VERSION ""

NS_ :

BS_:

BU_: VMCU TECU OBDScanT2 IC3 HPCU EMS ECUspare2 ECUspare1 DACU CIOM BBM

BO_ 1414 HMIIOM_BB2_19P_EMS: 21 IC3
 SG_ GPSData_Altitude_ISig_4_586 : 144|16@1+ (0.125,-2500) [-2500|5691.875] "m"  EMS
 SG_ GPSData_Longitude_ISig_4_586 : 0|32@1+ (1E-007,-210) [-210|219.4967295] "deg"  EMS
 SG_ GPSData_HDOP_ISig_4_586 : 112|16@1+ (0.01,0) [0|655.35] ""  EMS
 SG_ GPSData_sg_UB_ISig_4_586 : 163|1@1+ (1,0) [0|1] ""  EMS
 SG_ GPSData_Direction_ISig_4_586 : 96|16@1+ (0.0078125,0) [0|511.9921875] "deg"  EMS
 SG_ GPSData_Time_ISig_4_586 : 64|32@1+ (1,0) [0|4294967295] "s"  EMS
 SG_ GPSData_VehSpeed_ISig_4_586 : 128|16@1+ (0.00390625,0) [0|255.99609375] "Km_per_h"  EMS
 SG_ GPSData_AntennaStat_ISig_4_586 : 160|3@1+ (1,0) [0|0] ""  EMS
 SG_ GPSData_Latitude_ISig_4_586 : 32|32@1+ (1E-007,-210) [-210|219.4967295] "deg"  EMS

BO_ 1382 HMIIOM_BB2_19P_DACU_FCM: 8 DACU
 SG_ HMIIOM_BB2_19P_FCS_566 : 0|64@1+ (1,0) [0|0] ""  IC3

BO_ 1381 HMIIOM_BB2_19P_DACU: 21 IC3
 SG_ GPSData_HDOP_ISig_4_565 : 112|16@1+ (0.01,0) [0|655.35] ""  DACU
 SG_ GPSData_VehSpeed_ISig_4_565 : 128|16@1+ (0.00390625,0) [0|255.99609375] "Km_per_h"  DACU
 SG_ GPSData_sg_UB_ISig_4_565 : 163|1@1+ (1,0) [0|1] ""  DACU
 SG_ GPSData_AntennaStat_ISig_4_565 : 160|3@1+ (1,0) [0|0] ""  DACU
 SG_ GPSData_Latitude_ISig_4_565 : 32|32@1+ (1E-007,-210) [-210|219.4967295] "deg"  DACU
 SG_ GPSData_Time_ISig_4_565 : 64|32@1+ (1,0) [0|4294967295] "s"  DACU
 SG_ GPSData_Direction_ISig_4_565 : 96|16@1+ (0.0078125,0) [0|511.9921875] "deg"  DACU
 SG_ GPSData_Longitude_ISig_4_565 : 0|32@1+ (1E-007,-210) [-210|219.4967295] "deg"  DACU
 SG_ GPSData_Altitude_ISig_4_565 : 144|16@1+ (0.125,-2500) [-2500|5691.875] "m"  DACU

BO_ 1387 HMIIOM_BB2_19P_CIOM_FCM: 8 CIOM
 SG_ HMIIOM_BB2_19P_FCS_56b : 0|64@1+ (1,0) [0|0] ""  IC3

BO_ 1386 HMIIOM_BB2_19P_CIOM: 21 IC3
 SG_ GPSData_HDOP_ISig_4_56a : 112|16@1+ (0.01,0) [0|655.35] ""  CIOM
 SG_ GPSData_Latitude_ISig_4_56a : 32|32@1+ (1E-007,-210) [-210|219.4967295] "deg"  CIOM
 SG_ GPSData_Time_ISig_4_56a : 64|32@1+ (1,0) [0|4294967295] "s"  CIOM
 SG_ GPSData_Direction_ISig_4_56a : 96|16@1+ (0.0078125,0) [0|511.9921875] "deg"  CIOM
 SG_ GPSData_sg_UB_ISig_4_56a : 163|1@1+ (1,0) [0|1] ""  CIOM
 SG_ GPSData_AntennaStat_ISig_4_56a : 160|3@1+ (1,0) [0|0] ""  CIOM
 SG_ GPSData_Longitude_ISig_4_56a : 0|32@1+ (1E-007,-210) [-210|219.4967295] "deg"  CIOM
 SG_ GPSData_VehSpeed_ISig_4_56a : 128|16@1+ (0.00390625,0) [0|255.99609375] "Km_per_h"  CIOM
 SG_ GPSData_Altitude_ISig_4_56a : 144|16@1+ (0.125,-2500) [-2500|5691.875] "m"  CIOM

BO_ 1385 HMIIOM_BB2_19P_BBM_FCM: 8 BBM
 SG_ HMIIOM_BB2_19P_FCS_569 : 0|64@1+ (1,0) [0|0] ""  IC3

BO_ 1384 HMIIOM_BB2_19P_BBM: 21 IC3
 SG_ GPSData_Time_ISig_4_568 : 64|32@1+ (1,0) [0|4294967295] "s"  BBM
 SG_ GPSData_HDOP_ISig_4_568 : 112|16@1+ (0.01,0) [0|655.35] ""  BBM
 SG_ GPSData_Direction_ISig_4_568 : 96|16@1+ (0.0078125,0) [0|511.9921875] "deg"  BBM
 SG_ GPSData_Longitude_ISig_4_568 : 0|32@1+ (1E-007,-210) [-210|219.4967295] "deg"  BBM
 SG_ GPSData_sg_UB_ISig_4_568 : 163|1@1+ (1,0) [0|1] ""  BBM
 SG_ GPSData_VehSpeed_ISig_4_568 : 128|16@1+ (0.00390625,0) [0|255.99609375] "Km_per_h"  BBM
 SG_ GPSData_Altitude_ISig_4_568 : 144|16@1+ (0.125,-2500) [-2500|5691.875] "m"  BBM
 SG_ GPSData_Latitude_ISig_4_568 : 32|32@1+ (1E-007,-210) [-210|219.4967295] "deg"  BBM
 SG_ GPSData_AntennaStat_ISig_4_568 : 160|3@1+ (1,0) [0|0] ""  BBM

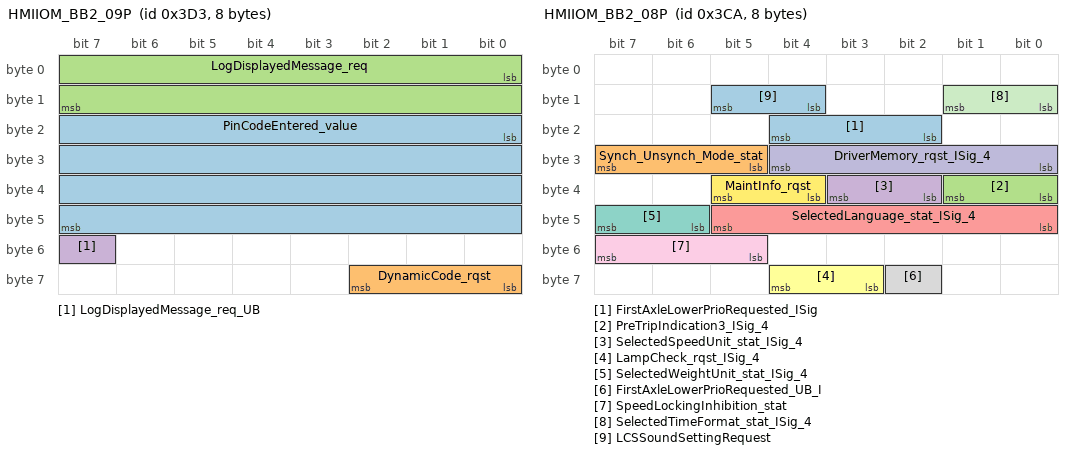
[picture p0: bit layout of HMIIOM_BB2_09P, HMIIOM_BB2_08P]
BO_ 979 HMIIOM_BB2_09P: 8 IC3
 SG_ PinCodeEntered_value : 16|32@1+ (1,0) [0|4294967295] "NotApplicable"  CIOM
 SG_ DynamicCode_rqst : 56|3@1+ (1,0) [0|0] ""  CIOM
 SG_ LogDisplayedMessage_req : 0|16@1+ (1,0) [0|65535] "NotApplicable"  VMCU
 SG_ LogDisplayedMessage_req_UB : 55|1@1+ (1,0) [0|0] ""  VMCU

BO_ 970 HMIIOM_BB2_08P: 8 IC3
 SG_ FirstAxleLowerPrioRequested_ISig : 18|3@1+ (1,0) [0|0] ""  VMCU
 SG_ Synch_Unsynch_Mode_stat : 29|3@1+ (1,0) [0|0] ""  CIOM
 SG_ PreTripIndication3_ISig_4 : 32|2@1+ (1,0) [0|0] ""  CIOM
 SG_ SelectedSpeedUnit_stat_ISig_4 : 34|2@1+ (1,0) [0|0] ""  VMCU
 SG_ SelectedLanguage_stat_ISig_4 : 40|6@1+ (1,0) [0|0] ""  BBM,CIOM
 SG_ LampCheck_rqst_ISig_4 : 59|2@1+ (1,0) [0|0] ""  VMCU
 SG_ SelectedWeightUnit_stat_ISig_4 : 46|2@1+ (1,0) [0|0] ""  CIOM
 SG_ FirstAxleLowerPrioRequested_UB_I : 58|1@1+ (1,0) [0|0] ""  VMCU
 SG_ SpeedLockingInhibition_stat : 53|3@1+ (1,0) [0|0] ""  CIOM
 SG_ DriverMemory_rqst_ISig_4 : 24|5@1+ (1,0) [0|0] ""  CIOM,VMCU
 SG_ SelectedTimeFormat_stat_ISig_4 : 8|2@1+ (1,0) [0|0] ""  CIOM
 SG_ MaintInfo_rqst : 36|2@1+ (1,0) [0|0] ""  VMCU
 SG_ LCSSoundSettingRequest : 12|2@1+ (1,0) [0|0] ""  DACU

BO_ 851 HMIIOM_BB2_07P: 8 IC3
 SG_ BunkBacklightCmd_ISig_4 : 16|5@1+ (1,0) [0|0] ""  CIOM

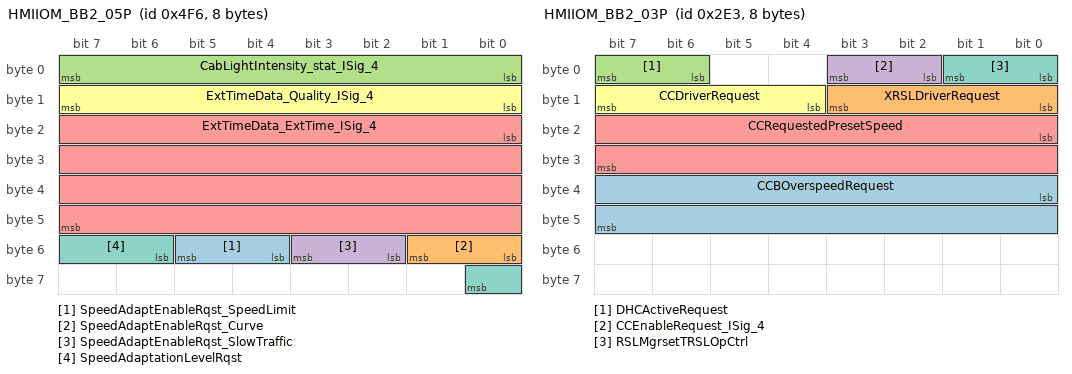
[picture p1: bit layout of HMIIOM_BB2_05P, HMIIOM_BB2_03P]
BO_ 1270 HMIIOM_BB2_05P: 8 IC3
 SG_ SpeedAdaptEnableRqst_SpeedLimit : 52|2@1+ (1,0) [0|0] ""  DACU,TECU
 SG_ SpeedAdaptEnableRqst_Curve : 48|2@1+ (1,0) [0|0] ""  TECU,DACU
 SG_ CabLightIntensity_stat_ISig_4 : 0|8@1+ (0.4,0) [0|102] "Percent"  BBM,DACU
 SG_ SpeedAdaptEnableRqst_SlowTraffic : 50|2@1+ (1,0) [0|0] ""  DACU,TECU
 SG_ ExtTimeData_ExtTime_ISig_4 : 16|32@1+ (1,0) [0|4294967295] "s"  VMCU
 SG_ ExtTimeData_Quality_ISig_4 : 8|8@1+ (1,0) [0|255] "h"  VMCU
 SG_ SpeedAdaptationLevelRqst : 54|3@1+ (1,0) [0|0] ""  DACU,TECU

BO_ 739 HMIIOM_BB2_03P: 8 IC3
 SG_ CCBOverspeedRequest : 32|16@1+ (0.00390625,0) [0|255.99609375] "Km_per_h"  VMCU
 SG_ XRSLDriverRequest : 8|4@1+ (1,0) [0|0] ""  VMCU
 SG_ DHCActiveRequest : 6|2@1+ (1,0) [0|0] ""  VMCU
 SG_ CCEnableRequest_ISig_4 : 2|2@1+ (1,0) [0|0] ""  CIOM,VMCU,BBM
 SG_ CCRequestedPresetSpeed : 16|16@1+ (0.00390625,0) [0|255.99609375] "Km_per_h"  VMCU
 SG_ CCDriverRequest : 12|4@1+ (1,0) [0|0] ""  VMCU,BBM
 SG_ RSLMgrsetTRSLOpCtrl : 0|2@1+ (1,0) [0|0] ""  VMCU

BO_ 390 HMIIOM_BB2_02P: 8 IC3
 SG_ EcoRollEnableRequest_ISig_4 : 6|2@1+ (1,0) [0|0] ""  TECU
 SG_ SelectedEcoCruiseLevel_ISig_4 : 40|3@1+ (1,0) [0|0] ""  EMS,DACU,TECU,VMCU

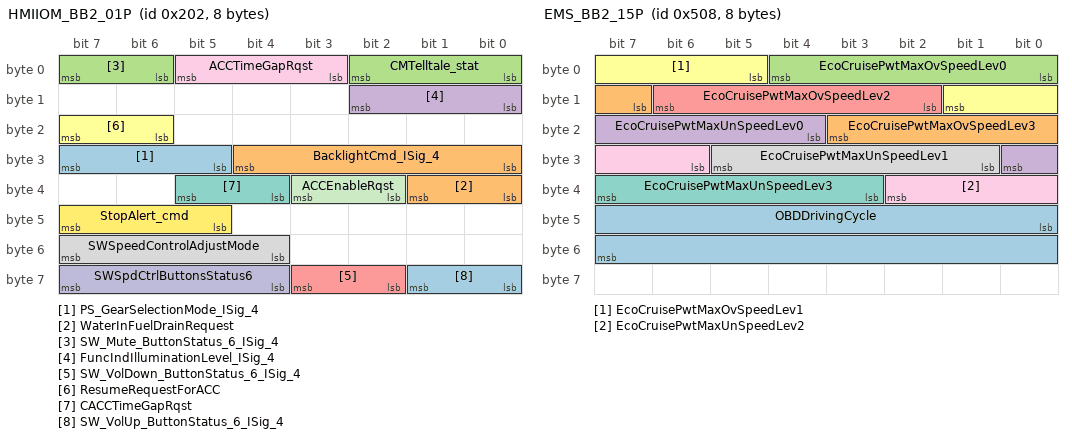
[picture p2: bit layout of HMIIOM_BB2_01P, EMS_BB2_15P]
BO_ 514 HMIIOM_BB2_01P: 8 IC3
 SG_ PS_GearSelectionMode_ISig_4 : 29|3@1+ (1,0) [0|0] ""  VMCU
 SG_ WaterInFuelDrainRequest : 32|2@1+ (1,0) [0|0] ""  EMS
 SG_ SW_Mute_ButtonStatus_6_ISig_4 : 6|2@1+ (1,0) [0|0] ""  BBM
 SG_ FuncIndIlluminationLevel_ISig_4 : 8|3@1+ (1,0) [0|0] ""  DACU,VMCU,CIOM
 SG_ SW_VolDown_ButtonStatus_6_ISig_4 : 58|2@1+ (1,0) [0|0] ""  BBM
 SG_ ResumeRequestForACC : 22|2@1+ (1,0) [0|0] ""  DACU
 SG_ CACCTimeGapRqst : 36|2@1+ (1,0) [0|0] ""  DACU
 SG_ SWSpeedControlAdjustMode : 52|4@1+ (1,0) [0|0] ""  VMCU,CIOM
 SG_ ACCTimeGapRqst : 3|3@1+ (1,0) [0|0] ""  DACU
 SG_ SWSpdCtrlButtonsStatus6 : 60|4@1+ (1,0) [0|0] ""  CIOM,BBM
 SG_ ACCEnableRqst : 34|2@1+ (1,0) [0|0] ""  VMCU,DACU,CIOM
 SG_ StopAlert_cmd : 45|3@1+ (1,0) [0|0] ""  VMCU
 SG_ SW_VolUp_ButtonStatus_6_ISig_4 : 56|2@1+ (1,0) [0|0] ""  BBM
 SG_ BacklightCmd_ISig_4 : 24|5@1+ (1,0) [0|0] ""  CIOM,DACU,VMCU
 SG_ CMTelltale_stat : 0|3@1+ (1,0) [0|0] ""  DACU

BO_ 1288 EMS_BB2_15P: 8 EMS
 SG_ OBDDrivingCycle : 40|16@1+ (1,0) [0|0] ""  VMCU
 SG_ EcoCruisePwtMaxOvSpeedLev3 : 15|5@1+ (1,0) [0|31] "Km_per_h"  VMCU
 SG_ EcoCruisePwtMaxOvSpeedLev0 : 0|5@1+ (1,0) [0|31] "Km_per_h"  VMCU
 SG_ EcoCruisePwtMaxUnSpeedLev0 : 20|5@1+ (1,0) [0|31] "Km_per_h"  VMCU
 SG_ EcoCruisePwtMaxOvSpeedLev2 : 10|5@1+ (1,0) [0|31] "Km_per_h"  VMCU
 SG_ EcoCruisePwtMaxOvSpeedLev1 : 5|5@1+ (1,0) [0|31] "Km_per_h"  VMCU
 SG_ EcoCruisePwtMaxUnSpeedLev3 : 35|5@1+ (1,0) [0|31] "Km_per_h"  VMCU
 SG_ EcoCruisePwtMaxUnSpeedLev1 : 25|5@1+ (1,0) [0|31] "Km_per_h"  VMCU
 SG_ EcoCruisePwtMaxUnSpeedLev2 : 30|5@1+ (1,0) [0|31] "Km_per_h"  VMCU

BO_ 1285 EMS_BB2_14P: 8 EMS
 SG_ TotPTOLNGHighAccuracy : 0|32@1+ (0.01,0) [0|42949672.95] "kg"  VMCU

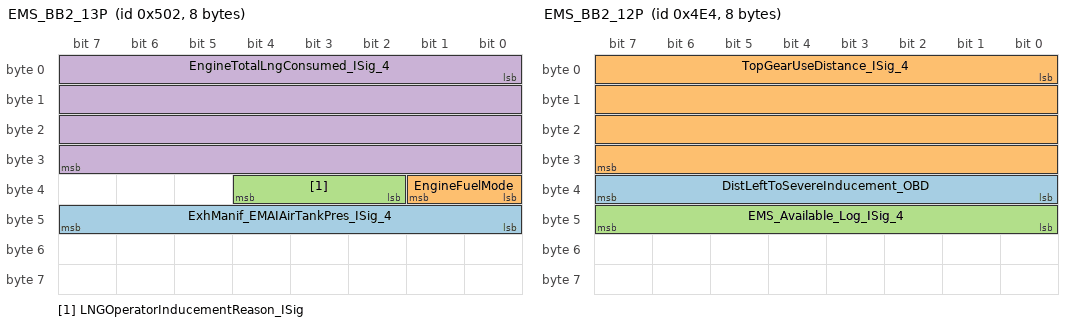
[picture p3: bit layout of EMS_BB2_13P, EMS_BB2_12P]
BO_ 1282 EMS_BB2_13P: 8 EMS
 SG_ ExhManif_EMAIAirTankPres_ISig_4 : 40|8@1+ (8,0) [0|2040] "kPa"  VMCU
 SG_ EngineFuelMode : 32|2@1+ (1,0) [0|0] ""  VMCU
 SG_ LNGOperatorInducementReason_ISig : 34|3@1+ (1,0) [0|0] ""  IC3
 SG_ EngineTotalLngConsumed_ISig_4 : 0|32@1+ (0.01,0) [0|42949672.95] "kg"  CIOM,IC3,VMCU

BO_ 1252 EMS_BB2_12P: 8 EMS
 SG_ DistLeftToSevereInducement_OBD : 32|8@1+ (5,0) [0|1275] "km"  IC3
 SG_ TopGearUseDistance_ISig_4 : 0|32@1+ (0.01,0) [0|42949672.95] "km"  IC3
 SG_ EMS_Available_Log_ISig_4 : 40|8@1+ (1,0) [0|0] ""  IC3

BO_ 961 EMS_BB2_11S_FCM: 8 CIOM
 SG_ EMS_BB2_11S_FCS : 0|64@1+ (1,0) [0|0] ""  EMS

BO_ 958 EMS_BB2_11S: 16 EMS
 SG_ KeyID_EngineStartAuth : 0|128@1+ (1,0) [0|0] ""  CIOM

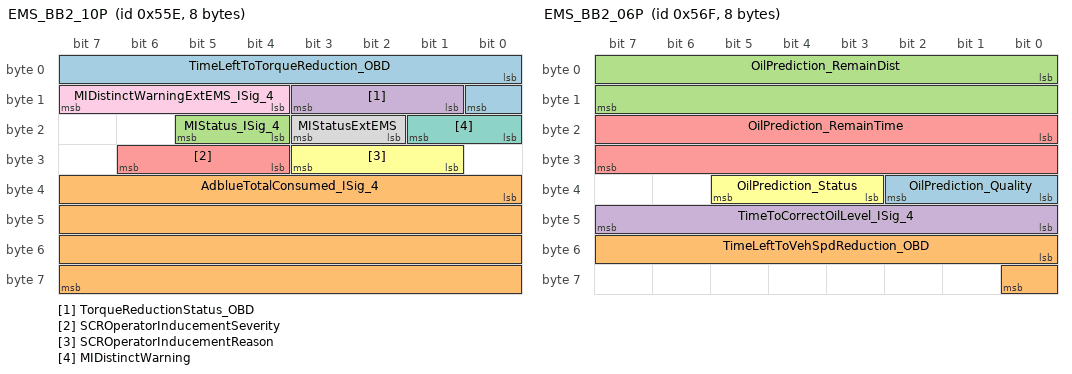
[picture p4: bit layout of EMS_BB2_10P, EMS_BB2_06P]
BO_ 1374 EMS_BB2_10P: 8 EMS
 SG_ TimeLeftToTorqueReduction_OBD : 0|9@1+ (12,0) [0|6132] "min"  IC3
 SG_ AdblueTotalConsumed_ISig_4 : 32|32@1+ (0.01,0) [0|42949672.95] "l"  VMCU,IC3
 SG_ MIStatus_ISig_4 : 20|2@1+ (1,0) [0|0] ""  VMCU,IC3
 SG_ TorqueReductionStatus_OBD : 9|3@1+ (1,0) [0|0] ""  IC3
 SG_ SCROperatorInducementSeverity : 28|3@1+ (1,0) [0|0] ""  IC3
 SG_ SCROperatorInducementReason : 25|3@1+ (1,0) [0|0] ""  IC3
 SG_ MIDistinctWarning : 16|2@1+ (1,0) [0|0] ""  VMCU,IC3
 SG_ MIStatusExtEMS : 18|2@1+ (1,0) [0|0] ""  IC3
 SG_ MIDistinctWarningExtEMS_ISig_4 : 12|4@1+ (1,0) [0|0] ""  VMCU,IC3

BO_ 1342 EMS_BB2_09S_FCM: 8 CIOM
 SG_ EMS_BB2_09S_FCS : 0|64@1+ (1,0) [0|0] ""  EMS

BO_ 1341 EMS_BB2_09S: 11 EMS
 SG_ ECU4VIN_stat : 0|88@1+ (1,0) [0|0] ""  CIOM

BO_ 1392 EMS_BB2_08P: 8 EMS
 SG_ EngineRunningTime_ISig_4 : 0|32@1+ (1,0) [0|4294967295] "s"  BBM,IC3,VMCU,CIOM
 SG_ TotPTOFuelHighAccuracy : 32|32@1+ (0.01,0) [0|42949672.95] "l"  VMCU

BO_ 1391 EMS_BB2_06P: 8 EMS
 SG_ OilPrediction_Quality : 32|3@1+ (1,0) [0|0] ""  CIOM,VMCU
 SG_ TimeLeftToVehSpdReduction_OBD : 48|9@1+ (15,0) [0|7665] "min"  IC3
 SG_ OilPrediction_RemainDist : 0|16@1+ (10,0) [0|655350] "km"  CIOM,VMCU
 SG_ TimeToCorrectOilLevel_ISig_4 : 40|8@1+ (1,0) [0|255] "min"  IC3
 SG_ OilPrediction_RemainTime : 16|16@1+ (1,0) [0|65535] "h"  VMCU,CIOM
 SG_ OilPrediction_Status : 35|3@1+ (1,0) [0|0] ""  CIOM,VMCU

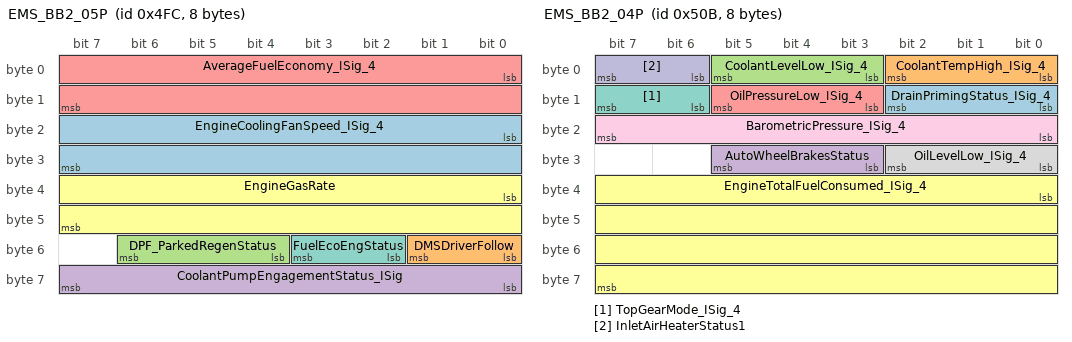
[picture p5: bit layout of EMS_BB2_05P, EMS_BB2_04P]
BO_ 1276 EMS_BB2_05P: 8 EMS
 SG_ EngineCoolingFanSpeed_ISig_4 : 16|16@1+ (1,0) [0|65535] "rpm"  CIOM
 SG_ DMSDriverFollow : 48|2@1+ (1,0) [0|0] ""  VMCU
 SG_ DPF_ParkedRegenStatus : 52|3@1+ (1,0) [0|0] ""  IC3
 SG_ CoolantPumpEngagementStatus_ISig : 56|8@1+ (0.4,0) [0|102] "Percent"  CIOM
 SG_ AverageFuelEconomy_ISig_4 : 0|16@1+ (0.00390625,0) [0|255.99609375] "miles_per_gallon"  IC3
 SG_ EngineGasRate : 32|16@1+ (0.05,0) [0|3276.75] "Kg_per_h"  VMCU,CIOM
 SG_ FuelEcoEngStatus : 50|2@1+ (1,0) [0|0] ""  VMCU

BO_ 1291 EMS_BB2_04P: 8 EMS
 SG_ DrainPrimingStatus_ISig_4 : 8|3@1+ (1,0) [0|0] ""  IC3
 SG_ CoolantTempHigh_ISig_4 : 0|3@1+ (1,0) [0|0] ""  IC3,VMCU,BBM
 SG_ CoolantLevelLow_ISig_4 : 3|3@1+ (1,0) [0|0] ""  VMCU,BBM,IC3
 SG_ AutoWheelBrakesStatus : 27|3@1+ (1,0) [0|0] ""  IC3,TECU
 SG_ OilPressureLow_ISig_4 : 11|3@1+ (1,0) [0|0] ""  VMCU,IC3,BBM
 SG_ EngineTotalFuelConsumed_ISig_4 : 32|32@1+ (0.01,0) [0|42949672.95] "l"  IC3,BBM,CIOM,VMCU,TECU
 SG_ TopGearMode_ISig_4 : 14|2@1+ (1,0) [0|0] ""  IC3
 SG_ OilLevelLow_ISig_4 : 24|3@1+ (1,0) [0|0] ""  IC3,BBM
 SG_ BarometricPressure_ISig_4 : 16|8@1+ (0.5,0) [0|127.5] "kPa"  TECU,BBM,VMCU,CIOM
 SG_ InletAirHeaterStatus1 : 6|2@1+ (1,0) [0|0] ""  IC3

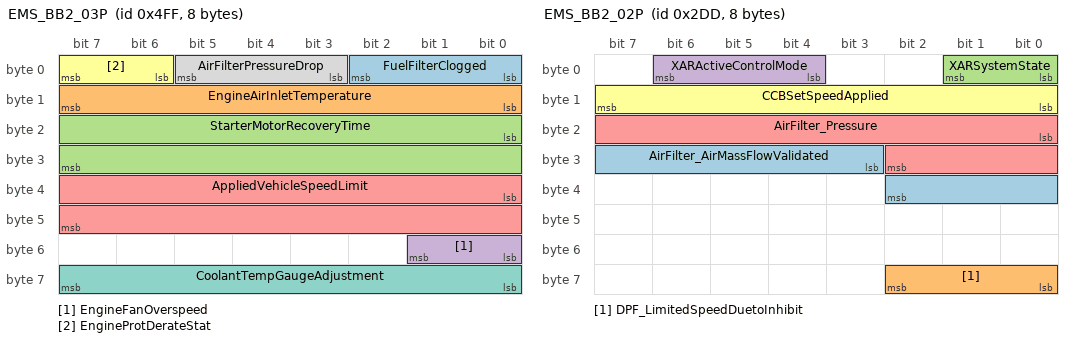
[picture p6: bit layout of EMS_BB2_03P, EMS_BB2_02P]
BO_ 1279 EMS_BB2_03P: 8 EMS
 SG_ FuelFilterClogged : 0|3@1+ (1,0) [0|0] ""  IC3
 SG_ EngineAirInletTemperature : 8|8@1+ (1,-40) [-40|215] "DegreeC"  VMCU
 SG_ StarterMotorRecoveryTime : 16|16@1+ (1,0) [0|65535] "s"  IC3
 SG_ EngineFanOverspeed : 48|2@1+ (1,0) [0|0] ""  IC3
 SG_ AppliedVehicleSpeedLimit : 32|16@1+ (0.00390625,0) [0|255.99609375] "Km_per_h"  VMCU,TECU
 SG_ EngineProtDerateStat : 6|2@1+ (1,0) [0|0] ""  VMCU
 SG_ CoolantTempGaugeAdjustment : 56|8@1+ (0.4,0) [0|102] "Percent"  IC3
 SG_ AirFilterPressureDrop : 3|3@1+ (1,0) [0|0] ""  VMCU

BO_ 733 EMS_BB2_02P: 8 EMS
 SG_ AirFilter_AirMassFlowValidated : 27|8@1+ (0.01,0) [0|2.55] "Kg_Per_s"  VMCU
 SG_ DPF_LimitedSpeedDuetoInhibit : 56|3@1+ (1,0) [0|0] ""  IC3
 SG_ XARSystemState : 0|2@1+ (1,0) [0|0] ""  DACU
 SG_ XARActiveControlMode : 4|3@1+ (1,0) [0|0] ""  DACU
 SG_ AirFilter_Pressure : 16|11@1+ (0.01,-10) [-10|10.47] "kPa"  VMCU
 SG_ CCBSetSpeedApplied : 8|8@1+ (1,0) [0|255] "Km_per_h"  VMCU,DACU

BO_ 719 EMS_BB2_01P: 8 EMS
 SG_ CCControllerMode_ISig_4 : 0|3@1+ (1,0) [0|0] ""  VMCU,IC3
 SG_ CrankcasePressureHigh_ISig_4 : 30|2@1+ (1,0) [0|0] ""  BBM
 SG_ EngineSystemPowerDownAck : 28|2@1+ (1,0) [0|0] ""  VMCU
 SG_ EngineActiveStatus_ISig_4 : 24|4@1+ (1,0) [0|0] ""  TECU,VMCU,DACU
 SG_ XRSLControllerMode : 19|2@1+ (1,0) [0|0] ""  VMCU,IC3
 SG_ RegenInhibDueHeight : 60|2@1+ (1,0) [0|0] ""  IC3
 SG_ ExhManif_AirInjActive_ISig_4 : 56|2@1+ (1,0) [0|0] ""  VMCU
 SG_ CCBControllerMode : 11|3@1+ (1,0) [0|0] ""  VMCU
 SG_ InhibitIdleShutdownStatus : 8|3@1+ (1,0) [0|0] ""  VMCU
 SG_ EngCompartmentStopSwitchStat : 6|2@1+ (1,0) [0|0] ""  VMCU
 SG_ EngineAirInletPressure : 32|8@1+ (2,0) [0|510] "kPa"  VMCU
 SG_ EngineStartAuth_rqst : 3|3@1+ (1,0) [0|0] ""  CIOM
 SG_ IntakeAirTemperatureAlert : 14|2@1+ (1,0) [0|0] ""  VMCU
 SG_ EngineOilTempHigh_ISig_4 : 16|3@1+ (1,0) [0|0] ""  BBM,IC3
 SG_ WarmUpCycle : 21|2@1+ (1,0) [0|0] ""  VMCU
 SG_ DeterminedGear : 48|8@1+ (1,-125) [-125|130] "GearValue"  VMCU
 SG_ CCSetSpeedApplied_ISig_4 : 40|8@1+ (1,0) [0|255] "Km_per_h"  IC3,DACU,VMCU

BO_ 2671964911 DiagUUDTRespMsg1_F2_EF_BB2: 8 HPCU
 SG_ DiagUUDTRespSig_F2_EF_ISig_4 : 0|64@1+ (1,0) [0|0] ""  VMCU

BO_ 2671964902 DiagUUDTRespMsg1_F2_E6_BB2: 8 BBM
 SG_ DiagUUDTRespSig_F2_E6_ISig_4 : 0|64@1+ (1,0) [0|0] ""  VMCU

BO_ 2671964901 DiagUUDTRespMsg1_F2_E5_BB2: 8 BBM
 SG_ DiagUUDTRespSig_F2_E5_ISig_4 : 0|64@1+ (1,0) [0|0] ""  VMCU

BO_ 2671964866 DiagUUDTRespMsg1_F2_C2_BB2: 8 HPCU
 SG_ DiagUUDTRespSig_F2_C2_ISig_4 : 0|64@1+ (1,0) [0|0] ""  VMCU

BO_ 2671964864 DiagUUDTRespMsg1_F2_C0_BB2: 8 CIOM
 SG_ DiagUUDTRespSig_F2_C0_ISig_4 : 0|64@1+ (1,0) [0|0] ""  VMCU

BO_ 2671964834 DiagUUDTRespMsg1_F2_A2_BB2: 8 CIOM
 SG_ DiagUUDTRespSig_F2_A2_ISig_4 : 0|64@1+ (1,0) [0|0] ""  VMCU

BO_ 2671964833 DiagUUDTRespMsg1_F2_A1_BB2: 8 CIOM
 SG_ DiagUUDTRespSig_F2_A1_ISig_4 : 0|64@1+ (1,0) [0|0] ""  VMCU

BO_ 2671964832 DiagUUDTRespMsg1_F2_A0_BB2: 8 CIOM
 SG_ DiagUUDTRespSig_F2_A0_ISig_4 : 0|64@1+ (1,0) [0|0] ""  VMCU

BO_ 2671964824 DiagUUDTRespMsg1_F2_98_BB2: 8 CIOM
 SG_ DiagUUDTRespSig_F2_98_ISig_4 : 0|64@1+ (1,0) [0|0] ""  VMCU

BO_ 2671964812 DiagUUDTRespMsg1_F2_8C_BB2: 8 DACU
 SG_ DiagUUDTRespSig_F2_8C_ISig_4 : 0|64@1+ (1,0) [0|0] ""  VMCU

BO_ 2671964803 DiagUUDTRespMsg1_F2_83_BB2: 8 IC3
 SG_ DiagUUDTRespSig_F2_83_ISig_4 : 0|64@1+ (1,0) [0|0] ""  VMCU

BO_ 2671964802 DiagUUDTRespMsg1_F2_82_BB2: 8 IC3
 SG_ DiagUUDTRespSig_F2_82_ISig_4 : 0|64@1+ (1,0) [0|0] ""  VMCU

BO_ 2671964772 DiagUUDTRespMsg1_F2_64_BB2: 8 IC3
 SG_ DiagUUDTRespSig_F2_64_ISig_4 : 0|64@1+ (1,0) [0|0] ""  VMCU

BO_ 2671964769 DiagUUDTRespMsg1_F2_61_BB2: 8 IC3
 SG_ DiagUUDTRespSig_F2_61_ISig_4 : 0|64@1+ (1,0) [0|0] ""  VMCU

BO_ 2671964768 DiagUUDTRespMsg1_F2_60_BB2: 8 IC3
 SG_ DiagUUDTRespSig_F2_60_ISig_4 : 0|64@1+ (1,0) [0|0] ""  VMCU

BO_ 2671964755 DiagUUDTRespMsg1_F2_53_BB2: 8 CIOM
 SG_ DiagUUDTRespSig_F2_53_ISig_4 : 0|64@1+ (1,0) [0|0] ""  VMCU

BO_ 2671964754 DiagUUDTRespMsg1_F2_52_BB2: 8 DACU
 SG_ DiagUUDTRespSig_F2_52_ISig_4 : 0|64@1+ (1,0) [0|0] ""  VMCU

BO_ 2671964753 DiagUUDTRespMsg1_F2_51_BB2: 8 DACU
 SG_ DiagUUDTRespSig_F2_51_ISig_4 : 0|64@1+ (1,0) [0|0] ""  VMCU

BO_ 2671964752 DiagUUDTRespMsg1_F2_50_BB2: 8 DACU
 SG_ DiagUUDTRespSig_F2_50_ISig_4 : 0|64@1+ (1,0) [0|0] ""  VMCU

BO_ 2671964737 DiagUUDTRespMsg1_F2_41_BB2: 8 IC3
 SG_ DiagUUDTRespSig_F2_41_ISig_4 : 0|64@1+ (1,0) [0|0] ""  VMCU

BO_ 2671964736 DiagUUDTRespMsg1_F2_40_BB2: 8 CIOM
 SG_ DiagUUDTRespSig_F2_40_ISig_4 : 0|64@1+ (1,0) [0|0] ""  VMCU

BO_ 2671964710 DiagUUDTRespMsg1_F2_26_BB2: 8 CIOM
 SG_ DiagUUDTRespSig_F2_26_ISig_4 : 0|64@1+ (1,0) [0|0] ""  VMCU

BO_ 2671964696 DiagUUDTRespMsg1_F2_18_BB2: 8 TECU
 SG_ DiagUUDTRespSig_F2_18_ISig_4 : 0|64@1+ (1,0) [0|0] ""  VMCU

BO_ 2671964688 DiagUUDTRespMsg1_F2_10_BB2: 8 EMS
 SG_ DiagUUDTRespSig_F2_10_ISig_4 : 0|64@1+ (1,0) [0|0] ""  VMCU

BO_ 2671834277 DiagRespMsgIntTGW_F4_A5_BB2: 8 VMCU
 SG_ InternalTesterDiagSig_F4_A5_ISig : 0|64@1+ (1,0) [0|0] ""  IC3

BO_ 2671834227 DiagRespMsgIntTGW_F4_73_BB2: 8 VMCU
 SG_ InternalTesterDiagSig_F4_73_ISig : 0|64@1+ (1,0) [0|0] ""  IC3

BO_ 2671834213 DiagRespMsgIntTGW_F4_65_BB2: 8 VMCU
 SG_ InternalTesterDiagSig_F4_65_ISig : 0|64@1+ (1,0) [0|0] ""  IC3

BO_ 2671834168 DiagRespMsgIntTGW_F4_38_BB2: 8 VMCU
 SG_ InternalTesterDiagSig_F4_38_ISig : 0|64@1+ (1,0) [0|0] ""  IC3

BO_ 2671834351 DiagRespMsgIntTGW2_F4_EF_BB2: 8 HPCU
 SG_ InternalTesterDiagSig_F4_EF_ISig : 0|64@1+ (1,0) [0|0] ""  IC3

BO_ 2671834342 DiagRespMsgIntTGW2_F4_E6_BB2: 8 BBM
 SG_ InternalTesterDiagSig_F4_E6_ISig : 0|64@1+ (1,0) [0|0] ""  IC3

BO_ 2671834341 DiagRespMsgIntTGW2_F4_E5_BB2: 8 BBM
 SG_ InternalTesterDiagSig_F4_E5_ISig : 0|64@1+ (1,0) [0|0] ""  IC3

BO_ 2671834306 DiagRespMsgIntTGW2_F4_C2_BB2: 8 HPCU
 SG_ InternalTesterDiagSig_F4_C2_ISig : 0|64@1+ (1,0) [0|0] ""  IC3

BO_ 2671834304 DiagRespMsgIntTGW2_F4_C0_BB2: 8 CIOM
 SG_ InternalTesterDiagSig_F4_C0_ISig : 0|64@1+ (1,0) [0|0] ""  IC3

BO_ 2671834274 DiagRespMsgIntTGW2_F4_A2_BB2: 8 CIOM
 SG_ InternalTesterDiagSig_F4_A2_ISig : 0|64@1+ (1,0) [0|0] ""  IC3

BO_ 2671834273 DiagRespMsgIntTGW2_F4_A1_BB2: 8 CIOM
 SG_ InternalTesterDiagSig_F4_A1_ISig : 0|64@1+ (1,0) [0|0] ""  IC3

BO_ 2671834272 DiagRespMsgIntTGW2_F4_A0_BB2: 8 CIOM
 SG_ InternalTesterDiagSig_F4_A0_ISig : 0|64@1+ (1,0) [0|0] ""  IC3

BO_ 2671834264 DiagRespMsgIntTGW2_F4_98_BB2: 8 CIOM
 SG_ InternalTesterDiagSig_F4_98_ISig : 0|64@1+ (1,0) [0|0] ""  IC3

BO_ 2671834252 DiagRespMsgIntTGW2_F4_8C_BB2: 8 DACU
 SG_ InternalTesterDiagSig_F4_8C_ISig : 0|64@1+ (1,0) [0|0] ""  IC3

BO_ 2671834226 DiagRespMsgIntTGW2_F4_72_BB2: 8 VMCU
 SG_ InternalTesterDiagSig_F4_72_ISig : 0|64@1+ (1,0) [0|0] ""  IC3

BO_ 2671834225 DiagRespMsgIntTGW2_F4_71_BB2: 8 VMCU
 SG_ InternalTesterDiagSig_F4_71_ISig : 0|64@1+ (1,0) [0|0] ""  IC3

BO_ 2671834195 DiagRespMsgIntTGW2_F4_53_BB2: 8 CIOM
 SG_ InternalTesterDiagSig_F4_53_ISig : 0|64@1+ (1,0) [0|0] ""  IC3

BO_ 2671834194 DiagRespMsgIntTGW2_F4_52_BB2: 8 DACU
 SG_ InternalTesterDiagSig_F4_52_ISig : 0|64@1+ (1,0) [0|0] ""  IC3

BO_ 2671834193 DiagRespMsgIntTGW2_F4_51_BB2: 8 DACU
 SG_ InternalTesterDiagSig_F4_51_ISig : 0|64@1+ (1,0) [0|0] ""  IC3

BO_ 2671834192 DiagRespMsgIntTGW2_F4_50_BB2: 8 DACU
 SG_ InternalTesterDiagSig_F4_50_ISig : 0|64@1+ (1,0) [0|0] ""  IC3

BO_ 2671834176 DiagRespMsgIntTGW2_F4_40_BB2: 8 CIOM
 SG_ InternalTesterDiagSig_F4_40_ISig : 0|64@1+ (1,0) [0|0] ""  IC3

BO_ 2671834161 DiagRespMsgIntTGW2_F4_31_BB2: 8 VMCU
 SG_ InternalTesterDiagSig_F4_31_ISig : 0|64@1+ (1,0) [0|0] ""  IC3

BO_ 2671834160 DiagRespMsgIntTGW2_F4_30_BB2: 8 VMCU
 SG_ InternalTesterDiagSig_F4_30_ISig : 0|64@1+ (1,0) [0|0] ""  IC3

BO_ 2671834150 DiagRespMsgIntTGW2_F4_26_BB2: 8 CIOM
 SG_ InternalTesterDiagSig_F4_26_ISig : 0|64@1+ (1,0) [0|0] ""  IC3

BO_ 2671834149 DiagRespMsgIntTGW2_F4_25_BB2: 8 VMCU
 SG_ InternalTesterDiagSig_F4_25_ISig : 0|64@1+ (1,0) [0|0] ""  IC3

BO_ 2671834148 DiagRespMsgIntTGW2_F4_24_BB2: 8 VMCU
 SG_ InternalTesterDiagSig_F4_24_ISig : 0|64@1+ (1,0) [0|0] ""  IC3

BO_ 2671834147 DiagRespMsgIntTGW2_F4_23_BB2: 8 VMCU
 SG_ InternalTesterDiagSig_F4_23_ISig : 0|64@1+ (1,0) [0|0] ""  IC3

BO_ 2671834146 DiagRespMsgIntTGW2_F4_22_BB2: 8 VMCU
 SG_ InternalTesterDiagSig_F4_22_ISig : 0|64@1+ (1,0) [0|0] ""  IC3

BO_ 2671834145 DiagRespMsgIntTGW2_F4_21_BB2: 8 VMCU
 SG_ InternalTesterDiagSig_F4_21_ISig : 0|64@1+ (1,0) [0|0] ""  IC3

BO_ 2671834144 DiagRespMsgIntTGW2_F4_20_BB2: 8 VMCU
 SG_ InternalTesterDiagSig_F4_20_ISig : 0|64@1+ (1,0) [0|0] ""  IC3

BO_ 2671834138 DiagRespMsgIntTGW2_F4_1A_BB2: 8 VMCU
 SG_ InternalTesterDiagSig_F4_1A_ISig : 0|64@1+ (1,0) [0|0] ""  IC3

BO_ 2671834136 DiagRespMsgIntTGW2_F4_18_BB2: 8 TECU
 SG_ InternalTesterDiagSig_F4_18_ISig : 0|64@1+ (1,0) [0|0] ""  IC3

BO_ 2671834128 DiagRespMsgIntTGW2_F4_10_BB2: 8 EMS
 SG_ InternalTesterDiagSig_F4_10_ISig : 0|64@1+ (1,0) [0|0] ""  IC3

BO_ 2671834095 DiagRespMsgIntIC_F3_EF_BB2: 8 HPCU
 SG_ InternalTesterDiagSig_F3_EF : 0|64@1+ (1,0) [0|0] ""  IC3

BO_ 2671834050 DiagRespMsgIntIC_F3_C2_BB2: 8 HPCU
 SG_ InternalTesterDiagSig_F3_C2 : 0|64@1+ (1,0) [0|0] ""  IC3

BO_ 2671834021 DiagRespMsgIntIC_F3_A5_BB2: 8 VMCU
 SG_ InternalTesterDiagSig_F3_A5_ISig : 0|64@1+ (1,0) [0|0] ""  IC3

BO_ 2671833971 DiagRespMsgIntIC_F3_73_BB2: 8 VMCU
 SG_ InternalTesterDiagSig_F3_73_ISig : 0|64@1+ (1,0) [0|0] ""  IC3

BO_ 2671833957 DiagRespMsgIntIC_F3_65_BB2: 8 VMCU
 SG_ InternalTesterDiagSig_F3_65_ISig : 0|64@1+ (1,0) [0|0] ""  IC3

BO_ 2671833912 DiagRespMsgIntIC_F3_38_BB2: 8 VMCU
 SG_ InternalTesterDiagSig_F3_38_ISig : 0|64@1+ (1,0) [0|0] ""  IC3

BO_ 2671834086 DiagRespMsgIntHMIIOM_F3_E6_BB2: 8 BBM
 SG_ InternalTesterDiagSig_F3_E6 : 0|64@1+ (1,0) [0|0] ""  IC3

BO_ 2671834085 DiagRespMsgIntHMIIOM_F3_E5_BB2: 8 BBM
 SG_ InternalTesterDiagSig_F3_E5_ISig : 0|64@1+ (1,0) [0|0] ""  IC3

BO_ 2671834048 DiagRespMsgIntHMIIOM_F3_C0_BB2: 8 CIOM
 SG_ InternalTesterDiagSig_F3_C0_ISig : 0|64@1+ (1,0) [0|0] ""  IC3

BO_ 2671834018 DiagRespMsgIntHMIIOM_F3_A2_BB2: 8 CIOM
 SG_ InternalTesterDiagSig_F3_A2_ISig : 0|64@1+ (1,0) [0|0] ""  IC3

BO_ 2671834017 DiagRespMsgIntHMIIOM_F3_A1_BB2: 8 CIOM
 SG_ InternalTesterDiagSig_F3_A1_ISig : 0|64@1+ (1,0) [0|0] ""  IC3

BO_ 2671834016 DiagRespMsgIntHMIIOM_F3_A0_BB2: 8 CIOM
 SG_ InternalTesterDiagSig_F3_A0_ISig : 0|64@1+ (1,0) [0|0] ""  IC3

BO_ 2671834008 DiagRespMsgIntHMIIOM_F3_98_BB2: 8 CIOM
 SG_ InternalTesterDiagSig_F3_98_ISig : 0|64@1+ (1,0) [0|0] ""  IC3

BO_ 2671833996 DiagRespMsgIntHMIIOM_F3_8C_BB2: 8 DACU
 SG_ InternalTesterDiagSig_F3_8C_ISig : 0|64@1+ (1,0) [0|0] ""  IC3

BO_ 2671833970 DiagRespMsgIntHMIIOM_F3_72_BB2: 8 VMCU
 SG_ InternalTesterDiagSig_F3_72_ISig : 0|64@1+ (1,0) [0|0] ""  IC3

BO_ 2671833969 DiagRespMsgIntHMIIOM_F3_71_BB2: 8 VMCU
 SG_ InternalTesterDiagSig_F3_71_ISig : 0|64@1+ (1,0) [0|0] ""  IC3

BO_ 2671833939 DiagRespMsgIntHMIIOM_F3_53_BB2: 8 CIOM
 SG_ InternalTesterDiagSig_F3_53_ISig : 0|64@1+ (1,0) [0|0] ""  IC3

BO_ 2671833938 DiagRespMsgIntHMIIOM_F3_52_BB2: 8 DACU
 SG_ InternalTesterDiagSig_F3_52_ISig : 0|64@1+ (1,0) [0|0] ""  IC3

BO_ 2671833937 DiagRespMsgIntHMIIOM_F3_51_BB2: 8 DACU
 SG_ InternalTesterDiagSig_F3_51_ISig : 0|64@1+ (1,0) [0|0] ""  IC3

BO_ 2671833936 DiagRespMsgIntHMIIOM_F3_50_BB2: 8 DACU
 SG_ InternalTesterDiagSig_F3_50 : 0|64@1+ (1,0) [0|0] ""  IC3

BO_ 2671833920 DiagRespMsgIntHMIIOM_F3_40_BB2: 8 CIOM
 SG_ InternalTesterDiagSig_F3_40 : 0|64@1+ (1,0) [0|0] ""  IC3

BO_ 2671833905 DiagRespMsgIntHMIIOM_F3_31_BB2: 8 VMCU
 SG_ InternalTesterDiagSig_F3_31_ISig : 0|64@1+ (1,0) [0|0] ""  IC3

BO_ 2671833904 DiagRespMsgIntHMIIOM_F3_30_BB2: 8 VMCU
 SG_ InternalTesterDiagSig_F3_30_ISig : 0|64@1+ (1,0) [0|0] ""  IC3

BO_ 2671833894 DiagRespMsgIntHMIIOM_F3_26_BB2: 8 CIOM
 SG_ InternalTesterDiagSig_F3_26_ISig : 0|64@1+ (1,0) [0|0] ""  IC3

BO_ 2671833893 DiagRespMsgIntHMIIOM_F3_25_BB2: 8 VMCU
 SG_ InternalTesterDiagSig_F3_25_ISig : 0|64@1+ (1,0) [0|0] ""  IC3

BO_ 2671833892 DiagRespMsgIntHMIIOM_F3_24_BB2: 8 VMCU
 SG_ InternalTesterDiagSig_F3_24 : 0|64@1+ (1,0) [0|0] ""  IC3

BO_ 2671833891 DiagRespMsgIntHMIIOM_F3_23_BB2: 8 VMCU
 SG_ InternalTesterDiagSig_F3_23_ISig : 0|64@1+ (1,0) [0|0] ""  IC3

BO_ 2671833890 DiagRespMsgIntHMIIOM_F3_22_BB2: 8 VMCU
 SG_ InternalTesterDiagSig_F3_22_ISig : 0|64@1+ (1,0) [0|0] ""  IC3

BO_ 2671833889 DiagRespMsgIntHMIIOM_F3_21_BB2: 8 VMCU
 SG_ InternalTesterDiagSig_F3_21_ISig : 0|64@1+ (1,0) [0|0] ""  IC3

BO_ 2671833888 DiagRespMsgIntHMIIOM_F3_20_BB2: 8 VMCU
 SG_ InternalTesterDiagSig_F3_20_ISig : 0|64@1+ (1,0) [0|0] ""  IC3

BO_ 2671833882 DiagRespMsgIntHMIIOM_F3_1A_BB2: 8 VMCU
 SG_ InternalTesterDiagSig_F3_1A_ISig : 0|64@1+ (1,0) [0|0] ""  IC3

BO_ 2671833880 DiagRespMsgIntHMIIOM_F3_18_BB2: 8 TECU
 SG_ InternalTesterDiagSig_F3_18 : 0|64@1+ (1,0) [0|0] ""  IC3

BO_ 2671833872 DiagRespMsgIntHMIIOM_F3_10_BB2: 8 EMS
 SG_ InternalTesterDiagSig_F3_10 : 0|64@1+ (1,0) [0|0] ""  IC3

BO_ 2671833076 DiagReqMsgIntTGW_EF_F4_BB2: 8 IC3
 SG_ InternalTesterDiagSig_EF_F4_ISig : 0|64@1+ (1,0) [0|0] ""  HPCU

BO_ 2671821556 DiagReqMsgIntTGW_C2_F4_BB2: 8 IC3
 SG_ InternalTesterDiagSig_C2_F4_ISig : 0|64@1+ (1,0) [0|0] ""  HPCU

BO_ 2671814132 DiagReqMsgIntTGW_A5_F4_BB2: 8 IC3
 SG_ InternalTesterDiagSig_A5_F4_ISig : 0|64@1+ (1,0) [0|0] ""  VMCU

BO_ 2671801332 DiagReqMsgIntTGW_73_F4_BB2: 8 IC3
 SG_ InternalTesterDiagSig_73_F4_ISig : 0|64@1+ (1,0) [0|0] ""  VMCU

BO_ 2671797748 DiagReqMsgIntTGW_65_F4_BB2: 8 IC3
 SG_ InternalTesterDiagSig_65_F4_ISig : 0|64@1+ (1,0) [0|0] ""  VMCU

BO_ 2671786228 DiagReqMsgIntTGW_38_F4_BB2: 8 IC3
 SG_ InternalTesterDiagSig_38_F4_ISig : 0|64@1+ (1,0) [0|0] ""  VMCU

BO_ 2671830772 DiagReqMsgIntTGW2_E6_F4_BB2: 8 IC3
 SG_ InternalTesterDiagSig_E6_F4_ISig : 0|64@1+ (1,0) [0|0] ""  BBM

BO_ 2671830516 DiagReqMsgIntTGW2_E5_F4_BB2: 8 IC3
 SG_ InternalTesterDiagSig_E5_F4_ISig : 0|64@1+ (1,0) [0|0] ""  BBM

BO_ 2671821044 DiagReqMsgIntTGW2_C0_F4_BB2: 8 IC3
 SG_ InternalTesterDiagSig_C0_F4_ISig : 0|64@1+ (1,0) [0|0] ""  CIOM

CM_ SG_ 1414 GPSData_Longitude_ISig_4_586 "4261412864-4278190079 Error ; 4278190080-4294967295 Not available";
CM_ SG_ 1414 GPSData_Time_ISig_4_586 "4261412864 - 4278190079 Error ; 4278190080 - 4294967295 Not available";
CM_ SG_ 1414 GPSData_VehSpeed_ISig_4_586 "65024 - 65279 Error ; 65280 - 65535 Not available";
CM_ SG_ 1414 GPSData_Latitude_ISig_4_586 "4261412864-4278190079 Error ; 4278190080-4294967295 Not available";
CM_ SG_ 1381 GPSData_VehSpeed_ISig_4_565 "65024 - 65279 Error ; 65280 - 65535 Not available";
CM_ SG_ 1381 GPSData_Latitude_ISig_4_565 "4261412864-4278190079 Error ; 4278190080-4294967295 Not available";
CM_ SG_ 1381 GPSData_Time_ISig_4_565 "4261412864 - 4278190079 Error ; 4278190080 - 4294967295 Not available";
CM_ SG_ 1381 GPSData_Longitude_ISig_4_565 "4261412864-4278190079 Error ; 4278190080-4294967295 Not available";
CM_ SG_ 1386 GPSData_Latitude_ISig_4_56a "4261412864-4278190079 Error ; 4278190080-4294967295 Not available";
CM_ SG_ 1386 GPSData_Time_ISig_4_56a "4261412864 - 4278190079 Error ; 4278190080 - 4294967295 Not available";
CM_ SG_ 1386 GPSData_Longitude_ISig_4_56a "4261412864-4278190079 Error ; 4278190080-4294967295 Not available";
CM_ SG_ 1386 GPSData_VehSpeed_ISig_4_56a "65024 - 65279 Error ; 65280 - 65535 Not available";
CM_ SG_ 1384 GPSData_Time_ISig_4_568 "4261412864 - 4278190079 Error ; 4278190080 - 4294967295 Not available";
CM_ SG_ 1384 GPSData_Longitude_ISig_4_568 "4261412864-4278190079 Error ; 4278190080-4294967295 Not available";
CM_ SG_ 1384 GPSData_VehSpeed_ISig_4_568 "65024 - 65279 Error ; 65280 - 65535 Not available";
CM_ SG_ 1384 GPSData_Latitude_ISig_4_568 "4261412864-4278190079 Error ; 4278190080-4294967295 Not available";
CM_ SG_ 1270 CabLightIntensity_stat_ISig_4 "254 Error ; 255 Not available";
CM_ SG_ 739 CCBOverspeedRequest "65024 - 65279 Error ; 65280 - 65535 Not available";
CM_ SG_ 739 CCRequestedPresetSpeed "65024 - 65279 Error ; 65280 - 65535 Not available";
CM_ SG_ 1282 EngineTotalLngConsumed_ISig_4 "4211081216 - 4261412863 Spare; 4261412864 - 4278190079 Error; 4278190080 - 4294967295 NotAvailable";
CM_ SG_ 1252 TopGearUseDistance_ISig_4 "4261412864 - 4278190079 Error ; 4278190080 - 4294967295 Not available";
CM_ SG_ 1374 TimeLeftToTorqueReduction_OBD "510 Error ; 511 Not available";
CM_ SG_ 1374 AdblueTotalConsumed_ISig_4 "4261412864 - 4278190079 Error ; 4278190080 - 4294967295 Not available";
CM_ SG_ 1392 EngineRunningTime_ISig_4 "4261412864 - 4278190079 Error ; 4278190080 - 4294967295 Not available";
CM_ SG_ 1392 TotPTOFuelHighAccuracy "4261412864 - 4278190079 Error ; 4278190080 - 4294967295 Not available";
CM_ SG_ 1391 OilPrediction_RemainDist "65024 - 65279 Error ; 65280 - 65535 Not available";
CM_ SG_ 1391 TimeToCorrectOilLevel_ISig_4 "254 Error ; 255 Not available";
CM_ SG_ 1391 OilPrediction_RemainTime "65024 - 65279 Error ; 65280 - 65535 Not available";
CM_ SG_ 1291 EngineTotalFuelConsumed_ISig_4 "4261412864 - 4278190079 Error ; 4278190080 - 4294967295 Not available";
CM_ SG_ 1291 BarometricPressure_ISig_4 "254 Error ; 255 Not available";
CM_ SG_ 1279 EngineAirInletTemperature "254 Error ; 255 Not available";
CM_ SG_ 1279 StarterMotorRecoveryTime "65024 - 65279 Error ; 65280 - 65535 Not available";
CM_ SG_ 1279 AppliedVehicleSpeedLimit "65024 - 65279 Error ; 65280 - 65535 Not available";
CM_ BO_ 733 "COM_MATRIX_1.7.0 Removed signals: XARActivePriority bit 2-3, XARAbilityMinAcceleration bit16-31, XARAbilityMaxAcceleration bit 32-47";
CM_ SG_ 719 EngineAirInletPressure "254 Error ; 255 Not available";
CM_ SG_ 719 DeterminedGear "254 Error ; 255 Not available";
CM_ SG_ 719 CCSetSpeedApplied_ISig_4 "254 Error ; 255 Not available";
CM_ BO_ 2671964768 "Note: old interface for HMIIOM, can be deleted when IC3 is configured with address 0x61.";
BA_DEF_ BO_  "GenMsgStartDelayTime" INT 0 0;
BA_DEF_ BO_  "GenMsgDelayTime" INT 0 0;
BA_DEF_ BO_  "GenMsgCycleTime" INT 0 0;
BA_DEF_ BO_  "GenMsgSendType" ENUM  "Cyclic","NotUsed","NotUsed","NotUsed","NotUsed","NotUsed","NotUsed","IfActive","NoMsgSendType","NotUsed";
BA_DEF_ SG_  "GenSigStartValue" INT 0 0;
BA_DEF_ SG_  "GenSigCycleTimeActive" INT 0 0;
BA_DEF_ SG_  "GenSigCycleTime" INT 0 0;
BA_DEF_ SG_  "GenSigSendType" ENUM  "Cyclic","OnWrite","OnWriteWithRepetition","OnChange","OnChangeWithRepetition","IfActive","IfActiveWithRepetition","NoSigSendType","NotUsed","NotUsed","NotUsed","NotUsed","NotUsed";
BA_DEF_ BO_  "VFrameFormat" ENUM  "StandardCAN","ExtendedCAN","reserved","J1939PG","reserved","reserved","reserved","reserved","reserved","reserved","reserved","reserved","reserved","reserved","StandardCAN_FD","ExtendedCAN_FD";
BA_DEF_ SG_  "SigType" ENUM  "Default","Range","RangeSigned","ASCII","Discrete","Control","ReferencePGN","DTC","StringDelimiter","StringLength","StringLengthControl";
BA_DEF_ SG_  "SeToolVersion_SIGNAL" STRING ;
BA_DEF_ SG_  "SeToolUniqueID_SIGNAL" STRING ;
BA_DEF_ SG_  "SeToolOwnerSigGroup_SIGNAL" STRING ;
BA_DEF_ SG_  "SeToolOwnerSigGroupID_SIGNAL" STRING ;
BA_DEF_ SG_  "SeToolName_SIGNAL" STRING ;
BA_DEF_ SG_  "SeToolItemID_SIGNAL" STRING ;
BA_DEF_ SG_  "SeToolAncestorID_SIGNAL" STRING ;
BA_DEF_ SG_  "Platform_VMCU1_Sig" ENUM  "No","Yes";
BA_DEF_ SG_  "Platform_FactoryIf_Sig" ENUM  "No","Yes";
BA_DEF_ BO_  "NmAsrMessage" ENUM  "No","Yes";
BA_DEF_ SG_  "NeedsUpdateBit" ENUM  "No","Yes";
BA_DEF_ SG_  "MmAnSignal" ENUM  "No","Yes";
BA_DEF_ SG_  "GenSigMaxLatency" INT 0 65535;
BA_DEF_ SG_  "GenSigILSupport" ENUM  "Yes","No";
BA_DEF_ BO_  "GenMsgILSupport" ENUM  "No","Yes";
BA_DEF_ BO_  "DiagUUDTResponse" ENUM  "No","Yes";
BA_DEF_ BO_  "DiagState" ENUM  "No","Yes";
BA_DEF_ BO_  "DiagResponse" ENUM  "No","Yes";
BA_DEF_ BO_  "DiagRequest" ENUM  "No","Yes";
BA_DEF_ BO_  "DiagConnection" HEX 0 65535;
BA_DEF_ BO_  "CanTpSTmin" INT 0 255;
BA_DEF_ BO_  "CanTpFcFrameId" HEX 0 2147483647;
BA_DEF_ BO_  "CanTpBs" INT 0 255;
BA_DEF_ SG_  "SystemSignalLongSymbol" STRING ;
BA_DEF_REL_ BU_SG_REL_  "GenSigTimeoutTime" INT 0 65535;
BA_DEF_REL_ BU_SG_REL_  "GenSigFirstTimeoutTime" INT 0 65535;
BA_DEF_DEF_  "GenMsgStartDelayTime" 0;
BA_DEF_DEF_  "GenMsgDelayTime" 0;
BA_DEF_DEF_  "GenMsgCycleTime" 0;
BA_DEF_DEF_  "GenMsgSendType" "Cyclic";
BA_DEF_DEF_  "GenSigStartValue" 0;
BA_DEF_DEF_  "GenSigCycleTimeActive" 0;
BA_DEF_DEF_  "GenSigCycleTime" 0;
BA_DEF_DEF_  "GenSigSendType" "Cyclic";
BA_DEF_DEF_  "VFrameFormat" "ExtendedCAN";
BA_DEF_DEF_  "SigType" "Default";
BA_DEF_DEF_  "SeToolVersion_SIGNAL" "";
BA_DEF_DEF_  "SeToolUniqueID_SIGNAL" "";
BA_DEF_DEF_  "SeToolOwnerSigGroup_SIGNAL" "";
BA_DEF_DEF_  "SeToolOwnerSigGroupID_SIGNAL" "";
BA_DEF_DEF_  "SeToolName_SIGNAL" "";
BA_DEF_DEF_  "SeToolItemID_SIGNAL" "";
BA_DEF_DEF_  "SeToolAncestorID_SIGNAL" "";
BA_DEF_DEF_  "Platform_VMCU1_Sig" "No";
BA_DEF_DEF_  "Platform_FactoryIf_Sig" "No";
BA_DEF_DEF_  "NmAsrMessage" "No";
BA_DEF_DEF_  "NeedsUpdateBit" "No";
BA_DEF_DEF_  "MmAnSignal" "No";
BA_DEF_DEF_  "GenSigMaxLatency" 0;
BA_DEF_DEF_  "GenSigILSupport" "Yes";
BA_DEF_DEF_  "GenMsgILSupport" "Yes";
BA_DEF_DEF_  "DiagUUDTResponse" "No";
BA_DEF_DEF_  "DiagState" "No";
BA_DEF_DEF_  "DiagResponse" "No";
BA_DEF_DEF_  "DiagRequest" "No";
BA_DEF_DEF_  "DiagConnection" 0;
BA_DEF_DEF_  "CanTpSTmin" 0;
BA_DEF_DEF_  "CanTpFcFrameId" 2147483647;
BA_DEF_DEF_  "CanTpBs" 255;
BA_DEF_DEF_REL_ "GenSigTimeoutTime" 0;
BA_DEF_DEF_REL_ "GenSigFirstTimeoutTime" 0;
BA_DEF_DEF_  "SystemSignalLongSymbol" "";
BA_ "CanTpFcFrameId" BO_ 1414 1415;
BA_ "VFrameFormat" BO_ 1414 0;
BA_ "GenMsgSendType" BO_ 1414 8;
BA_ "GenMsgDelayTime" BO_ 1414 50;
BA_ "GenMsgStartDelayTime" BO_ 1414 5;
BA_ "GenMsgILSupport" BO_ 1382 0;
BA_ "VFrameFormat" BO_ 1382 0;
BA_ "GenMsgSendType" BO_ 1382 8;
BA_ "CanTpFcFrameId" BO_ 1381 1382;
BA_ "VFrameFormat" BO_ 1381 0;
BA_ "GenMsgSendType" BO_ 1381 8;
BA_ "GenMsgDelayTime" BO_ 1381 50;
BA_ "GenMsgStartDelayTime" BO_ 1381 5;
BA_ "GenMsgILSupport" BO_ 1387 0;
BA_ "VFrameFormat" BO_ 1387 0;
BA_ "GenMsgSendType" BO_ 1387 8;
BA_ "CanTpFcFrameId" BO_ 1386 1387;
BA_ "VFrameFormat" BO_ 1386 0;
BA_ "GenMsgSendType" BO_ 1386 8;
BA_ "GenMsgDelayTime" BO_ 1386 50;
BA_ "GenMsgStartDelayTime" BO_ 1386 5;
BA_ "GenMsgILSupport" BO_ 1385 0;
BA_ "VFrameFormat" BO_ 1385 0;
BA_ "GenMsgSendType" BO_ 1385 8;
BA_ "CanTpFcFrameId" BO_ 1384 1385;
BA_ "VFrameFormat" BO_ 1384 0;
BA_ "GenMsgSendType" BO_ 1384 8;
BA_ "GenMsgDelayTime" BO_ 1384 50;
BA_ "GenMsgStartDelayTime" BO_ 1384 5;
BA_ "VFrameFormat" BO_ 979 0;
BA_ "GenMsgCycleTime" BO_ 979 75;
BA_ "GenMsgStartDelayTime" BO_ 979 5;
BA_ "VFrameFormat" BO_ 970 0;
BA_ "GenMsgCycleTime" BO_ 970 75;
BA_ "GenMsgStartDelayTime" BO_ 970 30;
BA_ "VFrameFormat" BO_ 851 0;
BA_ "GenMsgCycleTime" BO_ 851 60;
BA_ "GenMsgStartDelayTime" BO_ 851 10;
BA_ "VFrameFormat" BO_ 1270 0;
BA_ "GenMsgCycleTime" BO_ 1270 200;
BA_ "GenMsgStartDelayTime" BO_ 1270 45;
BA_ "VFrameFormat" BO_ 739 0;
BA_ "GenMsgCycleTime" BO_ 739 35;
BA_ "GenMsgStartDelayTime" BO_ 739 20;
BA_ "VFrameFormat" BO_ 390 0;
BA_ "GenMsgCycleTime" BO_ 390 15;
BA_ "VFrameFormat" BO_ 514 0;
BA_ "GenMsgCycleTime" BO_ 514 25;
BA_ "GenMsgStartDelayTime" BO_ 514 5;
BA_ "VFrameFormat" BO_ 1288 0;
BA_ "GenMsgCycleTime" BO_ 1288 1000;
BA_ "GenMsgStartDelayTime" BO_ 1288 150;
BA_ "VFrameFormat" BO_ 1285 0;
BA_ "GenMsgCycleTime" BO_ 1285 1000;
BA_ "VFrameFormat" BO_ 1282 0;
BA_ "GenMsgCycleTime" BO_ 1282 500;
BA_ "GenMsgStartDelayTime" BO_ 1282 100;
BA_ "VFrameFormat" BO_ 1252 0;
BA_ "GenMsgCycleTime" BO_ 1252 1000;
BA_ "GenMsgStartDelayTime" BO_ 1252 75;
BA_ "GenMsgILSupport" BO_ 961 0;
BA_ "VFrameFormat" BO_ 961 0;
BA_ "GenMsgSendType" BO_ 961 8;
BA_ "CanTpFcFrameId" BO_ 958 961;
BA_ "VFrameFormat" BO_ 958 0;
BA_ "GenMsgSendType" BO_ 958 8;
BA_ "GenMsgDelayTime" BO_ 958 85;
BA_ "VFrameFormat" BO_ 1374 0;
BA_ "GenMsgCycleTime" BO_ 1374 1000;
BA_ "GenMsgStartDelayTime" BO_ 1374 40;
BA_ "GenMsgILSupport" BO_ 1342 0;
BA_ "VFrameFormat" BO_ 1342 0;
BA_ "GenMsgSendType" BO_ 1342 8;
BA_ "CanTpFcFrameId" BO_ 1341 1342;
BA_ "VFrameFormat" BO_ 1341 0;
BA_ "GenMsgSendType" BO_ 1341 8;
BA_ "GenMsgDelayTime" BO_ 1341 110;
BA_ "VFrameFormat" BO_ 1392 0;
BA_ "GenMsgCycleTime" BO_ 1392 1200;
BA_ "GenMsgStartDelayTime" BO_ 1392 60;
BA_ "VFrameFormat" BO_ 1391 0;
BA_ "GenMsgCycleTime" BO_ 1391 1500;
BA_ "GenMsgStartDelayTime" BO_ 1391 250;
BA_ "VFrameFormat" BO_ 1276 0;
BA_ "GenMsgCycleTime" BO_ 1276 250;
BA_ "GenMsgStartDelayTime" BO_ 1276 120;
BA_ "VFrameFormat" BO_ 1291 0;
BA_ "GenMsgCycleTime" BO_ 1291 250;
BA_ "GenMsgStartDelayTime" BO_ 1291 15;
BA_ "VFrameFormat" BO_ 1279 0;
BA_ "GenMsgCycleTime" BO_ 1279 250;
BA_ "GenMsgStartDelayTime" BO_ 1279 5;
BA_ "VFrameFormat" BO_ 733 0;
BA_ "GenMsgCycleTime" BO_ 733 45;
BA_ "VFrameFormat" BO_ 719 0;
BA_ "GenMsgCycleTime" BO_ 719 45;
BA_ "GenMsgStartDelayTime" BO_ 719 20;
BA_ "DiagConnection" BO_ 2671964911 62191;
BA_ "DiagUUDTResponse" BO_ 2671964911 1;
BA_ "GenMsgILSupport" BO_ 2671964911 0;
BA_ "GenMsgSendType" BO_ 2671964911 8;
BA_ "DiagConnection" BO_ 2671964902 62182;
BA_ "DiagUUDTResponse" BO_ 2671964902 1;
BA_ "GenMsgILSupport" BO_ 2671964902 0;
BA_ "GenMsgSendType" BO_ 2671964902 8;
BA_ "DiagConnection" BO_ 2671964901 62181;
BA_ "DiagUUDTResponse" BO_ 2671964901 1;
BA_ "GenMsgILSupport" BO_ 2671964901 0;
BA_ "GenMsgSendType" BO_ 2671964901 8;
BA_ "DiagConnection" BO_ 2671964866 62146;
BA_ "DiagUUDTResponse" BO_ 2671964866 1;
BA_ "GenMsgILSupport" BO_ 2671964866 0;
BA_ "GenMsgSendType" BO_ 2671964866 8;
BA_ "DiagConnection" BO_ 2671964864 62144;
BA_ "DiagUUDTResponse" BO_ 2671964864 1;
BA_ "GenMsgILSupport" BO_ 2671964864 0;
BA_ "GenMsgSendType" BO_ 2671964864 8;
BA_ "DiagConnection" BO_ 2671964834 62114;
BA_ "DiagUUDTResponse" BO_ 2671964834 1;
BA_ "GenMsgILSupport" BO_ 2671964834 0;
BA_ "GenMsgSendType" BO_ 2671964834 8;
BA_ "DiagConnection" BO_ 2671964833 62113;
BA_ "DiagUUDTResponse" BO_ 2671964833 1;
BA_ "GenMsgILSupport" BO_ 2671964833 0;
BA_ "GenMsgSendType" BO_ 2671964833 8;
BA_ "DiagConnection" BO_ 2671964832 62112;
BA_ "DiagUUDTResponse" BO_ 2671964832 1;
BA_ "GenMsgILSupport" BO_ 2671964832 0;
BA_ "GenMsgSendType" BO_ 2671964832 8;
BA_ "DiagConnection" BO_ 2671964824 62104;
BA_ "DiagUUDTResponse" BO_ 2671964824 1;
BA_ "GenMsgILSupport" BO_ 2671964824 0;
BA_ "GenMsgSendType" BO_ 2671964824 8;
BA_ "DiagConnection" BO_ 2671964812 62092;
BA_ "DiagUUDTResponse" BO_ 2671964812 1;
BA_ "GenMsgILSupport" BO_ 2671964812 0;
BA_ "GenMsgSendType" BO_ 2671964812 8;
BA_ "DiagConnection" BO_ 2671964803 62083;
BA_ "DiagUUDTResponse" BO_ 2671964803 1;
BA_ "GenMsgILSupport" BO_ 2671964803 0;
BA_ "GenMsgSendType" BO_ 2671964803 8;
BA_ "DiagConnection" BO_ 2671964802 62082;
BA_ "DiagUUDTResponse" BO_ 2671964802 1;
BA_ "GenMsgILSupport" BO_ 2671964802 0;
BA_ "GenMsgSendType" BO_ 2671964802 8;
BA_ "DiagConnection" BO_ 2671964772 62052;
BA_ "DiagUUDTResponse" BO_ 2671964772 1;
BA_ "GenMsgILSupport" BO_ 2671964772 0;
BA_ "GenMsgSendType" BO_ 2671964772 8;
BA_ "DiagConnection" BO_ 2671964769 62049;
BA_ "DiagUUDTResponse" BO_ 2671964769 1;
BA_ "GenMsgILSupport" BO_ 2671964769 0;
BA_ "GenMsgSendType" BO_ 2671964769 8;
BA_ "DiagConnection" BO_ 2671964768 62048;
BA_ "DiagUUDTResponse" BO_ 2671964768 1;
BA_ "GenMsgILSupport" BO_ 2671964768 0;
BA_ "GenMsgSendType" BO_ 2671964768 8;
BA_ "DiagConnection" BO_ 2671964755 62035;
BA_ "DiagUUDTResponse" BO_ 2671964755 1;
BA_ "GenMsgILSupport" BO_ 2671964755 0;
BA_ "GenMsgSendType" BO_ 2671964755 8;
BA_ "DiagConnection" BO_ 2671964754 62034;
BA_ "DiagUUDTResponse" BO_ 2671964754 1;
BA_ "GenMsgILSupport" BO_ 2671964754 0;
BA_ "GenMsgSendType" BO_ 2671964754 8;
BA_ "DiagConnection" BO_ 2671964753 62033;
BA_ "DiagUUDTResponse" BO_ 2671964753 1;
BA_ "GenMsgILSupport" BO_ 2671964753 0;
BA_ "GenMsgSendType" BO_ 2671964753 8;
BA_ "DiagConnection" BO_ 2671964752 62032;
BA_ "DiagUUDTResponse" BO_ 2671964752 1;
BA_ "GenMsgILSupport" BO_ 2671964752 0;
BA_ "GenMsgSendType" BO_ 2671964752 8;
BA_ "DiagConnection" BO_ 2671964737 62017;
BA_ "DiagUUDTResponse" BO_ 2671964737 1;
BA_ "GenMsgILSupport" BO_ 2671964737 0;
BA_ "GenMsgSendType" BO_ 2671964737 8;
BA_ "DiagConnection" BO_ 2671964736 62016;
BA_ "DiagUUDTResponse" BO_ 2671964736 1;
BA_ "GenMsgILSupport" BO_ 2671964736 0;
BA_ "GenMsgSendType" BO_ 2671964736 8;
BA_ "DiagConnection" BO_ 2671964710 61990;
BA_ "DiagUUDTResponse" BO_ 2671964710 1;
BA_ "GenMsgILSupport" BO_ 2671964710 0;
BA_ "GenMsgSendType" BO_ 2671964710 8;
BA_ "DiagConnection" BO_ 2671964696 61976;
BA_ "DiagUUDTResponse" BO_ 2671964696 1;
BA_ "GenMsgILSupport" BO_ 2671964696 0;
BA_ "GenMsgSendType" BO_ 2671964696 8;
BA_ "DiagConnection" BO_ 2671964688 61968;
BA_ "DiagUUDTResponse" BO_ 2671964688 1;
BA_ "GenMsgILSupport" BO_ 2671964688 0;
BA_ "GenMsgSendType" BO_ 2671964688 8;
BA_ "DiagConnection" BO_ 2671834277 62629;
BA_ "DiagResponse" BO_ 2671834277 1;
BA_ "GenMsgILSupport" BO_ 2671834277 0;
BA_ "GenMsgSendType" BO_ 2671834277 8;
BA_ "DiagConnection" BO_ 2671834227 62579;
BA_ "DiagResponse" BO_ 2671834227 1;
BA_ "GenMsgILSupport" BO_ 2671834227 0;
BA_ "GenMsgSendType" BO_ 2671834227 8;
BA_ "DiagConnection" BO_ 2671834213 62565;
BA_ "DiagResponse" BO_ 2671834213 1;
BA_ "GenMsgILSupport" BO_ 2671834213 0;
BA_ "GenMsgSendType" BO_ 2671834213 8;
BA_ "DiagConnection" BO_ 2671834168 62520;
BA_ "DiagResponse" BO_ 2671834168 1;
BA_ "GenMsgILSupport" BO_ 2671834168 0;
BA_ "GenMsgSendType" BO_ 2671834168 8;
BA_ "DiagConnection" BO_ 2671834351 62703;
BA_ "DiagResponse" BO_ 2671834351 1;
BA_ "GenMsgILSupport" BO_ 2671834351 0;
BA_ "GenMsgSendType" BO_ 2671834351 8;
BA_ "DiagConnection" BO_ 2671834342 62694;
BA_ "DiagResponse" BO_ 2671834342 1;
BA_ "GenMsgILSupport" BO_ 2671834342 0;
BA_ "GenMsgSendType" BO_ 2671834342 8;
BA_ "DiagConnection" BO_ 2671834341 62693;
BA_ "DiagResponse" BO_ 2671834341 1;
BA_ "GenMsgILSupport" BO_ 2671834341 0;
BA_ "GenMsgSendType" BO_ 2671834341 8;
BA_ "DiagConnection" BO_ 2671834306 62658;
BA_ "DiagResponse" BO_ 2671834306 1;
BA_ "GenMsgILSupport" BO_ 2671834306 0;
BA_ "GenMsgSendType" BO_ 2671834306 8;
BA_ "DiagConnection" BO_ 2671834304 62656;
BA_ "DiagResponse" BO_ 2671834304 1;
BA_ "GenMsgILSupport" BO_ 2671834304 0;
BA_ "GenMsgSendType" BO_ 2671834304 8;
BA_ "DiagConnection" BO_ 2671834274 62626;
BA_ "DiagResponse" BO_ 2671834274 1;
BA_ "GenMsgILSupport" BO_ 2671834274 0;
BA_ "GenMsgSendType" BO_ 2671834274 8;
BA_ "DiagConnection" BO_ 2671834273 62625;
BA_ "DiagResponse" BO_ 2671834273 1;
BA_ "GenMsgILSupport" BO_ 2671834273 0;
BA_ "GenMsgSendType" BO_ 2671834273 8;
BA_ "DiagConnection" BO_ 2671834272 62624;
BA_ "DiagResponse" BO_ 2671834272 1;
BA_ "GenMsgILSupport" BO_ 2671834272 0;
BA_ "GenMsgSendType" BO_ 2671834272 8;
BA_ "DiagConnection" BO_ 2671834264 62616;
BA_ "DiagResponse" BO_ 2671834264 1;
BA_ "GenMsgILSupport" BO_ 2671834264 0;
BA_ "GenMsgSendType" BO_ 2671834264 8;
BA_ "DiagConnection" BO_ 2671834252 62604;
BA_ "DiagResponse" BO_ 2671834252 1;
BA_ "GenMsgILSupport" BO_ 2671834252 0;
BA_ "GenMsgSendType" BO_ 2671834252 8;
BA_ "DiagConnection" BO_ 2671834226 62578;
BA_ "DiagResponse" BO_ 2671834226 1;
BA_ "GenMsgILSupport" BO_ 2671834226 0;
BA_ "GenMsgSendType" BO_ 2671834226 8;
BA_ "DiagConnection" BO_ 2671834225 62577;
BA_ "DiagResponse" BO_ 2671834225 1;
BA_ "GenMsgILSupport" BO_ 2671834225 0;
BA_ "GenMsgSendType" BO_ 2671834225 8;
BA_ "DiagConnection" BO_ 2671834195 62547;
BA_ "DiagResponse" BO_ 2671834195 1;
BA_ "GenMsgILSupport" BO_ 2671834195 0;
BA_ "GenMsgSendType" BO_ 2671834195 8;
BA_ "DiagConnection" BO_ 2671834194 62546;
BA_ "DiagResponse" BO_ 2671834194 1;
BA_ "GenMsgILSupport" BO_ 2671834194 0;
BA_ "GenMsgSendType" BO_ 2671834194 8;
BA_ "DiagConnection" BO_ 2671834193 62545;
BA_ "DiagResponse" BO_ 2671834193 1;
BA_ "GenMsgILSupport" BO_ 2671834193 0;
BA_ "GenMsgSendType" BO_ 2671834193 8;
BA_ "DiagConnection" BO_ 2671834192 62544;
BA_ "DiagResponse" BO_ 2671834192 1;
BA_ "GenMsgILSupport" BO_ 2671834192 0;
BA_ "GenMsgSendType" BO_ 2671834192 8;
BA_ "DiagConnection" BO_ 2671834176 62528;
BA_ "DiagResponse" BO_ 2671834176 1;
BA_ "GenMsgILSupport" BO_ 2671834176 0;
BA_ "GenMsgSendType" BO_ 2671834176 8;
BA_ "DiagConnection" BO_ 2671834161 62513;
BA_ "DiagResponse" BO_ 2671834161 1;
BA_ "GenMsgILSupport" BO_ 2671834161 0;
BA_ "GenMsgSendType" BO_ 2671834161 8;
BA_ "DiagConnection" BO_ 2671834160 62512;
BA_ "DiagResponse" BO_ 2671834160 1;
BA_ "GenMsgILSupport" BO_ 2671834160 0;
BA_ "GenMsgSendType" BO_ 2671834160 8;
BA_ "DiagConnection" BO_ 2671834150 62502;
BA_ "DiagResponse" BO_ 2671834150 1;
BA_ "GenMsgILSupport" BO_ 2671834150 0;
BA_ "GenMsgSendType" BO_ 2671834150 8;
BA_ "DiagConnection" BO_ 2671834149 62501;
BA_ "DiagResponse" BO_ 2671834149 1;
BA_ "GenMsgILSupport" BO_ 2671834149 0;
BA_ "GenMsgSendType" BO_ 2671834149 8;
BA_ "DiagConnection" BO_ 2671834148 62500;
BA_ "DiagResponse" BO_ 2671834148 1;
BA_ "GenMsgILSupport" BO_ 2671834148 0;
BA_ "GenMsgSendType" BO_ 2671834148 8;
BA_ "DiagConnection" BO_ 2671834147 62499;
BA_ "DiagResponse" BO_ 2671834147 1;
BA_ "GenMsgILSupport" BO_ 2671834147 0;
BA_ "GenMsgSendType" BO_ 2671834147 8;
BA_ "DiagConnection" BO_ 2671834146 62498;
BA_ "DiagResponse" BO_ 2671834146 1;
BA_ "GenMsgILSupport" BO_ 2671834146 0;
BA_ "GenMsgSendType" BO_ 2671834146 8;
BA_ "DiagConnection" BO_ 2671834145 62497;
BA_ "DiagResponse" BO_ 2671834145 1;
BA_ "GenMsgILSupport" BO_ 2671834145 0;
BA_ "GenMsgSendType" BO_ 2671834145 8;
BA_ "DiagConnection" BO_ 2671834144 62496;
BA_ "DiagResponse" BO_ 2671834144 1;
BA_ "GenMsgILSupport" BO_ 2671834144 0;
BA_ "GenMsgSendType" BO_ 2671834144 8;
BA_ "DiagConnection" BO_ 2671834138 62490;
BA_ "DiagResponse" BO_ 2671834138 1;
BA_ "GenMsgILSupport" BO_ 2671834138 0;
BA_ "GenMsgSendType" BO_ 2671834138 8;
BA_ "DiagConnection" BO_ 2671834136 62488;
BA_ "DiagResponse" BO_ 2671834136 1;
BA_ "GenMsgILSupport" BO_ 2671834136 0;
BA_ "GenMsgSendType" BO_ 2671834136 8;
BA_ "DiagConnection" BO_ 2671834128 62480;
BA_ "DiagResponse" BO_ 2671834128 1;
BA_ "GenMsgILSupport" BO_ 2671834128 0;
BA_ "GenMsgSendType" BO_ 2671834128 8;
BA_ "DiagConnection" BO_ 2671834095 62447;
BA_ "DiagResponse" BO_ 2671834095 1;
BA_ "GenMsgILSupport" BO_ 2671834095 0;
BA_ "GenMsgSendType" BO_ 2671834095 8;
BA_ "DiagConnection" BO_ 2671834050 62402;
BA_ "DiagResponse" BO_ 2671834050 1;
BA_ "GenMsgILSupport" BO_ 2671834050 0;
BA_ "GenMsgSendType" BO_ 2671834050 8;
BA_ "DiagConnection" BO_ 2671834021 62373;
BA_ "DiagResponse" BO_ 2671834021 1;
BA_ "GenMsgILSupport" BO_ 2671834021 0;
BA_ "GenMsgSendType" BO_ 2671834021 8;
BA_ "DiagConnection" BO_ 2671833971 62323;
BA_ "DiagResponse" BO_ 2671833971 1;
BA_ "GenMsgILSupport" BO_ 2671833971 0;
BA_ "GenMsgSendType" BO_ 2671833971 8;
BA_ "DiagConnection" BO_ 2671833957 62309;
BA_ "DiagResponse" BO_ 2671833957 1;
BA_ "GenMsgILSupport" BO_ 2671833957 0;
BA_ "GenMsgSendType" BO_ 2671833957 8;
BA_ "DiagConnection" BO_ 2671833912 62264;
BA_ "DiagResponse" BO_ 2671833912 1;
BA_ "GenMsgILSupport" BO_ 2671833912 0;
BA_ "GenMsgSendType" BO_ 2671833912 8;
BA_ "DiagConnection" BO_ 2671834086 62438;
BA_ "DiagResponse" BO_ 2671834086 1;
BA_ "GenMsgILSupport" BO_ 2671834086 0;
BA_ "GenMsgSendType" BO_ 2671834086 8;
BA_ "DiagConnection" BO_ 2671834085 62437;
BA_ "DiagResponse" BO_ 2671834085 1;
BA_ "GenMsgILSupport" BO_ 2671834085 0;
BA_ "GenMsgSendType" BO_ 2671834085 8;
BA_ "DiagConnection" BO_ 2671834048 62400;
BA_ "DiagResponse" BO_ 2671834048 1;
BA_ "GenMsgILSupport" BO_ 2671834048 0;
BA_ "GenMsgSendType" BO_ 2671834048 8;
BA_ "DiagConnection" BO_ 2671834018 62370;
BA_ "DiagResponse" BO_ 2671834018 1;
BA_ "GenMsgILSupport" BO_ 2671834018 0;
BA_ "GenMsgSendType" BO_ 2671834018 8;
BA_ "DiagConnection" BO_ 2671834017 62369;
BA_ "DiagResponse" BO_ 2671834017 1;
BA_ "GenMsgILSupport" BO_ 2671834017 0;
BA_ "GenMsgSendType" BO_ 2671834017 8;
BA_ "DiagConnection" BO_ 2671834016 62368;
BA_ "DiagResponse" BO_ 2671834016 1;
BA_ "GenMsgILSupport" BO_ 2671834016 0;
BA_ "GenMsgSendType" BO_ 2671834016 8;
BA_ "DiagConnection" BO_ 2671834008 62360;
BA_ "DiagResponse" BO_ 2671834008 1;
BA_ "GenMsgILSupport" BO_ 2671834008 0;
BA_ "GenMsgSendType" BO_ 2671834008 8;
BA_ "DiagConnection" BO_ 2671833996 62348;
BA_ "DiagResponse" BO_ 2671833996 1;
BA_ "GenMsgILSupport" BO_ 2671833996 0;
BA_ "GenMsgSendType" BO_ 2671833996 8;
BA_ "DiagConnection" BO_ 2671833970 62322;
BA_ "DiagResponse" BO_ 2671833970 1;
BA_ "GenMsgILSupport" BO_ 2671833970 0;
BA_ "GenMsgSendType" BO_ 2671833970 8;
BA_ "DiagConnection" BO_ 2671833969 62321;
BA_ "DiagResponse" BO_ 2671833969 1;
BA_ "GenMsgILSupport" BO_ 2671833969 0;
BA_ "GenMsgSendType" BO_ 2671833969 8;
BA_ "DiagConnection" BO_ 2671833939 62291;
BA_ "DiagResponse" BO_ 2671833939 1;
BA_ "GenMsgILSupport" BO_ 2671833939 0;
BA_ "GenMsgSendType" BO_ 2671833939 8;
BA_ "DiagConnection" BO_ 2671833938 62290;
BA_ "DiagResponse" BO_ 2671833938 1;
BA_ "GenMsgILSupport" BO_ 2671833938 0;
BA_ "GenMsgSendType" BO_ 2671833938 8;
BA_ "DiagConnection" BO_ 2671833937 62289;
BA_ "DiagResponse" BO_ 2671833937 1;
BA_ "GenMsgILSupport" BO_ 2671833937 0;
BA_ "GenMsgSendType" BO_ 2671833937 8;
BA_ "DiagConnection" BO_ 2671833936 62288;
BA_ "DiagResponse" BO_ 2671833936 1;
BA_ "GenMsgILSupport" BO_ 2671833936 0;
BA_ "GenMsgSendType" BO_ 2671833936 8;
BA_ "DiagConnection" BO_ 2671833920 62272;
BA_ "DiagResponse" BO_ 2671833920 1;
BA_ "GenMsgILSupport" BO_ 2671833920 0;
BA_ "GenMsgSendType" BO_ 2671833920 8;
BA_ "DiagConnection" BO_ 2671833905 62257;
BA_ "DiagResponse" BO_ 2671833905 1;
BA_ "GenMsgILSupport" BO_ 2671833905 0;
BA_ "GenMsgSendType" BO_ 2671833905 8;
BA_ "DiagConnection" BO_ 2671833904 62256;
BA_ "DiagResponse" BO_ 2671833904 1;
BA_ "GenMsgILSupport" BO_ 2671833904 0;
BA_ "GenMsgSendType" BO_ 2671833904 8;
BA_ "DiagConnection" BO_ 2671833894 62246;
BA_ "DiagResponse" BO_ 2671833894 1;
BA_ "GenMsgILSupport" BO_ 2671833894 0;
BA_ "GenMsgSendType" BO_ 2671833894 8;
BA_ "DiagConnection" BO_ 2671833893 62245;
BA_ "DiagResponse" BO_ 2671833893 1;
BA_ "GenMsgILSupport" BO_ 2671833893 0;
BA_ "GenMsgSendType" BO_ 2671833893 8;
BA_ "DiagConnection" BO_ 2671833892 62244;
BA_ "DiagResponse" BO_ 2671833892 1;
BA_ "GenMsgILSupport" BO_ 2671833892 0;
BA_ "GenMsgSendType" BO_ 2671833892 8;
BA_ "DiagConnection" BO_ 2671833891 62243;
BA_ "DiagResponse" BO_ 2671833891 1;
BA_ "GenMsgILSupport" BO_ 2671833891 0;
BA_ "GenMsgSendType" BO_ 2671833891 8;
BA_ "DiagConnection" BO_ 2671833890 62242;
BA_ "DiagResponse" BO_ 2671833890 1;
BA_ "GenMsgILSupport" BO_ 2671833890 0;
BA_ "GenMsgSendType" BO_ 2671833890 8;
BA_ "DiagConnection" BO_ 2671833889 62241;
BA_ "DiagResponse" BO_ 2671833889 1;
BA_ "GenMsgILSupport" BO_ 2671833889 0;
BA_ "GenMsgSendType" BO_ 2671833889 8;
BA_ "DiagConnection" BO_ 2671833888 62240;
BA_ "DiagResponse" BO_ 2671833888 1;
BA_ "GenMsgILSupport" BO_ 2671833888 0;
BA_ "GenMsgSendType" BO_ 2671833888 8;
BA_ "DiagConnection" BO_ 2671833882 62234;
BA_ "DiagResponse" BO_ 2671833882 1;
BA_ "GenMsgILSupport" BO_ 2671833882 0;
BA_ "GenMsgSendType" BO_ 2671833882 8;
BA_ "DiagConnection" BO_ 2671833880 62232;
BA_ "DiagResponse" BO_ 2671833880 1;
BA_ "GenMsgILSupport" BO_ 2671833880 0;
BA_ "GenMsgSendType" BO_ 2671833880 8;
BA_ "DiagConnection" BO_ 2671833872 62224;
BA_ "DiagResponse" BO_ 2671833872 1;
BA_ "GenMsgILSupport" BO_ 2671833872 0;
BA_ "GenMsgSendType" BO_ 2671833872 8;
BA_ "DiagConnection" BO_ 2671833076 62703;
BA_ "DiagRequest" BO_ 2671833076 1;
BA_ "GenMsgILSupport" BO_ 2671833076 0;
BA_ "GenMsgSendType" BO_ 2671833076 8;
BA_ "DiagConnection" BO_ 2671821556 62658;
BA_ "DiagRequest" BO_ 2671821556 1;
BA_ "GenMsgILSupport" BO_ 2671821556 0;
BA_ "GenMsgSendType" BO_ 2671821556 8;
BA_ "DiagConnection" BO_ 2671814132 62629;
BA_ "DiagRequest" BO_ 2671814132 1;
BA_ "GenMsgILSupport" BO_ 2671814132 0;
BA_ "GenMsgSendType" BO_ 2671814132 8;
BA_ "DiagConnection" BO_ 2671801332 62579;
BA_ "DiagRequest" BO_ 2671801332 1;
BA_ "GenMsgILSupport" BO_ 2671801332 0;
BA_ "GenMsgSendType" BO_ 2671801332 8;
BA_ "DiagConnection" BO_ 2671797748 62565;
BA_ "DiagRequest" BO_ 2671797748 1;
BA_ "GenMsgILSupport" BO_ 2671797748 0;
BA_ "GenMsgSendType" BO_ 2671797748 8;
BA_ "DiagConnection" BO_ 2671786228 62520;
BA_ "DiagRequest" BO_ 2671786228 1;
BA_ "GenMsgILSupport" BO_ 2671786228 0;
BA_ "GenMsgSendType" BO_ 2671786228 8;
BA_ "DiagConnection" BO_ 2671830772 62694;
BA_ "DiagRequest" BO_ 2671830772 1;
BA_ "GenMsgILSupport" BO_ 2671830772 0;
BA_ "GenMsgSendType" BO_ 2671830772 8;
BA_ "DiagConnection" BO_ 2671830516 62693;
BA_ "DiagRequest" BO_ 2671830516 1;
BA_ "GenMsgILSupport" BO_ 2671830516 0;
BA_ "GenMsgSendType" BO_ 2671830516 8;
BA_ "DiagConnection" BO_ 2671821044 62656;
BA_ "DiagRequest" BO_ 2671821044 1;
BA_ "GenMsgILSupport" BO_ 2671821044 0;
BA_ "GenMsgSendType" BO_ 2671821044 8;
BA_ "GenSigSendType" SG_ 1414 GPSData_Altitude_ISig_4_586 1;
BA_ "GenSigStartValue" SG_ 1414 GPSData_Altitude_ISig_4_586 65535;
BA_ "GenSigMaxLatency" SG_ 1414 GPSData_Altitude_ISig_4_586 523;
BA_ "NeedsUpdateBit" SG_ 1414 GPSData_Altitude_ISig_4_586 1;
BA_ "Platform_VMCU1_Sig" SG_ 1414 GPSData_Altitude_ISig_4_586 1;
BA_ "GenSigSendType" SG_ 1414 GPSData_Longitude_ISig_4_586 1;
BA_ "GenSigStartValue" SG_ 1414 GPSData_Longitude_ISig_4_586 4294967295;
BA_ "GenSigMaxLatency" SG_ 1414 GPSData_Longitude_ISig_4_586 523;
BA_ "NeedsUpdateBit" SG_ 1414 GPSData_Longitude_ISig_4_586 1;
BA_ "Platform_VMCU1_Sig" SG_ 1414 GPSData_Longitude_ISig_4_586 1;
BA_ "GenSigSendType" SG_ 1414 GPSData_HDOP_ISig_4_586 1;
BA_ "GenSigMaxLatency" SG_ 1414 GPSData_HDOP_ISig_4_586 523;
BA_ "NeedsUpdateBit" SG_ 1414 GPSData_HDOP_ISig_4_586 1;
BA_ "Platform_VMCU1_Sig" SG_ 1414 GPSData_HDOP_ISig_4_586 1;
BA_ "GenSigSendType" SG_ 1414 GPSData_sg_UB_ISig_4_586 7;
BA_ "Platform_VMCU1_Sig" SG_ 1414 GPSData_sg_UB_ISig_4_586 1;
BA_ "GenSigSendType" SG_ 1414 GPSData_Direction_ISig_4_586 1;
BA_ "GenSigMaxLatency" SG_ 1414 GPSData_Direction_ISig_4_586 523;
BA_ "NeedsUpdateBit" SG_ 1414 GPSData_Direction_ISig_4_586 1;
BA_ "Platform_VMCU1_Sig" SG_ 1414 GPSData_Direction_ISig_4_586 1;
BA_ "GenSigSendType" SG_ 1414 GPSData_Time_ISig_4_586 1;
BA_ "GenSigStartValue" SG_ 1414 GPSData_Time_ISig_4_586 4294967295;
BA_ "GenSigMaxLatency" SG_ 1414 GPSData_Time_ISig_4_586 523;
BA_ "NeedsUpdateBit" SG_ 1414 GPSData_Time_ISig_4_586 1;
BA_ "Platform_VMCU1_Sig" SG_ 1414 GPSData_Time_ISig_4_586 1;
BA_ "GenSigSendType" SG_ 1414 GPSData_VehSpeed_ISig_4_586 1;
BA_ "GenSigStartValue" SG_ 1414 GPSData_VehSpeed_ISig_4_586 65535;
BA_ "GenSigMaxLatency" SG_ 1414 GPSData_VehSpeed_ISig_4_586 523;
BA_ "NeedsUpdateBit" SG_ 1414 GPSData_VehSpeed_ISig_4_586 1;
BA_ "Platform_VMCU1_Sig" SG_ 1414 GPSData_VehSpeed_ISig_4_586 1;
BA_ "GenSigSendType" SG_ 1414 GPSData_AntennaStat_ISig_4_586 1;
BA_ "GenSigStartValue" SG_ 1414 GPSData_AntennaStat_ISig_4_586 7;
BA_ "GenSigMaxLatency" SG_ 1414 GPSData_AntennaStat_ISig_4_586 523;
BA_ "NeedsUpdateBit" SG_ 1414 GPSData_AntennaStat_ISig_4_586 1;
BA_ "Platform_VMCU1_Sig" SG_ 1414 GPSData_AntennaStat_ISig_4_586 1;
BA_ "GenSigSendType" SG_ 1414 GPSData_Latitude_ISig_4_586 1;
BA_ "GenSigStartValue" SG_ 1414 GPSData_Latitude_ISig_4_586 4294967295;
BA_ "GenSigMaxLatency" SG_ 1414 GPSData_Latitude_ISig_4_586 523;
BA_ "NeedsUpdateBit" SG_ 1414 GPSData_Latitude_ISig_4_586 1;
BA_ "Platform_VMCU1_Sig" SG_ 1414 GPSData_Latitude_ISig_4_586 1;
BA_ "GenSigSendType" SG_ 1382 HMIIOM_BB2_19P_FCS_566 7;
BA_ "Platform_VMCU1_Sig" SG_ 1382 HMIIOM_BB2_19P_FCS_566 1;
BA_ "GenSigSendType" SG_ 1381 GPSData_HDOP_ISig_4_565 1;
BA_ "GenSigMaxLatency" SG_ 1381 GPSData_HDOP_ISig_4_565 523;
BA_ "NeedsUpdateBit" SG_ 1381 GPSData_HDOP_ISig_4_565 1;
BA_ "Platform_VMCU1_Sig" SG_ 1381 GPSData_HDOP_ISig_4_565 1;
BA_ "GenSigSendType" SG_ 1381 GPSData_VehSpeed_ISig_4_565 1;
BA_ "GenSigStartValue" SG_ 1381 GPSData_VehSpeed_ISig_4_565 65535;
BA_ "GenSigMaxLatency" SG_ 1381 GPSData_VehSpeed_ISig_4_565 523;
BA_ "NeedsUpdateBit" SG_ 1381 GPSData_VehSpeed_ISig_4_565 1;
BA_ "Platform_VMCU1_Sig" SG_ 1381 GPSData_VehSpeed_ISig_4_565 1;
BA_ "GenSigSendType" SG_ 1381 GPSData_sg_UB_ISig_4_565 7;
BA_ "Platform_VMCU1_Sig" SG_ 1381 GPSData_sg_UB_ISig_4_565 1;
BA_ "GenSigSendType" SG_ 1381 GPSData_AntennaStat_ISig_4_565 1;
BA_ "GenSigStartValue" SG_ 1381 GPSData_AntennaStat_ISig_4_565 7;
BA_ "GenSigMaxLatency" SG_ 1381 GPSData_AntennaStat_ISig_4_565 523;
BA_ "NeedsUpdateBit" SG_ 1381 GPSData_AntennaStat_ISig_4_565 1;
BA_ "Platform_VMCU1_Sig" SG_ 1381 GPSData_AntennaStat_ISig_4_565 1;
BA_ "GenSigSendType" SG_ 1381 GPSData_Latitude_ISig_4_565 1;
BA_ "GenSigStartValue" SG_ 1381 GPSData_Latitude_ISig_4_565 4294967295;
BA_ "GenSigMaxLatency" SG_ 1381 GPSData_Latitude_ISig_4_565 523;
BA_ "NeedsUpdateBit" SG_ 1381 GPSData_Latitude_ISig_4_565 1;
BA_ "Platform_VMCU1_Sig" SG_ 1381 GPSData_Latitude_ISig_4_565 1;
BA_ "GenSigSendType" SG_ 1381 GPSData_Time_ISig_4_565 1;
BA_ "GenSigStartValue" SG_ 1381 GPSData_Time_ISig_4_565 4294967295;
BA_ "GenSigMaxLatency" SG_ 1381 GPSData_Time_ISig_4_565 523;
BA_ "NeedsUpdateBit" SG_ 1381 GPSData_Time_ISig_4_565 1;
BA_ "Platform_VMCU1_Sig" SG_ 1381 GPSData_Time_ISig_4_565 1;
BA_ "GenSigSendType" SG_ 1381 GPSData_Direction_ISig_4_565 1;
BA_ "GenSigMaxLatency" SG_ 1381 GPSData_Direction_ISig_4_565 523;
BA_ "NeedsUpdateBit" SG_ 1381 GPSData_Direction_ISig_4_565 1;
BA_ "Platform_VMCU1_Sig" SG_ 1381 GPSData_Direction_ISig_4_565 1;
BA_ "GenSigSendType" SG_ 1381 GPSData_Longitude_ISig_4_565 1;
BA_ "GenSigStartValue" SG_ 1381 GPSData_Longitude_ISig_4_565 4294967295;
BA_ "GenSigMaxLatency" SG_ 1381 GPSData_Longitude_ISig_4_565 523;
BA_ "NeedsUpdateBit" SG_ 1381 GPSData_Longitude_ISig_4_565 1;
BA_ "Platform_VMCU1_Sig" SG_ 1381 GPSData_Longitude_ISig_4_565 1;
BA_ "GenSigSendType" SG_ 1381 GPSData_Altitude_ISig_4_565 1;
BA_ "GenSigStartValue" SG_ 1381 GPSData_Altitude_ISig_4_565 65535;
BA_ "GenSigMaxLatency" SG_ 1381 GPSData_Altitude_ISig_4_565 523;
BA_ "NeedsUpdateBit" SG_ 1381 GPSData_Altitude_ISig_4_565 1;
BA_ "Platform_VMCU1_Sig" SG_ 1381 GPSData_Altitude_ISig_4_565 1;
BA_ "GenSigSendType" SG_ 1387 HMIIOM_BB2_19P_FCS_56b 7;
BA_ "Platform_VMCU1_Sig" SG_ 1387 HMIIOM_BB2_19P_FCS_56b 1;
BA_ "GenSigSendType" SG_ 1386 GPSData_HDOP_ISig_4_56a 1;
BA_ "GenSigMaxLatency" SG_ 1386 GPSData_HDOP_ISig_4_56a 523;
BA_ "NeedsUpdateBit" SG_ 1386 GPSData_HDOP_ISig_4_56a 1;
BA_ "Platform_VMCU1_Sig" SG_ 1386 GPSData_HDOP_ISig_4_56a 1;
BA_ "GenSigSendType" SG_ 1386 GPSData_Latitude_ISig_4_56a 1;
BA_ "GenSigStartValue" SG_ 1386 GPSData_Latitude_ISig_4_56a 4294967295;
BA_ "GenSigMaxLatency" SG_ 1386 GPSData_Latitude_ISig_4_56a 523;
BA_ "NeedsUpdateBit" SG_ 1386 GPSData_Latitude_ISig_4_56a 1;
BA_ "Platform_VMCU1_Sig" SG_ 1386 GPSData_Latitude_ISig_4_56a 1;
BA_ "GenSigSendType" SG_ 1386 GPSData_Time_ISig_4_56a 1;
BA_ "GenSigStartValue" SG_ 1386 GPSData_Time_ISig_4_56a 4294967295;
BA_ "GenSigMaxLatency" SG_ 1386 GPSData_Time_ISig_4_56a 523;
BA_ "NeedsUpdateBit" SG_ 1386 GPSData_Time_ISig_4_56a 1;
BA_ "Platform_VMCU1_Sig" SG_ 1386 GPSData_Time_ISig_4_56a 1;
BA_ "GenSigSendType" SG_ 1386 GPSData_Direction_ISig_4_56a 1;
BA_ "GenSigMaxLatency" SG_ 1386 GPSData_Direction_ISig_4_56a 523;
BA_ "NeedsUpdateBit" SG_ 1386 GPSData_Direction_ISig_4_56a 1;
BA_ "Platform_VMCU1_Sig" SG_ 1386 GPSData_Direction_ISig_4_56a 1;
BA_ "GenSigSendType" SG_ 1386 GPSData_sg_UB_ISig_4_56a 7;
BA_ "Platform_VMCU1_Sig" SG_ 1386 GPSData_sg_UB_ISig_4_56a 1;
BA_ "GenSigSendType" SG_ 1386 GPSData_AntennaStat_ISig_4_56a 1;
BA_ "GenSigStartValue" SG_ 1386 GPSData_AntennaStat_ISig_4_56a 7;
BA_ "GenSigMaxLatency" SG_ 1386 GPSData_AntennaStat_ISig_4_56a 523;
BA_ "NeedsUpdateBit" SG_ 1386 GPSData_AntennaStat_ISig_4_56a 1;
BA_ "Platform_VMCU1_Sig" SG_ 1386 GPSData_AntennaStat_ISig_4_56a 1;
BA_ "GenSigSendType" SG_ 1386 GPSData_Longitude_ISig_4_56a 1;
BA_ "GenSigStartValue" SG_ 1386 GPSData_Longitude_ISig_4_56a 4294967295;
BA_ "GenSigMaxLatency" SG_ 1386 GPSData_Longitude_ISig_4_56a 523;
BA_ "NeedsUpdateBit" SG_ 1386 GPSData_Longitude_ISig_4_56a 1;
BA_ "Platform_VMCU1_Sig" SG_ 1386 GPSData_Longitude_ISig_4_56a 1;
BA_ "GenSigSendType" SG_ 1386 GPSData_VehSpeed_ISig_4_56a 1;
BA_ "GenSigStartValue" SG_ 1386 GPSData_VehSpeed_ISig_4_56a 65535;
BA_ "GenSigMaxLatency" SG_ 1386 GPSData_VehSpeed_ISig_4_56a 523;
BA_ "NeedsUpdateBit" SG_ 1386 GPSData_VehSpeed_ISig_4_56a 1;
BA_ "Platform_VMCU1_Sig" SG_ 1386 GPSData_VehSpeed_ISig_4_56a 1;
BA_ "GenSigSendType" SG_ 1386 GPSData_Altitude_ISig_4_56a 1;
BA_ "GenSigStartValue" SG_ 1386 GPSData_Altitude_ISig_4_56a 65535;
BA_ "GenSigMaxLatency" SG_ 1386 GPSData_Altitude_ISig_4_56a 523;
BA_ "NeedsUpdateBit" SG_ 1386 GPSData_Altitude_ISig_4_56a 1;
BA_ "Platform_VMCU1_Sig" SG_ 1386 GPSData_Altitude_ISig_4_56a 1;
BA_ "GenSigSendType" SG_ 1385 HMIIOM_BB2_19P_FCS_569 7;
BA_ "Platform_VMCU1_Sig" SG_ 1385 HMIIOM_BB2_19P_FCS_569 1;
BA_ "GenSigSendType" SG_ 1384 GPSData_Time_ISig_4_568 1;
BA_ "GenSigStartValue" SG_ 1384 GPSData_Time_ISig_4_568 4294967295;
BA_ "GenSigMaxLatency" SG_ 1384 GPSData_Time_ISig_4_568 523;
BA_ "NeedsUpdateBit" SG_ 1384 GPSData_Time_ISig_4_568 1;
BA_ "Platform_VMCU1_Sig" SG_ 1384 GPSData_Time_ISig_4_568 1;
BA_ "GenSigSendType" SG_ 1384 GPSData_HDOP_ISig_4_568 1;
BA_ "GenSigMaxLatency" SG_ 1384 GPSData_HDOP_ISig_4_568 523;
BA_ "NeedsUpdateBit" SG_ 1384 GPSData_HDOP_ISig_4_568 1;
BA_ "Platform_VMCU1_Sig" SG_ 1384 GPSData_HDOP_ISig_4_568 1;
BA_ "GenSigSendType" SG_ 1384 GPSData_Direction_ISig_4_568 1;
BA_ "GenSigMaxLatency" SG_ 1384 GPSData_Direction_ISig_4_568 523;
BA_ "NeedsUpdateBit" SG_ 1384 GPSData_Direction_ISig_4_568 1;
BA_ "Platform_VMCU1_Sig" SG_ 1384 GPSData_Direction_ISig_4_568 1;
BA_ "GenSigSendType" SG_ 1384 GPSData_Longitude_ISig_4_568 1;
BA_ "GenSigStartValue" SG_ 1384 GPSData_Longitude_ISig_4_568 4294967295;
BA_ "GenSigMaxLatency" SG_ 1384 GPSData_Longitude_ISig_4_568 523;
BA_ "NeedsUpdateBit" SG_ 1384 GPSData_Longitude_ISig_4_568 1;
BA_ "Platform_VMCU1_Sig" SG_ 1384 GPSData_Longitude_ISig_4_568 1;
BA_ "GenSigSendType" SG_ 1384 GPSData_sg_UB_ISig_4_568 7;
BA_ "Platform_VMCU1_Sig" SG_ 1384 GPSData_sg_UB_ISig_4_568 1;
BA_ "GenSigSendType" SG_ 1384 GPSData_VehSpeed_ISig_4_568 1;
BA_ "GenSigStartValue" SG_ 1384 GPSData_VehSpeed_ISig_4_568 65535;
BA_ "GenSigMaxLatency" SG_ 1384 GPSData_VehSpeed_ISig_4_568 523;
BA_ "NeedsUpdateBit" SG_ 1384 GPSData_VehSpeed_ISig_4_568 1;
BA_ "Platform_VMCU1_Sig" SG_ 1384 GPSData_VehSpeed_ISig_4_568 1;
BA_ "GenSigSendType" SG_ 1384 GPSData_Altitude_ISig_4_568 1;
BA_ "GenSigStartValue" SG_ 1384 GPSData_Altitude_ISig_4_568 65535;
BA_ "GenSigMaxLatency" SG_ 1384 GPSData_Altitude_ISig_4_568 523;
BA_ "NeedsUpdateBit" SG_ 1384 GPSData_Altitude_ISig_4_568 1;
BA_ "Platform_VMCU1_Sig" SG_ 1384 GPSData_Altitude_ISig_4_568 1;
BA_ "GenSigSendType" SG_ 1384 GPSData_Latitude_ISig_4_568 1;
BA_ "GenSigStartValue" SG_ 1384 GPSData_Latitude_ISig_4_568 4294967295;
BA_ "GenSigMaxLatency" SG_ 1384 GPSData_Latitude_ISig_4_568 523;
BA_ "NeedsUpdateBit" SG_ 1384 GPSData_Latitude_ISig_4_568 1;
BA_ "Platform_VMCU1_Sig" SG_ 1384 GPSData_Latitude_ISig_4_568 1;
BA_ "GenSigSendType" SG_ 1384 GPSData_AntennaStat_ISig_4_568 1;
BA_ "GenSigStartValue" SG_ 1384 GPSData_AntennaStat_ISig_4_568 7;
BA_ "GenSigMaxLatency" SG_ 1384 GPSData_AntennaStat_ISig_4_568 523;
BA_ "NeedsUpdateBit" SG_ 1384 GPSData_AntennaStat_ISig_4_568 1;
BA_ "Platform_VMCU1_Sig" SG_ 1384 GPSData_AntennaStat_ISig_4_568 1;
BA_ "GenSigCycleTime" SG_ 979 PinCodeEntered_value 100;
BA_ "GenSigCycleTimeActive" SG_ 979 PinCodeEntered_value 100;
BA_ "GenSigMaxLatency" SG_ 979 PinCodeEntered_value 89;
BA_ "Platform_VMCU1_Sig" SG_ 979 PinCodeEntered_value 1;
BA_ "GenSigCycleTime" SG_ 979 DynamicCode_rqst 100;
BA_ "GenSigCycleTimeActive" SG_ 979 DynamicCode_rqst 100;
BA_ "GenSigStartValue" SG_ 979 DynamicCode_rqst 7;
BA_ "GenSigMaxLatency" SG_ 979 DynamicCode_rqst 26;
BA_ "Platform_VMCU1_Sig" SG_ 979 DynamicCode_rqst 1;
BA_ "GenSigCycleTime" SG_ 979 LogDisplayedMessage_req 100;
BA_ "GenSigCycleTimeActive" SG_ 979 LogDisplayedMessage_req 100;
BA_ "GenSigMaxLatency" SG_ 979 LogDisplayedMessage_req 89;
BA_ "NeedsUpdateBit" SG_ 979 LogDisplayedMessage_req 1;
BA_ "Platform_VMCU1_Sig" SG_ 979 LogDisplayedMessage_req 1;
BA_ "GenSigSendType" SG_ 979 LogDisplayedMessage_req_UB 7;
BA_ "Platform_VMCU1_Sig" SG_ 979 LogDisplayedMessage_req_UB 1;
BA_ "GenSigCycleTime" SG_ 970 FirstAxleLowerPrioRequested_ISig 100;
BA_ "GenSigCycleTimeActive" SG_ 970 FirstAxleLowerPrioRequested_ISig 100;
BA_ "GenSigStartValue" SG_ 970 FirstAxleLowerPrioRequested_ISig 7;
BA_ "NeedsUpdateBit" SG_ 970 FirstAxleLowerPrioRequested_ISig 1;
BA_ "SystemSignalLongSymbol" SG_ 970 FirstAxleLowerPrioRequested_ISig "FirstAxleLowerPrioRequested_ISig_4";
BA_ "GenSigCycleTime" SG_ 970 Synch_Unsynch_Mode_stat 100;
BA_ "GenSigCycleTimeActive" SG_ 970 Synch_Unsynch_Mode_stat 100;
BA_ "GenSigStartValue" SG_ 970 Synch_Unsynch_Mode_stat 7;
BA_ "GenSigMaxLatency" SG_ 970 Synch_Unsynch_Mode_stat 89;
BA_ "Platform_VMCU1_Sig" SG_ 970 Synch_Unsynch_Mode_stat 1;
BA_ "GenSigCycleTime" SG_ 970 PreTripIndication3_ISig_4 100;
BA_ "GenSigCycleTimeActive" SG_ 970 PreTripIndication3_ISig_4 100;
BA_ "GenSigCycleTime" SG_ 970 SelectedSpeedUnit_stat_ISig_4 100;
BA_ "GenSigCycleTimeActive" SG_ 970 SelectedSpeedUnit_stat_ISig_4 100;
BA_ "GenSigStartValue" SG_ 970 SelectedSpeedUnit_stat_ISig_4 3;
BA_ "GenSigMaxLatency" SG_ 970 SelectedSpeedUnit_stat_ISig_4 89;
BA_ "Platform_VMCU1_Sig" SG_ 970 SelectedSpeedUnit_stat_ISig_4 1;
BA_ "GenSigCycleTime" SG_ 970 SelectedLanguage_stat_ISig_4 100;
BA_ "GenSigCycleTimeActive" SG_ 970 SelectedLanguage_stat_ISig_4 100;
BA_ "GenSigStartValue" SG_ 970 SelectedLanguage_stat_ISig_4 63;
BA_ "GenSigMaxLatency" SG_ 970 SelectedLanguage_stat_ISig_4 89;
BA_ "Platform_VMCU1_Sig" SG_ 970 SelectedLanguage_stat_ISig_4 1;
BA_ "GenSigCycleTime" SG_ 970 LampCheck_rqst_ISig_4 100;
BA_ "GenSigCycleTimeActive" SG_ 970 LampCheck_rqst_ISig_4 100;
BA_ "GenSigStartValue" SG_ 970 LampCheck_rqst_ISig_4 3;
BA_ "Platform_VMCU1_Sig" SG_ 970 LampCheck_rqst_ISig_4 1;
BA_ "GenSigCycleTime" SG_ 970 SelectedWeightUnit_stat_ISig_4 100;
BA_ "GenSigCycleTimeActive" SG_ 970 SelectedWeightUnit_stat_ISig_4 100;
BA_ "GenSigStartValue" SG_ 970 SelectedWeightUnit_stat_ISig_4 3;
BA_ "Platform_VMCU1_Sig" SG_ 970 SelectedWeightUnit_stat_ISig_4 1;
BA_ "GenSigSendType" SG_ 970 FirstAxleLowerPrioRequested_UB_I 7;
BA_ "SystemSignalLongSymbol" SG_ 970 FirstAxleLowerPrioRequested_UB_I "FirstAxleLowerPrioRequested_UB_ISig_4";
BA_ "GenSigCycleTime" SG_ 970 SpeedLockingInhibition_stat 100;
BA_ "GenSigCycleTimeActive" SG_ 970 SpeedLockingInhibition_stat 100;
BA_ "GenSigStartValue" SG_ 970 SpeedLockingInhibition_stat 7;
BA_ "GenSigMaxLatency" SG_ 970 SpeedLockingInhibition_stat 89;
BA_ "Platform_VMCU1_Sig" SG_ 970 SpeedLockingInhibition_stat 1;
BA_ "GenSigCycleTime" SG_ 970 DriverMemory_rqst_ISig_4 100;
BA_ "GenSigCycleTimeActive" SG_ 970 DriverMemory_rqst_ISig_4 100;
BA_ "GenSigStartValue" SG_ 970 DriverMemory_rqst_ISig_4 31;
BA_ "Platform_VMCU1_Sig" SG_ 970 DriverMemory_rqst_ISig_4 1;
BA_ "GenSigCycleTime" SG_ 970 SelectedTimeFormat_stat_ISig_4 100;
BA_ "GenSigCycleTimeActive" SG_ 970 SelectedTimeFormat_stat_ISig_4 100;
BA_ "GenSigStartValue" SG_ 970 SelectedTimeFormat_stat_ISig_4 3;
BA_ "Platform_VMCU1_Sig" SG_ 970 SelectedTimeFormat_stat_ISig_4 1;
BA_ "GenSigCycleTime" SG_ 970 MaintInfo_rqst 100;
BA_ "GenSigCycleTimeActive" SG_ 970 MaintInfo_rqst 100;
BA_ "GenSigStartValue" SG_ 970 MaintInfo_rqst 3;
BA_ "GenSigCycleTime" SG_ 970 LCSSoundSettingRequest 100;
BA_ "GenSigCycleTimeActive" SG_ 970 LCSSoundSettingRequest 100;
BA_ "GenSigStartValue" SG_ 970 LCSSoundSettingRequest 3;
BA_ "Platform_VMCU1_Sig" SG_ 970 LCSSoundSettingRequest 1;
BA_ "GenSigCycleTime" SG_ 851 BunkBacklightCmd_ISig_4 100;
BA_ "GenSigCycleTimeActive" SG_ 851 BunkBacklightCmd_ISig_4 100;
BA_ "GenSigMaxLatency" SG_ 851 BunkBacklightCmd_ISig_4 71;
BA_ "Platform_VMCU1_Sig" SG_ 851 BunkBacklightCmd_ISig_4 1;
BA_ "GenSigCycleTime" SG_ 1270 SpeedAdaptEnableRqst_SpeedLimit 100;
BA_ "GenSigCycleTimeActive" SG_ 1270 SpeedAdaptEnableRqst_SpeedLimit 100;
BA_ "GenSigStartValue" SG_ 1270 SpeedAdaptEnableRqst_SpeedLimit 3;
BA_ "GenSigCycleTime" SG_ 1270 SpeedAdaptEnableRqst_Curve 100;
BA_ "GenSigCycleTimeActive" SG_ 1270 SpeedAdaptEnableRqst_Curve 100;
BA_ "GenSigStartValue" SG_ 1270 SpeedAdaptEnableRqst_Curve 3;
BA_ "GenSigCycleTime" SG_ 1270 CabLightIntensity_stat_ISig_4 100;
BA_ "GenSigCycleTimeActive" SG_ 1270 CabLightIntensity_stat_ISig_4 100;
BA_ "GenSigStartValue" SG_ 1270 CabLightIntensity_stat_ISig_4 255;
BA_ "GenSigMaxLatency" SG_ 1270 CabLightIntensity_stat_ISig_4 56;
BA_ "Platform_VMCU1_Sig" SG_ 1270 CabLightIntensity_stat_ISig_4 1;
BA_ "SeToolAncestorID_SIGNAL" SG_ 1270 CabLightIntensity_stat_ISig_4 "x0000001D041AFE81";
BA_ "SeToolItemID_SIGNAL" SG_ 1270 CabLightIntensity_stat_ISig_4 "x0000001D0433F018";
BA_ "SeToolName_SIGNAL" SG_ 1270 CabLightIntensity_stat_ISig_4 "LightSensor_Data";
BA_ "SeToolVersion_SIGNAL" SG_ 1270 CabLightIntensity_stat_ISig_4 "2";
BA_ "GenSigCycleTime" SG_ 1270 SpeedAdaptEnableRqst_SlowTraffic 100;
BA_ "GenSigCycleTimeActive" SG_ 1270 SpeedAdaptEnableRqst_SlowTraffic 100;
BA_ "GenSigStartValue" SG_ 1270 SpeedAdaptEnableRqst_SlowTraffic 3;
BA_ "GenSigCycleTime" SG_ 1270 ExtTimeData_ExtTime_ISig_4 100;
BA_ "GenSigCycleTimeActive" SG_ 1270 ExtTimeData_ExtTime_ISig_4 100;
BA_ "GenSigStartValue" SG_ 1270 ExtTimeData_ExtTime_ISig_4 4294967295;
BA_ "GenSigCycleTime" SG_ 1270 ExtTimeData_Quality_ISig_4 100;
BA_ "GenSigCycleTimeActive" SG_ 1270 ExtTimeData_Quality_ISig_4 100;
BA_ "GenSigStartValue" SG_ 1270 ExtTimeData_Quality_ISig_4 255;
BA_ "GenSigCycleTime" SG_ 1270 SpeedAdaptationLevelRqst 100;
BA_ "GenSigCycleTimeActive" SG_ 1270 SpeedAdaptationLevelRqst 100;
BA_ "GenSigStartValue" SG_ 1270 SpeedAdaptationLevelRqst 7;
BA_ "GenSigCycleTime" SG_ 739 CCBOverspeedRequest 100;
BA_ "GenSigCycleTimeActive" SG_ 739 CCBOverspeedRequest 100;
BA_ "GenSigStartValue" SG_ 739 CCBOverspeedRequest 65535;
BA_ "GenSigMaxLatency" SG_ 739 CCBOverspeedRequest 41;
BA_ "Platform_VMCU1_Sig" SG_ 739 CCBOverspeedRequest 1;
BA_ "GenSigCycleTime" SG_ 739 XRSLDriverRequest 100;
BA_ "GenSigCycleTimeActive" SG_ 739 XRSLDriverRequest 100;
BA_ "GenSigStartValue" SG_ 739 XRSLDriverRequest 15;
BA_ "GenSigMaxLatency" SG_ 739 XRSLDriverRequest 41;
BA_ "Platform_VMCU1_Sig" SG_ 739 XRSLDriverRequest 1;
BA_ "GenSigCycleTime" SG_ 739 DHCActiveRequest 100;
BA_ "GenSigCycleTimeActive" SG_ 739 DHCActiveRequest 100;
BA_ "GenSigStartValue" SG_ 739 DHCActiveRequest 3;
BA_ "GenSigCycleTime" SG_ 739 CCEnableRequest_ISig_4 100;
BA_ "GenSigCycleTimeActive" SG_ 739 CCEnableRequest_ISig_4 100;
BA_ "GenSigStartValue" SG_ 739 CCEnableRequest_ISig_4 3;
BA_ "GenSigMaxLatency" SG_ 739 CCEnableRequest_ISig_4 41;
BA_ "Platform_VMCU1_Sig" SG_ 739 CCEnableRequest_ISig_4 1;
BA_ "GenSigCycleTime" SG_ 739 CCRequestedPresetSpeed 100;
BA_ "GenSigCycleTimeActive" SG_ 739 CCRequestedPresetSpeed 100;
BA_ "GenSigStartValue" SG_ 739 CCRequestedPresetSpeed 65535;
BA_ "GenSigMaxLatency" SG_ 739 CCRequestedPresetSpeed 41;
BA_ "Platform_VMCU1_Sig" SG_ 739 CCRequestedPresetSpeed 1;
BA_ "GenSigCycleTime" SG_ 739 CCDriverRequest 100;
BA_ "GenSigCycleTimeActive" SG_ 739 CCDriverRequest 100;
BA_ "GenSigStartValue" SG_ 739 CCDriverRequest 15;
BA_ "GenSigMaxLatency" SG_ 739 CCDriverRequest 41;
BA_ "Platform_VMCU1_Sig" SG_ 739 CCDriverRequest 1;
BA_ "GenSigCycleTime" SG_ 739 RSLMgrsetTRSLOpCtrl 100;
BA_ "GenSigCycleTimeActive" SG_ 739 RSLMgrsetTRSLOpCtrl 100;
BA_ "GenSigStartValue" SG_ 739 RSLMgrsetTRSLOpCtrl 3;
BA_ "GenSigCycleTime" SG_ 390 EcoRollEnableRequest_ISig_4 100;
BA_ "GenSigCycleTimeActive" SG_ 390 EcoRollEnableRequest_ISig_4 100;
BA_ "GenSigStartValue" SG_ 390 EcoRollEnableRequest_ISig_4 3;
BA_ "Platform_VMCU1_Sig" SG_ 390 EcoRollEnableRequest_ISig_4 1;
BA_ "GenSigCycleTime" SG_ 390 SelectedEcoCruiseLevel_ISig_4 100;
BA_ "GenSigCycleTimeActive" SG_ 390 SelectedEcoCruiseLevel_ISig_4 100;
BA_ "GenSigStartValue" SG_ 390 SelectedEcoCruiseLevel_ISig_4 7;
BA_ "Platform_VMCU1_Sig" SG_ 390 SelectedEcoCruiseLevel_ISig_4 1;
BA_ "GenSigCycleTime" SG_ 514 PS_GearSelectionMode_ISig_4 100;
BA_ "GenSigCycleTimeActive" SG_ 514 PS_GearSelectionMode_ISig_4 100;
BA_ "GenSigStartValue" SG_ 514 PS_GearSelectionMode_ISig_4 7;
BA_ "GenSigCycleTime" SG_ 514 WaterInFuelDrainRequest 100;
BA_ "GenSigCycleTimeActive" SG_ 514 WaterInFuelDrainRequest 100;
BA_ "GenSigMaxLatency" SG_ 514 WaterInFuelDrainRequest 26;
BA_ "Platform_VMCU1_Sig" SG_ 514 WaterInFuelDrainRequest 1;
BA_ "SeToolAncestorID_SIGNAL" SG_ 514 WaterInFuelDrainRequest "x0000001D041410E9";
BA_ "SeToolItemID_SIGNAL" SG_ 514 WaterInFuelDrainRequest "x0000001D041410E9";
BA_ "SeToolName_SIGNAL" SG_ 514 WaterInFuelDrainRequest "WaterInFuelDrainRequest";
BA_ "SeToolVersion_SIGNAL" SG_ 514 WaterInFuelDrainRequest "1";
BA_ "GenSigCycleTime" SG_ 514 SW_Mute_ButtonStatus_6_ISig_4 100;
BA_ "GenSigCycleTimeActive" SG_ 514 SW_Mute_ButtonStatus_6_ISig_4 100;
BA_ "GenSigStartValue" SG_ 514 SW_Mute_ButtonStatus_6_ISig_4 3;
BA_ "GenSigCycleTime" SG_ 514 FuncIndIlluminationLevel_ISig_4 100;
BA_ "GenSigCycleTimeActive" SG_ 514 FuncIndIlluminationLevel_ISig_4 100;
BA_ "GenSigStartValue" SG_ 514 FuncIndIlluminationLevel_ISig_4 1;
BA_ "GenSigMaxLatency" SG_ 514 FuncIndIlluminationLevel_ISig_4 26;
BA_ "Platform_VMCU1_Sig" SG_ 514 FuncIndIlluminationLevel_ISig_4 1;
BA_ "SeToolAncestorID_SIGNAL" SG_ 514 FuncIndIlluminationLevel_ISig_4 "x0000001D043A8396";
BA_ "SeToolItemID_SIGNAL" SG_ 514 FuncIndIlluminationLevel_ISig_4 "x0000001D043A8396";
BA_ "SeToolName_SIGNAL" SG_ 514 FuncIndIlluminationLevel_ISig_4 "FuncIndIlluminationLevel";
BA_ "SeToolVersion_SIGNAL" SG_ 514 FuncIndIlluminationLevel_ISig_4 "1";
BA_ "GenSigCycleTime" SG_ 514 SW_VolDown_ButtonStatus_6_ISig_4 100;
BA_ "GenSigCycleTimeActive" SG_ 514 SW_VolDown_ButtonStatus_6_ISig_4 100;
BA_ "GenSigStartValue" SG_ 514 SW_VolDown_ButtonStatus_6_ISig_4 3;
BA_ "GenSigCycleTime" SG_ 514 ResumeRequestForACC 100;
BA_ "GenSigCycleTimeActive" SG_ 514 ResumeRequestForACC 100;
BA_ "GenSigStartValue" SG_ 514 ResumeRequestForACC 3;
BA_ "GenSigCycleTime" SG_ 514 CACCTimeGapRqst 100;
BA_ "GenSigCycleTimeActive" SG_ 514 CACCTimeGapRqst 100;
BA_ "GenSigStartValue" SG_ 514 CACCTimeGapRqst 3;
BA_ "GenSigCycleTime" SG_ 514 SWSpeedControlAdjustMode 100;
BA_ "GenSigCycleTimeActive" SG_ 514 SWSpeedControlAdjustMode 100;
BA_ "GenSigStartValue" SG_ 514 SWSpeedControlAdjustMode 15;
BA_ "GenSigMaxLatency" SG_ 514 SWSpeedControlAdjustMode 89;
BA_ "Platform_VMCU1_Sig" SG_ 514 SWSpeedControlAdjustMode 1;
BA_ "GenSigCycleTime" SG_ 514 ACCTimeGapRqst 100;
BA_ "GenSigCycleTimeActive" SG_ 514 ACCTimeGapRqst 100;
BA_ "GenSigStartValue" SG_ 514 ACCTimeGapRqst 7;
BA_ "GenSigMaxLatency" SG_ 514 ACCTimeGapRqst 26;
BA_ "Platform_VMCU1_Sig" SG_ 514 ACCTimeGapRqst 1;
BA_ "SeToolAncestorID_SIGNAL" SG_ 514 ACCTimeGapRqst "x0000001D04146F87";
BA_ "SeToolItemID_SIGNAL" SG_ 514 ACCTimeGapRqst "x0000001D0420F337";
BA_ "SeToolName_SIGNAL" SG_ 514 ACCTimeGapRqst "ACCTimeGapRqst";
BA_ "SeToolVersion_SIGNAL" SG_ 514 ACCTimeGapRqst "2";
BA_ "GenSigCycleTime" SG_ 514 SWSpdCtrlButtonsStatus6 100;
BA_ "GenSigCycleTimeActive" SG_ 514 SWSpdCtrlButtonsStatus6 100;
BA_ "GenSigStartValue" SG_ 514 SWSpdCtrlButtonsStatus6 15;
BA_ "GenSigCycleTime" SG_ 514 ACCEnableRqst 100;
BA_ "GenSigCycleTimeActive" SG_ 514 ACCEnableRqst 100;
BA_ "GenSigStartValue" SG_ 514 ACCEnableRqst 3;
BA_ "GenSigMaxLatency" SG_ 514 ACCEnableRqst 26;
BA_ "Platform_VMCU1_Sig" SG_ 514 ACCEnableRqst 1;
BA_ "SeToolAncestorID_SIGNAL" SG_ 514 ACCEnableRqst "x0000001D0414B8A6";
BA_ "SeToolItemID_SIGNAL" SG_ 514 ACCEnableRqst "x0000001D0414B8A6";
BA_ "SeToolName_SIGNAL" SG_ 514 ACCEnableRqst "ACCEnableRqst";
BA_ "SeToolVersion_SIGNAL" SG_ 514 ACCEnableRqst "1";
BA_ "GenSigCycleTime" SG_ 514 StopAlert_cmd 100;
BA_ "GenSigCycleTimeActive" SG_ 514 StopAlert_cmd 100;
BA_ "GenSigStartValue" SG_ 514 StopAlert_cmd 7;
BA_ "Platform_VMCU1_Sig" SG_ 514 StopAlert_cmd 1;
BA_ "SeToolAncestorID_SIGNAL" SG_ 514 StopAlert_cmd "x0000001D04182F7F";
BA_ "SeToolItemID_SIGNAL" SG_ 514 StopAlert_cmd "x0000001D04295469";
BA_ "SeToolName_SIGNAL" SG_ 514 StopAlert_cmd "StopAlert_cmd";
BA_ "SeToolVersion_SIGNAL" SG_ 514 StopAlert_cmd "4";
BA_ "GenSigCycleTime" SG_ 514 SW_VolUp_ButtonStatus_6_ISig_4 100;
BA_ "GenSigCycleTimeActive" SG_ 514 SW_VolUp_ButtonStatus_6_ISig_4 100;
BA_ "GenSigStartValue" SG_ 514 SW_VolUp_ButtonStatus_6_ISig_4 3;
BA_ "GenSigCycleTime" SG_ 514 BacklightCmd_ISig_4 100;
BA_ "GenSigCycleTimeActive" SG_ 514 BacklightCmd_ISig_4 100;
BA_ "GenSigMaxLatency" SG_ 514 BacklightCmd_ISig_4 26;
BA_ "Platform_VMCU1_Sig" SG_ 514 BacklightCmd_ISig_4 1;
BA_ "SeToolAncestorID_SIGNAL" SG_ 514 BacklightCmd_ISig_4 "x0000001D0439DDD1";
BA_ "SeToolItemID_SIGNAL" SG_ 514 BacklightCmd_ISig_4 "x0000001D043A84D3";
BA_ "SeToolName_SIGNAL" SG_ 514 BacklightCmd_ISig_4 "BacklightCmd";
BA_ "SeToolVersion_SIGNAL" SG_ 514 BacklightCmd_ISig_4 "2";
BA_ "GenSigCycleTime" SG_ 514 CMTelltale_stat 100;
BA_ "GenSigCycleTimeActive" SG_ 514 CMTelltale_stat 100;
BA_ "GenSigStartValue" SG_ 514 CMTelltale_stat 7;
BA_ "Platform_VMCU1_Sig" SG_ 514 CMTelltale_stat 1;
BA_ "GenSigCycleTime" SG_ 1288 OBDDrivingCycle 100;
BA_ "GenSigCycleTimeActive" SG_ 1288 OBDDrivingCycle 100;
BA_ "GenSigStartValue" SG_ 1288 OBDDrivingCycle 65535;
BA_ "GenSigCycleTime" SG_ 1288 EcoCruisePwtMaxOvSpeedLev3 100;
BA_ "GenSigCycleTimeActive" SG_ 1288 EcoCruisePwtMaxOvSpeedLev3 100;
BA_ "GenSigStartValue" SG_ 1288 EcoCruisePwtMaxOvSpeedLev3 31;
BA_ "Platform_VMCU1_Sig" SG_ 1288 EcoCruisePwtMaxOvSpeedLev3 1;
BA_ "GenSigCycleTime" SG_ 1288 EcoCruisePwtMaxOvSpeedLev0 100;
BA_ "GenSigCycleTimeActive" SG_ 1288 EcoCruisePwtMaxOvSpeedLev0 100;
BA_ "GenSigStartValue" SG_ 1288 EcoCruisePwtMaxOvSpeedLev0 31;
BA_ "Platform_VMCU1_Sig" SG_ 1288 EcoCruisePwtMaxOvSpeedLev0 1;
BA_ "GenSigCycleTime" SG_ 1288 EcoCruisePwtMaxUnSpeedLev0 100;
BA_ "GenSigCycleTimeActive" SG_ 1288 EcoCruisePwtMaxUnSpeedLev0 100;
BA_ "GenSigStartValue" SG_ 1288 EcoCruisePwtMaxUnSpeedLev0 31;
BA_ "Platform_VMCU1_Sig" SG_ 1288 EcoCruisePwtMaxUnSpeedLev0 1;
BA_ "GenSigCycleTime" SG_ 1288 EcoCruisePwtMaxOvSpeedLev2 100;
BA_ "GenSigCycleTimeActive" SG_ 1288 EcoCruisePwtMaxOvSpeedLev2 100;
BA_ "GenSigStartValue" SG_ 1288 EcoCruisePwtMaxOvSpeedLev2 31;
BA_ "Platform_VMCU1_Sig" SG_ 1288 EcoCruisePwtMaxOvSpeedLev2 1;
BA_ "GenSigCycleTime" SG_ 1288 EcoCruisePwtMaxOvSpeedLev1 100;
BA_ "GenSigCycleTimeActive" SG_ 1288 EcoCruisePwtMaxOvSpeedLev1 100;
BA_ "GenSigStartValue" SG_ 1288 EcoCruisePwtMaxOvSpeedLev1 31;
BA_ "Platform_VMCU1_Sig" SG_ 1288 EcoCruisePwtMaxOvSpeedLev1 1;
BA_ "GenSigCycleTime" SG_ 1288 EcoCruisePwtMaxUnSpeedLev3 100;
BA_ "GenSigCycleTimeActive" SG_ 1288 EcoCruisePwtMaxUnSpeedLev3 100;
BA_ "GenSigStartValue" SG_ 1288 EcoCruisePwtMaxUnSpeedLev3 31;
BA_ "Platform_VMCU1_Sig" SG_ 1288 EcoCruisePwtMaxUnSpeedLev3 1;
BA_ "GenSigCycleTime" SG_ 1288 EcoCruisePwtMaxUnSpeedLev1 100;
BA_ "GenSigCycleTimeActive" SG_ 1288 EcoCruisePwtMaxUnSpeedLev1 100;
BA_ "GenSigStartValue" SG_ 1288 EcoCruisePwtMaxUnSpeedLev1 31;
BA_ "Platform_VMCU1_Sig" SG_ 1288 EcoCruisePwtMaxUnSpeedLev1 1;
BA_ "GenSigCycleTime" SG_ 1288 EcoCruisePwtMaxUnSpeedLev2 100;
BA_ "GenSigCycleTimeActive" SG_ 1288 EcoCruisePwtMaxUnSpeedLev2 100;
BA_ "GenSigStartValue" SG_ 1288 EcoCruisePwtMaxUnSpeedLev2 31;
BA_ "Platform_VMCU1_Sig" SG_ 1288 EcoCruisePwtMaxUnSpeedLev2 1;
BA_ "GenSigCycleTime" SG_ 1285 TotPTOLNGHighAccuracy 100;
BA_ "GenSigCycleTimeActive" SG_ 1285 TotPTOLNGHighAccuracy 100;
BA_ "GenSigStartValue" SG_ 1285 TotPTOLNGHighAccuracy 4294967295;
BA_ "Platform_VMCU1_Sig" SG_ 1285 TotPTOLNGHighAccuracy 1;
BA_ "GenSigCycleTime" SG_ 1282 ExhManif_EMAIAirTankPres_ISig_4 100;
BA_ "GenSigCycleTimeActive" SG_ 1282 ExhManif_EMAIAirTankPres_ISig_4 100;
BA_ "GenSigStartValue" SG_ 1282 ExhManif_EMAIAirTankPres_ISig_4 255;
BA_ "GenSigCycleTime" SG_ 1282 EngineFuelMode 100;
BA_ "GenSigCycleTimeActive" SG_ 1282 EngineFuelMode 100;
BA_ "GenSigStartValue" SG_ 1282 EngineFuelMode 3;
BA_ "Platform_VMCU1_Sig" SG_ 1282 EngineFuelMode 1;
BA_ "GenSigCycleTime" SG_ 1282 LNGOperatorInducementReason_ISig 100;
BA_ "GenSigCycleTimeActive" SG_ 1282 LNGOperatorInducementReason_ISig 100;
BA_ "GenSigStartValue" SG_ 1282 LNGOperatorInducementReason_ISig 7;
BA_ "Platform_VMCU1_Sig" SG_ 1282 LNGOperatorInducementReason_ISig 1;
BA_ "SystemSignalLongSymbol" SG_ 1282 LNGOperatorInducementReason_ISig "LNGOperatorInducementReason_ISig_4";
BA_ "GenSigCycleTime" SG_ 1282 EngineTotalLngConsumed_ISig_4 100;
BA_ "GenSigCycleTimeActive" SG_ 1282 EngineTotalLngConsumed_ISig_4 100;
BA_ "GenSigStartValue" SG_ 1282 EngineTotalLngConsumed_ISig_4 4294967295;
BA_ "Platform_VMCU1_Sig" SG_ 1282 EngineTotalLngConsumed_ISig_4 1;
BA_ "GenSigCycleTime" SG_ 1252 DistLeftToSevereInducement_OBD 100;
BA_ "GenSigCycleTimeActive" SG_ 1252 DistLeftToSevereInducement_OBD 100;
BA_ "GenSigStartValue" SG_ 1252 DistLeftToSevereInducement_OBD 255;
BA_ "Platform_VMCU1_Sig" SG_ 1252 DistLeftToSevereInducement_OBD 1;
BA_ "GenSigCycleTime" SG_ 1252 TopGearUseDistance_ISig_4 100;
BA_ "GenSigCycleTimeActive" SG_ 1252 TopGearUseDistance_ISig_4 100;
BA_ "GenSigStartValue" SG_ 1252 TopGearUseDistance_ISig_4 4294967295;
BA_ "Platform_VMCU1_Sig" SG_ 1252 TopGearUseDistance_ISig_4 1;
BA_ "GenSigCycleTime" SG_ 1252 EMS_Available_Log_ISig_4 100;
BA_ "GenSigCycleTimeActive" SG_ 1252 EMS_Available_Log_ISig_4 100;
BA_ "GenSigStartValue" SG_ 1252 EMS_Available_Log_ISig_4 255;
BA_ "GenSigSendType" SG_ 961 EMS_BB2_11S_FCS 7;
BA_ "Platform_VMCU1_Sig" SG_ 961 EMS_BB2_11S_FCS 1;
BA_ "GenSigSendType" SG_ 958 KeyID_EngineStartAuth 1;
BA_ "GenSigMaxLatency" SG_ 958 KeyID_EngineStartAuth 100;
BA_ "Platform_VMCU1_Sig" SG_ 958 KeyID_EngineStartAuth 1;
BA_ "GenSigCycleTime" SG_ 1374 TimeLeftToTorqueReduction_OBD 100;
BA_ "GenSigCycleTimeActive" SG_ 1374 TimeLeftToTorqueReduction_OBD 100;
BA_ "GenSigStartValue" SG_ 1374 TimeLeftToTorqueReduction_OBD 511;
BA_ "GenSigMaxLatency" SG_ 1374 TimeLeftToTorqueReduction_OBD 257;
BA_ "Platform_VMCU1_Sig" SG_ 1374 TimeLeftToTorqueReduction_OBD 1;
BA_ "SeToolAncestorID_SIGNAL" SG_ 1374 TimeLeftToTorqueReduction_OBD "x0000001D043B9BEC";
BA_ "SeToolItemID_SIGNAL" SG_ 1374 TimeLeftToTorqueReduction_OBD "x0000001D043B9BEC";
BA_ "SeToolName_SIGNAL" SG_ 1374 TimeLeftToTorqueReduction_OBD "TimeLeftToTorqueReduction_OBD";
BA_ "SeToolVersion_SIGNAL" SG_ 1374 TimeLeftToTorqueReduction_OBD "1";
BA_ "GenSigCycleTime" SG_ 1374 AdblueTotalConsumed_ISig_4 100;
BA_ "GenSigCycleTimeActive" SG_ 1374 AdblueTotalConsumed_ISig_4 100;
BA_ "GenSigStartValue" SG_ 1374 AdblueTotalConsumed_ISig_4 4294967295;
BA_ "Platform_VMCU1_Sig" SG_ 1374 AdblueTotalConsumed_ISig_4 1;
BA_ "GenSigCycleTime" SG_ 1374 MIStatus_ISig_4 100;
BA_ "GenSigCycleTimeActive" SG_ 1374 MIStatus_ISig_4 100;
BA_ "GenSigStartValue" SG_ 1374 MIStatus_ISig_4 3;
BA_ "GenSigMaxLatency" SG_ 1374 MIStatus_ISig_4 257;
BA_ "Platform_VMCU1_Sig" SG_ 1374 MIStatus_ISig_4 1;
BA_ "SeToolAncestorID_SIGNAL" SG_ 1374 MIStatus_ISig_4 "x0000001D04147511";
BA_ "SeToolItemID_SIGNAL" SG_ 1374 MIStatus_ISig_4 "x0000001D0423C9EA";
BA_ "SeToolName_SIGNAL" SG_ 1374 MIStatus_ISig_4 "MIStatus";
BA_ "SeToolVersion_SIGNAL" SG_ 1374 MIStatus_ISig_4 "2";
BA_ "GenSigCycleTime" SG_ 1374 TorqueReductionStatus_OBD 100;
BA_ "GenSigCycleTimeActive" SG_ 1374 TorqueReductionStatus_OBD 100;
BA_ "GenSigStartValue" SG_ 1374 TorqueReductionStatus_OBD 7;
BA_ "GenSigMaxLatency" SG_ 1374 TorqueReductionStatus_OBD 257;
BA_ "Platform_VMCU1_Sig" SG_ 1374 TorqueReductionStatus_OBD 1;
BA_ "SeToolAncestorID_SIGNAL" SG_ 1374 TorqueReductionStatus_OBD "x0000001D043B9BA6";
BA_ "SeToolItemID_SIGNAL" SG_ 1374 TorqueReductionStatus_OBD "x0000001D043B9BA6";
BA_ "SeToolName_SIGNAL" SG_ 1374 TorqueReductionStatus_OBD "TorqueReductionStatus_OBD";
BA_ "SeToolVersion_SIGNAL" SG_ 1374 TorqueReductionStatus_OBD "1";
BA_ "GenSigCycleTime" SG_ 1374 SCROperatorInducementSeverity 100;
BA_ "GenSigCycleTimeActive" SG_ 1374 SCROperatorInducementSeverity 100;
BA_ "GenSigStartValue" SG_ 1374 SCROperatorInducementSeverity 7;
BA_ "Platform_VMCU1_Sig" SG_ 1374 SCROperatorInducementSeverity 1;
BA_ "GenSigCycleTime" SG_ 1374 SCROperatorInducementReason 100;
BA_ "GenSigCycleTimeActive" SG_ 1374 SCROperatorInducementReason 100;
BA_ "GenSigStartValue" SG_ 1374 SCROperatorInducementReason 7;
BA_ "Platform_VMCU1_Sig" SG_ 1374 SCROperatorInducementReason 1;
BA_ "GenSigCycleTime" SG_ 1374 MIDistinctWarning 100;
BA_ "GenSigCycleTimeActive" SG_ 1374 MIDistinctWarning 100;
BA_ "GenSigStartValue" SG_ 1374 MIDistinctWarning 3;
BA_ "GenSigMaxLatency" SG_ 1374 MIDistinctWarning 257;
BA_ "Platform_VMCU1_Sig" SG_ 1374 MIDistinctWarning 1;
BA_ "SeToolAncestorID_SIGNAL" SG_ 1374 MIDistinctWarning "x0000001D04147513";
BA_ "SeToolItemID_SIGNAL" SG_ 1374 MIDistinctWarning "x0000001D0423C9E0";
BA_ "SeToolName_SIGNAL" SG_ 1374 MIDistinctWarning "MIDistinctWarning";
BA_ "SeToolVersion_SIGNAL" SG_ 1374 MIDistinctWarning "2";
BA_ "GenSigCycleTime" SG_ 1374 MIStatusExtEMS 100;
BA_ "GenSigCycleTimeActive" SG_ 1374 MIStatusExtEMS 100;
BA_ "GenSigStartValue" SG_ 1374 MIStatusExtEMS 3;
BA_ "Platform_VMCU1_Sig" SG_ 1374 MIStatusExtEMS 1;
BA_ "GenSigCycleTime" SG_ 1374 MIDistinctWarningExtEMS_ISig_4 100;
BA_ "GenSigCycleTimeActive" SG_ 1374 MIDistinctWarningExtEMS_ISig_4 100;
BA_ "GenSigStartValue" SG_ 1374 MIDistinctWarningExtEMS_ISig_4 15;
BA_ "Platform_VMCU1_Sig" SG_ 1374 MIDistinctWarningExtEMS_ISig_4 1;
BA_ "GenSigSendType" SG_ 1342 EMS_BB2_09S_FCS 7;
BA_ "Platform_VMCU1_Sig" SG_ 1342 EMS_BB2_09S_FCS 1;
BA_ "GenSigSendType" SG_ 1341 ECU4VIN_stat 1;
BA_ "GenSigMaxLatency" SG_ 1341 ECU4VIN_stat 137;
BA_ "Platform_VMCU1_Sig" SG_ 1341 ECU4VIN_stat 1;
BA_ "GenSigCycleTime" SG_ 1392 EngineRunningTime_ISig_4 100;
BA_ "GenSigCycleTimeActive" SG_ 1392 EngineRunningTime_ISig_4 100;
BA_ "GenSigStartValue" SG_ 1392 EngineRunningTime_ISig_4 4294967295;
BA_ "Platform_VMCU1_Sig" SG_ 1392 EngineRunningTime_ISig_4 1;
BA_ "GenSigCycleTime" SG_ 1392 TotPTOFuelHighAccuracy 100;
BA_ "GenSigCycleTimeActive" SG_ 1392 TotPTOFuelHighAccuracy 100;
BA_ "GenSigStartValue" SG_ 1392 TotPTOFuelHighAccuracy 4294967295;
BA_ "Platform_VMCU1_Sig" SG_ 1392 TotPTOFuelHighAccuracy 1;
BA_ "GenSigCycleTime" SG_ 1391 OilPrediction_Quality 100;
BA_ "GenSigCycleTimeActive" SG_ 1391 OilPrediction_Quality 100;
BA_ "GenSigStartValue" SG_ 1391 OilPrediction_Quality 7;
BA_ "Platform_VMCU1_Sig" SG_ 1391 OilPrediction_Quality 1;
BA_ "GenSigCycleTime" SG_ 1391 TimeLeftToVehSpdReduction_OBD 100;
BA_ "GenSigCycleTimeActive" SG_ 1391 TimeLeftToVehSpdReduction_OBD 100;
BA_ "GenSigStartValue" SG_ 1391 TimeLeftToVehSpdReduction_OBD 511;
BA_ "Platform_VMCU1_Sig" SG_ 1391 TimeLeftToVehSpdReduction_OBD 1;
BA_ "GenSigCycleTime" SG_ 1391 OilPrediction_RemainDist 100;
BA_ "GenSigCycleTimeActive" SG_ 1391 OilPrediction_RemainDist 100;
BA_ "GenSigStartValue" SG_ 1391 OilPrediction_RemainDist 65535;
BA_ "Platform_VMCU1_Sig" SG_ 1391 OilPrediction_RemainDist 1;
BA_ "GenSigCycleTime" SG_ 1391 TimeToCorrectOilLevel_ISig_4 100;
BA_ "GenSigCycleTimeActive" SG_ 1391 TimeToCorrectOilLevel_ISig_4 100;
BA_ "GenSigStartValue" SG_ 1391 TimeToCorrectOilLevel_ISig_4 255;
BA_ "Platform_VMCU1_Sig" SG_ 1391 TimeToCorrectOilLevel_ISig_4 1;
BA_ "GenSigCycleTime" SG_ 1391 OilPrediction_RemainTime 100;
BA_ "GenSigCycleTimeActive" SG_ 1391 OilPrediction_RemainTime 100;
BA_ "GenSigStartValue" SG_ 1391 OilPrediction_RemainTime 65535;
BA_ "Platform_VMCU1_Sig" SG_ 1391 OilPrediction_RemainTime 1;
BA_ "GenSigCycleTime" SG_ 1391 OilPrediction_Status 100;
BA_ "GenSigCycleTimeActive" SG_ 1391 OilPrediction_Status 100;
BA_ "GenSigStartValue" SG_ 1391 OilPrediction_Status 7;
BA_ "Platform_VMCU1_Sig" SG_ 1391 OilPrediction_Status 1;
BA_ "GenSigCycleTime" SG_ 1276 EngineCoolingFanSpeed_ISig_4 100;
BA_ "GenSigCycleTimeActive" SG_ 1276 EngineCoolingFanSpeed_ISig_4 100;
BA_ "GenSigStartValue" SG_ 1276 EngineCoolingFanSpeed_ISig_4 65535;
BA_ "Platform_VMCU1_Sig" SG_ 1276 EngineCoolingFanSpeed_ISig_4 1;
BA_ "GenSigCycleTime" SG_ 1276 DMSDriverFollow 100;
BA_ "GenSigCycleTimeActive" SG_ 1276 DMSDriverFollow 100;
BA_ "GenSigStartValue" SG_ 1276 DMSDriverFollow 3;
BA_ "GenSigMaxLatency" SG_ 1276 DMSDriverFollow 270;
BA_ "Platform_VMCU1_Sig" SG_ 1276 DMSDriverFollow 1;
BA_ "GenSigCycleTime" SG_ 1276 DPF_ParkedRegenStatus 100;
BA_ "GenSigCycleTimeActive" SG_ 1276 DPF_ParkedRegenStatus 100;
BA_ "GenSigStartValue" SG_ 1276 DPF_ParkedRegenStatus 7;
BA_ "GenSigCycleTime" SG_ 1276 CoolantPumpEngagementStatus_ISig 100;
BA_ "GenSigCycleTimeActive" SG_ 1276 CoolantPumpEngagementStatus_ISig 100;
BA_ "GenSigStartValue" SG_ 1276 CoolantPumpEngagementStatus_ISig 255;
BA_ "Platform_VMCU1_Sig" SG_ 1276 CoolantPumpEngagementStatus_ISig 1;
BA_ "SystemSignalLongSymbol" SG_ 1276 CoolantPumpEngagementStatus_ISig "CoolantPumpEngagementStatus_ISig_4";
BA_ "GenSigCycleTime" SG_ 1276 AverageFuelEconomy_ISig_4 100;
BA_ "GenSigCycleTimeActive" SG_ 1276 AverageFuelEconomy_ISig_4 100;
BA_ "GenSigMaxLatency" SG_ 1276 AverageFuelEconomy_ISig_4 270;
BA_ "Platform_VMCU1_Sig" SG_ 1276 AverageFuelEconomy_ISig_4 1;
BA_ "GenSigCycleTime" SG_ 1276 EngineGasRate 100;
BA_ "GenSigCycleTimeActive" SG_ 1276 EngineGasRate 100;
BA_ "GenSigStartValue" SG_ 1276 EngineGasRate 65535;
BA_ "Platform_VMCU1_Sig" SG_ 1276 EngineGasRate 1;
BA_ "GenSigCycleTime" SG_ 1276 FuelEcoEngStatus 100;
BA_ "GenSigCycleTimeActive" SG_ 1276 FuelEcoEngStatus 100;
BA_ "GenSigStartValue" SG_ 1276 FuelEcoEngStatus 3;
BA_ "Platform_VMCU1_Sig" SG_ 1276 FuelEcoEngStatus 1;
BA_ "GenSigCycleTime" SG_ 1291 DrainPrimingStatus_ISig_4 100;
BA_ "GenSigCycleTimeActive" SG_ 1291 DrainPrimingStatus_ISig_4 100;
BA_ "GenSigStartValue" SG_ 1291 DrainPrimingStatus_ISig_4 7;
BA_ "GenSigMaxLatency" SG_ 1291 DrainPrimingStatus_ISig_4 258;
BA_ "Platform_VMCU1_Sig" SG_ 1291 DrainPrimingStatus_ISig_4 1;
BA_ "SeToolAncestorID_SIGNAL" SG_ 1291 DrainPrimingStatus_ISig_4 "x0000001D041410EE";
BA_ "SeToolItemID_SIGNAL" SG_ 1291 DrainPrimingStatus_ISig_4 "x0000001D042EB380";
BA_ "SeToolName_SIGNAL" SG_ 1291 DrainPrimingStatus_ISig_4 "DrainPrimingStatus";
BA_ "SeToolVersion_SIGNAL" SG_ 1291 DrainPrimingStatus_ISig_4 "2";
BA_ "GenSigCycleTime" SG_ 1291 CoolantTempHigh_ISig_4 100;
BA_ "GenSigCycleTimeActive" SG_ 1291 CoolantTempHigh_ISig_4 100;
BA_ "GenSigStartValue" SG_ 1291 CoolantTempHigh_ISig_4 7;
BA_ "GenSigMaxLatency" SG_ 1291 CoolantTempHigh_ISig_4 258;
BA_ "Platform_VMCU1_Sig" SG_ 1291 CoolantTempHigh_ISig_4 1;
BA_ "SeToolAncestorID_SIGNAL" SG_ 1291 CoolantTempHigh_ISig_4 "x0000001D0412B8A6";
BA_ "SeToolItemID_SIGNAL" SG_ 1291 CoolantTempHigh_ISig_4 "x0000001D0412B8A6";
BA_ "SeToolName_SIGNAL" SG_ 1291 CoolantTempHigh_ISig_4 "CoolantTempHigh";
BA_ "SeToolVersion_SIGNAL" SG_ 1291 CoolantTempHigh_ISig_4 "1";
BA_ "GenSigCycleTime" SG_ 1291 CoolantLevelLow_ISig_4 100;
BA_ "GenSigCycleTimeActive" SG_ 1291 CoolantLevelLow_ISig_4 100;
BA_ "GenSigStartValue" SG_ 1291 CoolantLevelLow_ISig_4 7;
BA_ "GenSigMaxLatency" SG_ 1291 CoolantLevelLow_ISig_4 258;
BA_ "Platform_VMCU1_Sig" SG_ 1291 CoolantLevelLow_ISig_4 1;
BA_ "SeToolAncestorID_SIGNAL" SG_ 1291 CoolantLevelLow_ISig_4 "x0000001D0412B8A4";
BA_ "SeToolItemID_SIGNAL" SG_ 1291 CoolantLevelLow_ISig_4 "x0000001D0412B8A4";
BA_ "SeToolName_SIGNAL" SG_ 1291 CoolantLevelLow_ISig_4 "CoolantLevelLow";
BA_ "SeToolVersion_SIGNAL" SG_ 1291 CoolantLevelLow_ISig_4 "1";
BA_ "GenSigCycleTime" SG_ 1291 AutoWheelBrakesStatus 100;
BA_ "GenSigCycleTimeActive" SG_ 1291 AutoWheelBrakesStatus 100;
BA_ "GenSigStartValue" SG_ 1291 AutoWheelBrakesStatus 7;
BA_ "GenSigCycleTime" SG_ 1291 OilPressureLow_ISig_4 100;
BA_ "GenSigCycleTimeActive" SG_ 1291 OilPressureLow_ISig_4 100;
BA_ "GenSigStartValue" SG_ 1291 OilPressureLow_ISig_4 7;
BA_ "GenSigMaxLatency" SG_ 1291 OilPressureLow_ISig_4 513;
BA_ "Platform_VMCU1_Sig" SG_ 1291 OilPressureLow_ISig_4 1;
BA_ "SeToolAncestorID_SIGNAL" SG_ 1291 OilPressureLow_ISig_4 "x0000001D0412B8B1";
BA_ "SeToolItemID_SIGNAL" SG_ 1291 OilPressureLow_ISig_4 "x0000001D0412B8B1";
BA_ "SeToolName_SIGNAL" SG_ 1291 OilPressureLow_ISig_4 "OilPressureLow";
BA_ "SeToolVersion_SIGNAL" SG_ 1291 OilPressureLow_ISig_4 "1";
BA_ "GenSigCycleTime" SG_ 1291 EngineTotalFuelConsumed_ISig_4 100;
BA_ "GenSigCycleTimeActive" SG_ 1291 EngineTotalFuelConsumed_ISig_4 100;
BA_ "GenSigStartValue" SG_ 1291 EngineTotalFuelConsumed_ISig_4 4294967295;
BA_ "GenSigMaxLatency" SG_ 1291 EngineTotalFuelConsumed_ISig_4 258;
BA_ "Platform_VMCU1_Sig" SG_ 1291 EngineTotalFuelConsumed_ISig_4 1;
BA_ "SeToolAncestorID_SIGNAL" SG_ 1291 EngineTotalFuelConsumed_ISig_4 "x0000001D04172521";
BA_ "SeToolItemID_SIGNAL" SG_ 1291 EngineTotalFuelConsumed_ISig_4 "x0000001D04172521";
BA_ "SeToolName_SIGNAL" SG_ 1291 EngineTotalFuelConsumed_ISig_4 "EngineTotalFuelConsumed";
BA_ "SeToolVersion_SIGNAL" SG_ 1291 EngineTotalFuelConsumed_ISig_4 "1";
BA_ "GenSigCycleTime" SG_ 1291 TopGearMode_ISig_4 100;
BA_ "GenSigCycleTimeActive" SG_ 1291 TopGearMode_ISig_4 100;
BA_ "GenSigStartValue" SG_ 1291 TopGearMode_ISig_4 3;
BA_ "Platform_VMCU1_Sig" SG_ 1291 TopGearMode_ISig_4 1;
BA_ "GenSigCycleTime" SG_ 1291 OilLevelLow_ISig_4 100;
BA_ "GenSigCycleTimeActive" SG_ 1291 OilLevelLow_ISig_4 100;
BA_ "GenSigStartValue" SG_ 1291 OilLevelLow_ISig_4 7;
BA_ "GenSigMaxLatency" SG_ 1291 OilLevelLow_ISig_4 513;
BA_ "Platform_VMCU1_Sig" SG_ 1291 OilLevelLow_ISig_4 1;
BA_ "SeToolAncestorID_SIGNAL" SG_ 1291 OilLevelLow_ISig_4 "x0000001D0412B8AA";
BA_ "SeToolItemID_SIGNAL" SG_ 1291 OilLevelLow_ISig_4 "x0000001D0412B8AA";
BA_ "SeToolName_SIGNAL" SG_ 1291 OilLevelLow_ISig_4 "OilLevelLow";
BA_ "SeToolVersion_SIGNAL" SG_ 1291 OilLevelLow_ISig_4 "1";
BA_ "GenSigCycleTime" SG_ 1291 BarometricPressure_ISig_4 100;
BA_ "GenSigCycleTimeActive" SG_ 1291 BarometricPressure_ISig_4 100;
BA_ "GenSigStartValue" SG_ 1291 BarometricPressure_ISig_4 255;
BA_ "GenSigMaxLatency" SG_ 1291 BarometricPressure_ISig_4 258;
BA_ "Platform_VMCU1_Sig" SG_ 1291 BarometricPressure_ISig_4 1;
BA_ "SeToolAncestorID_SIGNAL" SG_ 1291 BarometricPressure_ISig_4 "x0000001D040FEBBD";
BA_ "SeToolItemID_SIGNAL" SG_ 1291 BarometricPressure_ISig_4 "x0000001D040FEBBD";
BA_ "SeToolName_SIGNAL" SG_ 1291 BarometricPressure_ISig_4 "BarometricPressure";
BA_ "SeToolVersion_SIGNAL" SG_ 1291 BarometricPressure_ISig_4 "1";
BA_ "GenSigCycleTime" SG_ 1291 InletAirHeaterStatus1 100;
BA_ "GenSigCycleTimeActive" SG_ 1291 InletAirHeaterStatus1 100;
BA_ "GenSigStartValue" SG_ 1291 InletAirHeaterStatus1 3;
BA_ "GenSigMaxLatency" SG_ 1291 InletAirHeaterStatus1 258;
BA_ "Platform_VMCU1_Sig" SG_ 1291 InletAirHeaterStatus1 1;
BA_ "SeToolAncestorID_SIGNAL" SG_ 1291 InletAirHeaterStatus1 "x0000001D04130F0B";
BA_ "SeToolItemID_SIGNAL" SG_ 1291 InletAirHeaterStatus1 "x0000001D043210A4";
BA_ "SeToolName_SIGNAL" SG_ 1291 InletAirHeaterStatus1 "InletAirHeaterStatus1";
BA_ "SeToolVersion_SIGNAL" SG_ 1291 InletAirHeaterStatus1 "2";
BA_ "GenSigCycleTime" SG_ 1279 FuelFilterClogged 100;
BA_ "GenSigCycleTimeActive" SG_ 1279 FuelFilterClogged 100;
BA_ "GenSigStartValue" SG_ 1279 FuelFilterClogged 7;
BA_ "GenSigMaxLatency" SG_ 1279 FuelFilterClogged 257;
BA_ "Platform_VMCU1_Sig" SG_ 1279 FuelFilterClogged 1;
BA_ "SeToolAncestorID_SIGNAL" SG_ 1279 FuelFilterClogged "x0000001D04181612";
BA_ "SeToolItemID_SIGNAL" SG_ 1279 FuelFilterClogged "x0000001D04181612";
BA_ "SeToolName_SIGNAL" SG_ 1279 FuelFilterClogged "FuelFilterClogged";
BA_ "SeToolVersion_SIGNAL" SG_ 1279 FuelFilterClogged "1";
BA_ "GenSigCycleTime" SG_ 1279 EngineAirInletTemperature 100;
BA_ "GenSigCycleTimeActive" SG_ 1279 EngineAirInletTemperature 100;
BA_ "GenSigStartValue" SG_ 1279 EngineAirInletTemperature 255;
BA_ "GenSigMaxLatency" SG_ 1279 EngineAirInletTemperature 257;
BA_ "Platform_VMCU1_Sig" SG_ 1279 EngineAirInletTemperature 1;
BA_ "SeToolAncestorID_SIGNAL" SG_ 1279 EngineAirInletTemperature "x0000001D041943AE";
BA_ "SeToolItemID_SIGNAL" SG_ 1279 EngineAirInletTemperature "x0000001D0421DC80";
BA_ "SeToolName_SIGNAL" SG_ 1279 EngineAirInletTemperature "EngineAirInletTemperature";
BA_ "SeToolVersion_SIGNAL" SG_ 1279 EngineAirInletTemperature "2";
BA_ "GenSigCycleTime" SG_ 1279 StarterMotorRecoveryTime 100;
BA_ "GenSigCycleTimeActive" SG_ 1279 StarterMotorRecoveryTime 100;
BA_ "GenSigStartValue" SG_ 1279 StarterMotorRecoveryTime 65535;
BA_ "GenSigMaxLatency" SG_ 1279 StarterMotorRecoveryTime 257;
BA_ "Platform_VMCU1_Sig" SG_ 1279 StarterMotorRecoveryTime 1;
BA_ "SeToolAncestorID_SIGNAL" SG_ 1279 StarterMotorRecoveryTime "x0000001D0421E90A";
BA_ "SeToolItemID_SIGNAL" SG_ 1279 StarterMotorRecoveryTime "x0000001D0421E90A";
BA_ "SeToolName_SIGNAL" SG_ 1279 StarterMotorRecoveryTime "StarterMotorRecoveryTime";
BA_ "SeToolVersion_SIGNAL" SG_ 1279 StarterMotorRecoveryTime "1";
BA_ "GenSigCycleTime" SG_ 1279 EngineFanOverspeed 100;
BA_ "GenSigCycleTimeActive" SG_ 1279 EngineFanOverspeed 100;
BA_ "GenSigStartValue" SG_ 1279 EngineFanOverspeed 3;
BA_ "GenSigCycleTime" SG_ 1279 AppliedVehicleSpeedLimit 100;
BA_ "GenSigCycleTimeActive" SG_ 1279 AppliedVehicleSpeedLimit 100;
BA_ "GenSigStartValue" SG_ 1279 AppliedVehicleSpeedLimit 65535;
BA_ "Platform_VMCU1_Sig" SG_ 1279 AppliedVehicleSpeedLimit 1;
BA_ "GenSigCycleTime" SG_ 1279 EngineProtDerateStat 100;
BA_ "GenSigCycleTimeActive" SG_ 1279 EngineProtDerateStat 100;
BA_ "GenSigStartValue" SG_ 1279 EngineProtDerateStat 3;
BA_ "Platform_VMCU1_Sig" SG_ 1279 EngineProtDerateStat 1;
BA_ "GenSigCycleTime" SG_ 1279 CoolantTempGaugeAdjustment 100;
BA_ "GenSigCycleTimeActive" SG_ 1279 CoolantTempGaugeAdjustment 100;
BA_ "GenSigStartValue" SG_ 1279 CoolantTempGaugeAdjustment 255;
BA_ "Platform_VMCU1_Sig" SG_ 1279 CoolantTempGaugeAdjustment 1;
BA_ "GenSigCycleTime" SG_ 1279 AirFilterPressureDrop 100;
BA_ "GenSigCycleTimeActive" SG_ 1279 AirFilterPressureDrop 100;
BA_ "GenSigStartValue" SG_ 1279 AirFilterPressureDrop 7;
BA_ "GenSigCycleTime" SG_ 733 AirFilter_AirMassFlowValidated 100;
BA_ "GenSigCycleTimeActive" SG_ 733 AirFilter_AirMassFlowValidated 100;
BA_ "GenSigStartValue" SG_ 733 AirFilter_AirMassFlowValidated 255;
BA_ "GenSigCycleTime" SG_ 733 DPF_LimitedSpeedDuetoInhibit 100;
BA_ "GenSigCycleTimeActive" SG_ 733 DPF_LimitedSpeedDuetoInhibit 100;
BA_ "GenSigStartValue" SG_ 733 DPF_LimitedSpeedDuetoInhibit 7;
BA_ "Platform_VMCU1_Sig" SG_ 733 DPF_LimitedSpeedDuetoInhibit 1;
BA_ "GenSigCycleTime" SG_ 733 XARSystemState 100;
BA_ "GenSigCycleTimeActive" SG_ 733 XARSystemState 100;
BA_ "GenSigStartValue" SG_ 733 XARSystemState 3;
BA_ "GenSigMaxLatency" SG_ 733 XARSystemState 58;
BA_ "Platform_VMCU1_Sig" SG_ 733 XARSystemState 1;
BA_ "SeToolAncestorID_SIGNAL" SG_ 733 XARSystemState "x0000001D0425407E";
BA_ "SeToolItemID_SIGNAL" SG_ 733 XARSystemState "x0000001D0425407E";
BA_ "SeToolName_SIGNAL" SG_ 733 XARSystemState "XARSystemState";
BA_ "SeToolVersion_SIGNAL" SG_ 733 XARSystemState "1";
BA_ "GenSigCycleTime" SG_ 733 XARActiveControlMode 100;
BA_ "GenSigCycleTimeActive" SG_ 733 XARActiveControlMode 100;
BA_ "GenSigStartValue" SG_ 733 XARActiveControlMode 7;
BA_ "GenSigMaxLatency" SG_ 733 XARActiveControlMode 58;
BA_ "Platform_VMCU1_Sig" SG_ 733 XARActiveControlMode 1;
BA_ "SeToolAncestorID_SIGNAL" SG_ 733 XARActiveControlMode "x0000001D04254078";
BA_ "SeToolItemID_SIGNAL" SG_ 733 XARActiveControlMode "x0000001D043C593D";
BA_ "SeToolName_SIGNAL" SG_ 733 XARActiveControlMode "XARActiveControlMode";
BA_ "SeToolVersion_SIGNAL" SG_ 733 XARActiveControlMode "2";
BA_ "GenSigCycleTime" SG_ 733 AirFilter_Pressure 100;
BA_ "GenSigCycleTimeActive" SG_ 733 AirFilter_Pressure 100;
BA_ "GenSigStartValue" SG_ 733 AirFilter_Pressure 2047;
BA_ "GenSigCycleTime" SG_ 733 CCBSetSpeedApplied 100;
BA_ "GenSigCycleTimeActive" SG_ 733 CCBSetSpeedApplied 100;
BA_ "GenSigStartValue" SG_ 733 CCBSetSpeedApplied 255;
BA_ "Platform_VMCU1_Sig" SG_ 733 CCBSetSpeedApplied 1;
BA_ "GenSigCycleTime" SG_ 719 CCControllerMode_ISig_4 100;
BA_ "GenSigCycleTimeActive" SG_ 719 CCControllerMode_ISig_4 100;
BA_ "GenSigStartValue" SG_ 719 CCControllerMode_ISig_4 7;
BA_ "GenSigMaxLatency" SG_ 719 CCControllerMode_ISig_4 55;
BA_ "Platform_VMCU1_Sig" SG_ 719 CCControllerMode_ISig_4 1;
BA_ "SeToolAncestorID_SIGNAL" SG_ 719 CCControllerMode_ISig_4 "x0000001D0422FAAD";
BA_ "SeToolItemID_SIGNAL" SG_ 719 CCControllerMode_ISig_4 "x0000001D043FE012";
BA_ "SeToolName_SIGNAL" SG_ 719 CCControllerMode_ISig_4 "CCControllerMode";
BA_ "SeToolVersion_SIGNAL" SG_ 719 CCControllerMode_ISig_4 "3";
BA_ "GenSigCycleTime" SG_ 719 CrankcasePressureHigh_ISig_4 100;
BA_ "GenSigCycleTimeActive" SG_ 719 CrankcasePressureHigh_ISig_4 100;
BA_ "GenSigStartValue" SG_ 719 CrankcasePressureHigh_ISig_4 3;
BA_ "Platform_VMCU1_Sig" SG_ 719 CrankcasePressureHigh_ISig_4 1;
BA_ "GenSigCycleTime" SG_ 719 EngineSystemPowerDownAck 100;
BA_ "GenSigCycleTimeActive" SG_ 719 EngineSystemPowerDownAck 100;
BA_ "GenSigStartValue" SG_ 719 EngineSystemPowerDownAck 3;
BA_ "GenSigMaxLatency" SG_ 719 EngineSystemPowerDownAck 55;
BA_ "Platform_FactoryIf_Sig" SG_ 719 EngineSystemPowerDownAck 1;
BA_ "Platform_VMCU1_Sig" SG_ 719 EngineSystemPowerDownAck 1;
BA_ "SeToolAncestorID_SIGNAL" SG_ 719 EngineSystemPowerDownAck "x0000001D0436C68E";
BA_ "SeToolItemID_SIGNAL" SG_ 719 EngineSystemPowerDownAck "x0000001D0436C68E";
BA_ "SeToolName_SIGNAL" SG_ 719 EngineSystemPowerDownAck "EngineSystemPowerDownAck";
BA_ "SeToolVersion_SIGNAL" SG_ 719 EngineSystemPowerDownAck "1";
BA_ "GenSigCycleTime" SG_ 719 EngineActiveStatus_ISig_4 100;
BA_ "GenSigCycleTimeActive" SG_ 719 EngineActiveStatus_ISig_4 100;
BA_ "GenSigStartValue" SG_ 719 EngineActiveStatus_ISig_4 15;
BA_ "GenSigMaxLatency" SG_ 719 EngineActiveStatus_ISig_4 55;
BA_ "Platform_FactoryIf_Sig" SG_ 719 EngineActiveStatus_ISig_4 1;
BA_ "Platform_VMCU1_Sig" SG_ 719 EngineActiveStatus_ISig_4 1;
BA_ "SeToolAncestorID_SIGNAL" SG_ 719 EngineActiveStatus_ISig_4 "x0000001D0421DFD5";
BA_ "SeToolItemID_SIGNAL" SG_ 719 EngineActiveStatus_ISig_4 "x0000001D0421DFD5";
BA_ "SeToolName_SIGNAL" SG_ 719 EngineActiveStatus_ISig_4 "EngineActiveStatus";
BA_ "SeToolVersion_SIGNAL" SG_ 719 EngineActiveStatus_ISig_4 "1";
BA_ "GenSigCycleTime" SG_ 719 XRSLControllerMode 100;
BA_ "GenSigCycleTimeActive" SG_ 719 XRSLControllerMode 100;
BA_ "GenSigStartValue" SG_ 719 XRSLControllerMode 3;
BA_ "Platform_VMCU1_Sig" SG_ 719 XRSLControllerMode 1;
BA_ "GenSigCycleTime" SG_ 719 RegenInhibDueHeight 100;
BA_ "GenSigCycleTimeActive" SG_ 719 RegenInhibDueHeight 100;
BA_ "GenSigStartValue" SG_ 719 RegenInhibDueHeight 3;
BA_ "Platform_VMCU1_Sig" SG_ 719 RegenInhibDueHeight 1;
BA_ "GenSigCycleTime" SG_ 719 ExhManif_AirInjActive_ISig_4 100;
BA_ "GenSigCycleTimeActive" SG_ 719 ExhManif_AirInjActive_ISig_4 100;
BA_ "GenSigStartValue" SG_ 719 ExhManif_AirInjActive_ISig_4 3;
BA_ "GenSigCycleTime" SG_ 719 CCBControllerMode 100;
BA_ "GenSigCycleTimeActive" SG_ 719 CCBControllerMode 100;
BA_ "GenSigStartValue" SG_ 719 CCBControllerMode 7;
BA_ "GenSigMaxLatency" SG_ 719 CCBControllerMode 55;
BA_ "Platform_VMCU1_Sig" SG_ 719 CCBControllerMode 1;
BA_ "SeToolAncestorID_SIGNAL" SG_ 719 CCBControllerMode "x0000001D043FE01A";
BA_ "SeToolItemID_SIGNAL" SG_ 719 CCBControllerMode "x0000001D043FE01A";
BA_ "SeToolName_SIGNAL" SG_ 719 CCBControllerMode "CCBControllerMode";
BA_ "SeToolVersion_SIGNAL" SG_ 719 CCBControllerMode "1";
BA_ "GenSigCycleTime" SG_ 719 InhibitIdleShutdownStatus 100;
BA_ "GenSigCycleTimeActive" SG_ 719 InhibitIdleShutdownStatus 100;
BA_ "GenSigStartValue" SG_ 719 InhibitIdleShutdownStatus 7;
BA_ "GenSigMaxLatency" SG_ 719 InhibitIdleShutdownStatus 55;
BA_ "Platform_VMCU1_Sig" SG_ 719 InhibitIdleShutdownStatus 1;
BA_ "SeToolAncestorID_SIGNAL" SG_ 719 InhibitIdleShutdownStatus "x0000001D041620E7";
BA_ "SeToolItemID_SIGNAL" SG_ 719 InhibitIdleShutdownStatus "x0000001D043C6713";
BA_ "SeToolName_SIGNAL" SG_ 719 InhibitIdleShutdownStatus "InhibitIdleShutdownStatus";
BA_ "SeToolVersion_SIGNAL" SG_ 719 InhibitIdleShutdownStatus "2";
BA_ "GenSigCycleTime" SG_ 719 EngCompartmentStopSwitchStat 100;
BA_ "GenSigCycleTimeActive" SG_ 719 EngCompartmentStopSwitchStat 100;
BA_ "GenSigStartValue" SG_ 719 EngCompartmentStopSwitchStat 3;
BA_ "GenSigMaxLatency" SG_ 719 EngCompartmentStopSwitchStat 55;
BA_ "Platform_VMCU1_Sig" SG_ 719 EngCompartmentStopSwitchStat 1;
BA_ "SeToolAncestorID_SIGNAL" SG_ 719 EngCompartmentStopSwitchStat "x0000001D041308F3";
BA_ "SeToolItemID_SIGNAL" SG_ 719 EngCompartmentStopSwitchStat "x0000001D0428D42A";
BA_ "SeToolName_SIGNAL" SG_ 719 EngCompartmentStopSwitchStat "EngCompartmentStopSwitchStat";
BA_ "SeToolVersion_SIGNAL" SG_ 719 EngCompartmentStopSwitchStat "2";
BA_ "GenSigCycleTime" SG_ 719 EngineAirInletPressure 100;
BA_ "GenSigCycleTimeActive" SG_ 719 EngineAirInletPressure 100;
BA_ "GenSigStartValue" SG_ 719 EngineAirInletPressure 255;
BA_ "Platform_VMCU1_Sig" SG_ 719 EngineAirInletPressure 1;
BA_ "GenSigCycleTime" SG_ 719 EngineStartAuth_rqst 100;
BA_ "GenSigCycleTimeActive" SG_ 719 EngineStartAuth_rqst 100;
BA_ "GenSigStartValue" SG_ 719 EngineStartAuth_rqst 7;
BA_ "Platform_VMCU1_Sig" SG_ 719 EngineStartAuth_rqst 1;
BA_ "GenSigCycleTime" SG_ 719 IntakeAirTemperatureAlert 100;
BA_ "GenSigCycleTimeActive" SG_ 719 IntakeAirTemperatureAlert 100;
BA_ "GenSigStartValue" SG_ 719 IntakeAirTemperatureAlert 3;
BA_ "Platform_VMCU1_Sig" SG_ 719 IntakeAirTemperatureAlert 1;
BA_ "GenSigCycleTime" SG_ 719 EngineOilTempHigh_ISig_4 100;
BA_ "GenSigCycleTimeActive" SG_ 719 EngineOilTempHigh_ISig_4 100;
BA_ "GenSigStartValue" SG_ 719 EngineOilTempHigh_ISig_4 7;
BA_ "Platform_VMCU1_Sig" SG_ 719 EngineOilTempHigh_ISig_4 1;
BA_ "GenSigCycleTime" SG_ 719 WarmUpCycle 100;
BA_ "GenSigCycleTimeActive" SG_ 719 WarmUpCycle 100;
BA_ "GenSigStartValue" SG_ 719 WarmUpCycle 3;
BA_ "Platform_VMCU1_Sig" SG_ 719 WarmUpCycle 1;
BA_ "GenSigCycleTime" SG_ 719 DeterminedGear 100;
BA_ "GenSigCycleTimeActive" SG_ 719 DeterminedGear 100;
BA_ "GenSigStartValue" SG_ 719 DeterminedGear 255;
BA_ "Platform_VMCU1_Sig" SG_ 719 DeterminedGear 1;
BA_ "GenSigCycleTime" SG_ 719 CCSetSpeedApplied_ISig_4 100;
BA_ "GenSigCycleTimeActive" SG_ 719 CCSetSpeedApplied_ISig_4 100;
BA_ "GenSigStartValue" SG_ 719 CCSetSpeedApplied_ISig_4 255;
BA_ "GenSigMaxLatency" SG_ 719 CCSetSpeedApplied_ISig_4 55;
BA_ "Platform_VMCU1_Sig" SG_ 719 CCSetSpeedApplied_ISig_4 1;
BA_ "SeToolAncestorID_SIGNAL" SG_ 719 CCSetSpeedApplied_ISig_4 "x0000001D04352A03";
BA_ "SeToolItemID_SIGNAL" SG_ 719 CCSetSpeedApplied_ISig_4 "x0000001D04352A03";
BA_ "SeToolName_SIGNAL" SG_ 719 CCSetSpeedApplied_ISig_4 "CCSetSpeedApplied";
BA_ "SeToolVersion_SIGNAL" SG_ 719 CCSetSpeedApplied_ISig_4 "1";
BA_ "GenSigSendType" SG_ 2671964911 DiagUUDTRespSig_F2_EF_ISig_4 7;
BA_ "GenSigSendType" SG_ 2671964902 DiagUUDTRespSig_F2_E6_ISig_4 7;
BA_ "Platform_VMCU1_Sig" SG_ 2671964902 DiagUUDTRespSig_F2_E6_ISig_4 1;
BA_ "GenSigSendType" SG_ 2671964901 DiagUUDTRespSig_F2_E5_ISig_4 7;
BA_ "GenSigSendType" SG_ 2671964866 DiagUUDTRespSig_F2_C2_ISig_4 7;
BA_ "GenSigSendType" SG_ 2671964864 DiagUUDTRespSig_F2_C0_ISig_4 7;
BA_ "Platform_VMCU1_Sig" SG_ 2671964864 DiagUUDTRespSig_F2_C0_ISig_4 1;
BA_ "GenSigSendType" SG_ 2671964834 DiagUUDTRespSig_F2_A2_ISig_4 7;
BA_ "Platform_VMCU1_Sig" SG_ 2671964834 DiagUUDTRespSig_F2_A2_ISig_4 1;
BA_ "GenSigSendType" SG_ 2671964833 DiagUUDTRespSig_F2_A1_ISig_4 7;
BA_ "Platform_VMCU1_Sig" SG_ 2671964833 DiagUUDTRespSig_F2_A1_ISig_4 1;
BA_ "GenSigSendType" SG_ 2671964832 DiagUUDTRespSig_F2_A0_ISig_4 7;
BA_ "Platform_VMCU1_Sig" SG_ 2671964832 DiagUUDTRespSig_F2_A0_ISig_4 1;
BA_ "GenSigSendType" SG_ 2671964824 DiagUUDTRespSig_F2_98_ISig_4 7;
BA_ "Platform_VMCU1_Sig" SG_ 2671964824 DiagUUDTRespSig_F2_98_ISig_4 1;
BA_ "GenSigSendType" SG_ 2671964812 DiagUUDTRespSig_F2_8C_ISig_4 7;
BA_ "GenSigSendType" SG_ 2671964803 DiagUUDTRespSig_F2_83_ISig_4 7;
BA_ "GenSigSendType" SG_ 2671964802 DiagUUDTRespSig_F2_82_ISig_4 7;
BA_ "Platform_VMCU1_Sig" SG_ 2671964802 DiagUUDTRespSig_F2_82_ISig_4 1;
BA_ "GenSigSendType" SG_ 2671964772 DiagUUDTRespSig_F2_64_ISig_4 7;
BA_ "GenSigSendType" SG_ 2671964769 DiagUUDTRespSig_F2_61_ISig_4 7;
BA_ "Platform_VMCU1_Sig" SG_ 2671964769 DiagUUDTRespSig_F2_61_ISig_4 1;
BA_ "GenSigSendType" SG_ 2671964768 DiagUUDTRespSig_F2_60_ISig_4 7;
BA_ "Platform_VMCU1_Sig" SG_ 2671964768 DiagUUDTRespSig_F2_60_ISig_4 1;
BA_ "GenSigSendType" SG_ 2671964755 DiagUUDTRespSig_F2_53_ISig_4 7;
BA_ "Platform_VMCU1_Sig" SG_ 2671964755 DiagUUDTRespSig_F2_53_ISig_4 1;
BA_ "GenSigSendType" SG_ 2671964754 DiagUUDTRespSig_F2_52_ISig_4 7;
BA_ "Platform_VMCU1_Sig" SG_ 2671964754 DiagUUDTRespSig_F2_52_ISig_4 1;
BA_ "GenSigSendType" SG_ 2671964753 DiagUUDTRespSig_F2_51_ISig_4 7;
BA_ "Platform_VMCU1_Sig" SG_ 2671964753 DiagUUDTRespSig_F2_51_ISig_4 1;
BA_ "GenSigSendType" SG_ 2671964752 DiagUUDTRespSig_F2_50_ISig_4 7;
BA_ "Platform_VMCU1_Sig" SG_ 2671964752 DiagUUDTRespSig_F2_50_ISig_4 1;
BA_ "GenSigSendType" SG_ 2671964737 DiagUUDTRespSig_F2_41_ISig_4 7;
BA_ "Platform_VMCU1_Sig" SG_ 2671964737 DiagUUDTRespSig_F2_41_ISig_4 1;
BA_ "GenSigSendType" SG_ 2671964736 DiagUUDTRespSig_F2_40_ISig_4 7;
BA_ "Platform_VMCU1_Sig" SG_ 2671964736 DiagUUDTRespSig_F2_40_ISig_4 1;
BA_ "GenSigSendType" SG_ 2671964710 DiagUUDTRespSig_F2_26_ISig_4 7;
BA_ "Platform_VMCU1_Sig" SG_ 2671964710 DiagUUDTRespSig_F2_26_ISig_4 1;
BA_ "GenSigSendType" SG_ 2671964696 DiagUUDTRespSig_F2_18_ISig_4 7;
BA_ "Platform_VMCU1_Sig" SG_ 2671964696 DiagUUDTRespSig_F2_18_ISig_4 1;
BA_ "GenSigSendType" SG_ 2671964688 DiagUUDTRespSig_F2_10_ISig_4 7;
BA_ "Platform_VMCU1_Sig" SG_ 2671964688 DiagUUDTRespSig_F2_10_ISig_4 1;
BA_ "GenSigSendType" SG_ 2671834277 InternalTesterDiagSig_F4_A5_ISig 7;
BA_ "SystemSignalLongSymbol" SG_ 2671834277 InternalTesterDiagSig_F4_A5_ISig "InternalTesterDiagSig_F4_A5_ISig_4";
BA_ "GenSigSendType" SG_ 2671834227 InternalTesterDiagSig_F4_73_ISig 7;
BA_ "SystemSignalLongSymbol" SG_ 2671834227 InternalTesterDiagSig_F4_73_ISig "InternalTesterDiagSig_F4_73_ISig_4";
BA_ "GenSigSendType" SG_ 2671834213 InternalTesterDiagSig_F4_65_ISig 7;
BA_ "SystemSignalLongSymbol" SG_ 2671834213 InternalTesterDiagSig_F4_65_ISig "InternalTesterDiagSig_F4_65_ISig_4";
BA_ "GenSigSendType" SG_ 2671834168 InternalTesterDiagSig_F4_38_ISig 7;
BA_ "SystemSignalLongSymbol" SG_ 2671834168 InternalTesterDiagSig_F4_38_ISig "InternalTesterDiagSig_F4_38_ISig_4";
BA_ "GenSigSendType" SG_ 2671834351 InternalTesterDiagSig_F4_EF_ISig 7;
BA_ "SystemSignalLongSymbol" SG_ 2671834351 InternalTesterDiagSig_F4_EF_ISig "InternalTesterDiagSig_F4_EF_ISig_4";
BA_ "GenSigSendType" SG_ 2671834342 InternalTesterDiagSig_F4_E6_ISig 7;
BA_ "Platform_VMCU1_Sig" SG_ 2671834342 InternalTesterDiagSig_F4_E6_ISig 1;
BA_ "SystemSignalLongSymbol" SG_ 2671834342 InternalTesterDiagSig_F4_E6_ISig "InternalTesterDiagSig_F4_E6_ISig_4";
BA_ "GenSigSendType" SG_ 2671834341 InternalTesterDiagSig_F4_E5_ISig 7;
BA_ "SystemSignalLongSymbol" SG_ 2671834341 InternalTesterDiagSig_F4_E5_ISig "InternalTesterDiagSig_F4_E5_ISig_4";
BA_ "GenSigSendType" SG_ 2671834306 InternalTesterDiagSig_F4_C2_ISig 7;
BA_ "GenSigCycleTimeActive" SG_ 2671834306 InternalTesterDiagSig_F4_C2_ISig 100;
BA_ "SystemSignalLongSymbol" SG_ 2671834306 InternalTesterDiagSig_F4_C2_ISig "InternalTesterDiagSig_F4_C2_ISig_4";
BA_ "GenSigSendType" SG_ 2671834304 InternalTesterDiagSig_F4_C0_ISig 7;
BA_ "Platform_VMCU1_Sig" SG_ 2671834304 InternalTesterDiagSig_F4_C0_ISig 1;
BA_ "SystemSignalLongSymbol" SG_ 2671834304 InternalTesterDiagSig_F4_C0_ISig "InternalTesterDiagSig_F4_C0_ISig_4";
BA_ "GenSigSendType" SG_ 2671834274 InternalTesterDiagSig_F4_A2_ISig 7;
BA_ "Platform_VMCU1_Sig" SG_ 2671834274 InternalTesterDiagSig_F4_A2_ISig 1;
BA_ "SystemSignalLongSymbol" SG_ 2671834274 InternalTesterDiagSig_F4_A2_ISig "InternalTesterDiagSig_F4_A2_ISig_4";
BA_ "GenSigSendType" SG_ 2671834273 InternalTesterDiagSig_F4_A1_ISig 7;
BA_ "Platform_VMCU1_Sig" SG_ 2671834273 InternalTesterDiagSig_F4_A1_ISig 1;
BA_ "SystemSignalLongSymbol" SG_ 2671834273 InternalTesterDiagSig_F4_A1_ISig "InternalTesterDiagSig_F4_A1_ISig_4";
BA_ "GenSigSendType" SG_ 2671834272 InternalTesterDiagSig_F4_A0_ISig 7;
BA_ "Platform_VMCU1_Sig" SG_ 2671834272 InternalTesterDiagSig_F4_A0_ISig 1;
BA_ "SystemSignalLongSymbol" SG_ 2671834272 InternalTesterDiagSig_F4_A0_ISig "InternalTesterDiagSig_F4_A0_ISig_4";
BA_ "GenSigSendType" SG_ 2671834264 InternalTesterDiagSig_F4_98_ISig 7;
BA_ "Platform_VMCU1_Sig" SG_ 2671834264 InternalTesterDiagSig_F4_98_ISig 1;
BA_ "SystemSignalLongSymbol" SG_ 2671834264 InternalTesterDiagSig_F4_98_ISig "InternalTesterDiagSig_F4_98_ISig_4";
BA_ "GenSigSendType" SG_ 2671834252 InternalTesterDiagSig_F4_8C_ISig 7;
BA_ "SystemSignalLongSymbol" SG_ 2671834252 InternalTesterDiagSig_F4_8C_ISig "InternalTesterDiagSig_F4_8C_ISig_4";
BA_ "GenSigSendType" SG_ 2671834226 InternalTesterDiagSig_F4_72_ISig 7;
BA_ "SystemSignalLongSymbol" SG_ 2671834226 InternalTesterDiagSig_F4_72_ISig "InternalTesterDiagSig_F4_72_ISig_4";
BA_ "GenSigSendType" SG_ 2671834225 InternalTesterDiagSig_F4_71_ISig 7;
BA_ "SystemSignalLongSymbol" SG_ 2671834225 InternalTesterDiagSig_F4_71_ISig "InternalTesterDiagSig_F4_71_ISig_4";
BA_ "GenSigSendType" SG_ 2671834195 InternalTesterDiagSig_F4_53_ISig 7;
BA_ "Platform_VMCU1_Sig" SG_ 2671834195 InternalTesterDiagSig_F4_53_ISig 1;
BA_ "SystemSignalLongSymbol" SG_ 2671834195 InternalTesterDiagSig_F4_53_ISig "InternalTesterDiagSig_F4_53_ISig_4";
BA_ "GenSigSendType" SG_ 2671834194 InternalTesterDiagSig_F4_52_ISig 7;
BA_ "Platform_VMCU1_Sig" SG_ 2671834194 InternalTesterDiagSig_F4_52_ISig 1;
BA_ "SystemSignalLongSymbol" SG_ 2671834194 InternalTesterDiagSig_F4_52_ISig "InternalTesterDiagSig_F4_52_ISig_4";
BA_ "GenSigSendType" SG_ 2671834193 InternalTesterDiagSig_F4_51_ISig 7;
BA_ "Platform_VMCU1_Sig" SG_ 2671834193 InternalTesterDiagSig_F4_51_ISig 1;
BA_ "SystemSignalLongSymbol" SG_ 2671834193 InternalTesterDiagSig_F4_51_ISig "InternalTesterDiagSig_F4_51_ISig_4";
BA_ "GenSigSendType" SG_ 2671834192 InternalTesterDiagSig_F4_50_ISig 7;
BA_ "Platform_VMCU1_Sig" SG_ 2671834192 InternalTesterDiagSig_F4_50_ISig 1;
BA_ "SystemSignalLongSymbol" SG_ 2671834192 InternalTesterDiagSig_F4_50_ISig "InternalTesterDiagSig_F4_50_ISig_4";
BA_ "GenSigSendType" SG_ 2671834176 InternalTesterDiagSig_F4_40_ISig 7;
BA_ "Platform_VMCU1_Sig" SG_ 2671834176 InternalTesterDiagSig_F4_40_ISig 1;
BA_ "SystemSignalLongSymbol" SG_ 2671834176 InternalTesterDiagSig_F4_40_ISig "InternalTesterDiagSig_F4_40_ISig_4";
BA_ "GenSigSendType" SG_ 2671834161 InternalTesterDiagSig_F4_31_ISig 7;
BA_ "Platform_VMCU1_Sig" SG_ 2671834161 InternalTesterDiagSig_F4_31_ISig 1;
BA_ "SystemSignalLongSymbol" SG_ 2671834161 InternalTesterDiagSig_F4_31_ISig "InternalTesterDiagSig_F4_31_ISig_4";
BA_ "GenSigSendType" SG_ 2671834160 InternalTesterDiagSig_F4_30_ISig 7;
BA_ "Platform_VMCU1_Sig" SG_ 2671834160 InternalTesterDiagSig_F4_30_ISig 1;
BA_ "SystemSignalLongSymbol" SG_ 2671834160 InternalTesterDiagSig_F4_30_ISig "InternalTesterDiagSig_F4_30_ISig_4";
BA_ "GenSigSendType" SG_ 2671834150 InternalTesterDiagSig_F4_26_ISig 7;
BA_ "Platform_VMCU1_Sig" SG_ 2671834150 InternalTesterDiagSig_F4_26_ISig 1;
BA_ "SystemSignalLongSymbol" SG_ 2671834150 InternalTesterDiagSig_F4_26_ISig "InternalTesterDiagSig_F4_26_ISig_4";
BA_ "GenSigSendType" SG_ 2671834149 InternalTesterDiagSig_F4_25_ISig 7;
BA_ "Platform_VMCU1_Sig" SG_ 2671834149 InternalTesterDiagSig_F4_25_ISig 1;
BA_ "SystemSignalLongSymbol" SG_ 2671834149 InternalTesterDiagSig_F4_25_ISig "InternalTesterDiagSig_F4_25_ISig_4";
BA_ "GenSigSendType" SG_ 2671834148 InternalTesterDiagSig_F4_24_ISig 7;
BA_ "Platform_VMCU1_Sig" SG_ 2671834148 InternalTesterDiagSig_F4_24_ISig 1;
BA_ "SystemSignalLongSymbol" SG_ 2671834148 InternalTesterDiagSig_F4_24_ISig "InternalTesterDiagSig_F4_24_ISig_4";
BA_ "GenSigSendType" SG_ 2671834147 InternalTesterDiagSig_F4_23_ISig 7;
BA_ "Platform_VMCU1_Sig" SG_ 2671834147 InternalTesterDiagSig_F4_23_ISig 1;
BA_ "SystemSignalLongSymbol" SG_ 2671834147 InternalTesterDiagSig_F4_23_ISig "InternalTesterDiagSig_F4_23_ISig_4";
BA_ "GenSigSendType" SG_ 2671834146 InternalTesterDiagSig_F4_22_ISig 7;
BA_ "Platform_VMCU1_Sig" SG_ 2671834146 InternalTesterDiagSig_F4_22_ISig 1;
BA_ "SystemSignalLongSymbol" SG_ 2671834146 InternalTesterDiagSig_F4_22_ISig "InternalTesterDiagSig_F4_22_ISig_4";
BA_ "GenSigSendType" SG_ 2671834145 InternalTesterDiagSig_F4_21_ISig 7;
BA_ "Platform_VMCU1_Sig" SG_ 2671834145 InternalTesterDiagSig_F4_21_ISig 1;
BA_ "SystemSignalLongSymbol" SG_ 2671834145 InternalTesterDiagSig_F4_21_ISig "InternalTesterDiagSig_F4_21_ISig_4";
BA_ "GenSigSendType" SG_ 2671834144 InternalTesterDiagSig_F4_20_ISig 7;
BA_ "Platform_VMCU1_Sig" SG_ 2671834144 InternalTesterDiagSig_F4_20_ISig 1;
BA_ "SystemSignalLongSymbol" SG_ 2671834144 InternalTesterDiagSig_F4_20_ISig "InternalTesterDiagSig_F4_20_ISig_4";
BA_ "GenSigSendType" SG_ 2671834138 InternalTesterDiagSig_F4_1A_ISig 7;
BA_ "SystemSignalLongSymbol" SG_ 2671834138 InternalTesterDiagSig_F4_1A_ISig "InternalTesterDiagSig_F4_1A_ISig_4";
BA_ "GenSigSendType" SG_ 2671834136 InternalTesterDiagSig_F4_18_ISig 7;
BA_ "Platform_VMCU1_Sig" SG_ 2671834136 InternalTesterDiagSig_F4_18_ISig 1;
BA_ "SystemSignalLongSymbol" SG_ 2671834136 InternalTesterDiagSig_F4_18_ISig "InternalTesterDiagSig_F4_18_ISig_4";
BA_ "GenSigSendType" SG_ 2671834128 InternalTesterDiagSig_F4_10_ISig 7;
BA_ "Platform_VMCU1_Sig" SG_ 2671834128 InternalTesterDiagSig_F4_10_ISig 1;
BA_ "SystemSignalLongSymbol" SG_ 2671834128 InternalTesterDiagSig_F4_10_ISig "InternalTesterDiagSig_F4_10_ISig_4";
BA_ "GenSigSendType" SG_ 2671834095 InternalTesterDiagSig_F3_EF 7;
BA_ "GenSigSendType" SG_ 2671834050 InternalTesterDiagSig_F3_C2 7;
BA_ "GenSigCycleTimeActive" SG_ 2671834050 InternalTesterDiagSig_F3_C2 100;
BA_ "GenSigSendType" SG_ 2671834021 InternalTesterDiagSig_F3_A5_ISig 7;
BA_ "SystemSignalLongSymbol" SG_ 2671834021 InternalTesterDiagSig_F3_A5_ISig "InternalTesterDiagSig_F3_A5_ISig_4";
BA_ "GenSigSendType" SG_ 2671833971 InternalTesterDiagSig_F3_73_ISig 7;
BA_ "SystemSignalLongSymbol" SG_ 2671833971 InternalTesterDiagSig_F3_73_ISig "InternalTesterDiagSig_F3_73_ISig_4";
BA_ "GenSigSendType" SG_ 2671833957 InternalTesterDiagSig_F3_65_ISig 7;
BA_ "SystemSignalLongSymbol" SG_ 2671833957 InternalTesterDiagSig_F3_65_ISig "InternalTesterDiagSig_F3_65_ISig_4";
BA_ "GenSigSendType" SG_ 2671833912 InternalTesterDiagSig_F3_38_ISig 7;
BA_ "SystemSignalLongSymbol" SG_ 2671833912 InternalTesterDiagSig_F3_38_ISig "InternalTesterDiagSig_F3_38_ISig_4";
BA_ "GenSigSendType" SG_ 2671834086 InternalTesterDiagSig_F3_E6 7;
BA_ "Platform_VMCU1_Sig" SG_ 2671834086 InternalTesterDiagSig_F3_E6 1;
BA_ "GenSigSendType" SG_ 2671834085 InternalTesterDiagSig_F3_E5_ISig 7;
BA_ "SystemSignalLongSymbol" SG_ 2671834085 InternalTesterDiagSig_F3_E5_ISig "InternalTesterDiagSig_F3_E5_ISig_4";
BA_ "GenSigSendType" SG_ 2671834048 InternalTesterDiagSig_F3_C0_ISig 7;
BA_ "Platform_VMCU1_Sig" SG_ 2671834048 InternalTesterDiagSig_F3_C0_ISig 1;
BA_ "SystemSignalLongSymbol" SG_ 2671834048 InternalTesterDiagSig_F3_C0_ISig "InternalTesterDiagSig_F3_C0_ISig_4";
BA_ "GenSigSendType" SG_ 2671834018 InternalTesterDiagSig_F3_A2_ISig 7;
BA_ "Platform_VMCU1_Sig" SG_ 2671834018 InternalTesterDiagSig_F3_A2_ISig 1;
BA_ "SystemSignalLongSymbol" SG_ 2671834018 InternalTesterDiagSig_F3_A2_ISig "InternalTesterDiagSig_F3_A2_ISig_4";
BA_ "GenSigSendType" SG_ 2671834017 InternalTesterDiagSig_F3_A1_ISig 7;
BA_ "Platform_VMCU1_Sig" SG_ 2671834017 InternalTesterDiagSig_F3_A1_ISig 1;
BA_ "SystemSignalLongSymbol" SG_ 2671834017 InternalTesterDiagSig_F3_A1_ISig "InternalTesterDiagSig_F3_A1_ISig_4";
BA_ "GenSigSendType" SG_ 2671834016 InternalTesterDiagSig_F3_A0_ISig 7;
BA_ "Platform_VMCU1_Sig" SG_ 2671834016 InternalTesterDiagSig_F3_A0_ISig 1;
BA_ "SystemSignalLongSymbol" SG_ 2671834016 InternalTesterDiagSig_F3_A0_ISig "InternalTesterDiagSig_F3_A0_ISig_4";
BA_ "GenSigSendType" SG_ 2671834008 InternalTesterDiagSig_F3_98_ISig 7;
BA_ "Platform_VMCU1_Sig" SG_ 2671834008 InternalTesterDiagSig_F3_98_ISig 1;
BA_ "SystemSignalLongSymbol" SG_ 2671834008 InternalTesterDiagSig_F3_98_ISig "InternalTesterDiagSig_F3_98_ISig_4";
BA_ "GenSigSendType" SG_ 2671833996 InternalTesterDiagSig_F3_8C_ISig 7;
BA_ "SystemSignalLongSymbol" SG_ 2671833996 InternalTesterDiagSig_F3_8C_ISig "InternalTesterDiagSig_F3_8C_ISig_4";
BA_ "GenSigSendType" SG_ 2671833970 InternalTesterDiagSig_F3_72_ISig 7;
BA_ "SystemSignalLongSymbol" SG_ 2671833970 InternalTesterDiagSig_F3_72_ISig "InternalTesterDiagSig_F3_72_ISig_4";
BA_ "GenSigSendType" SG_ 2671833969 InternalTesterDiagSig_F3_71_ISig 7;
BA_ "SystemSignalLongSymbol" SG_ 2671833969 InternalTesterDiagSig_F3_71_ISig "InternalTesterDiagSig_F3_71_ISig_4";
BA_ "GenSigSendType" SG_ 2671833939 InternalTesterDiagSig_F3_53_ISig 7;
BA_ "Platform_VMCU1_Sig" SG_ 2671833939 InternalTesterDiagSig_F3_53_ISig 1;
BA_ "SystemSignalLongSymbol" SG_ 2671833939 InternalTesterDiagSig_F3_53_ISig "InternalTesterDiagSig_F3_53_ISig_4";
BA_ "GenSigSendType" SG_ 2671833938 InternalTesterDiagSig_F3_52_ISig 7;
BA_ "Platform_VMCU1_Sig" SG_ 2671833938 InternalTesterDiagSig_F3_52_ISig 1;
BA_ "SystemSignalLongSymbol" SG_ 2671833938 InternalTesterDiagSig_F3_52_ISig "InternalTesterDiagSig_F3_52_ISig_4";
BA_ "GenSigSendType" SG_ 2671833937 InternalTesterDiagSig_F3_51_ISig 7;
BA_ "Platform_VMCU1_Sig" SG_ 2671833937 InternalTesterDiagSig_F3_51_ISig 1;
BA_ "SystemSignalLongSymbol" SG_ 2671833937 InternalTesterDiagSig_F3_51_ISig "InternalTesterDiagSig_F3_51_ISig_4";
BA_ "GenSigSendType" SG_ 2671833936 InternalTesterDiagSig_F3_50 7;
BA_ "Platform_VMCU1_Sig" SG_ 2671833936 InternalTesterDiagSig_F3_50 1;
BA_ "GenSigSendType" SG_ 2671833920 InternalTesterDiagSig_F3_40 7;
BA_ "Platform_VMCU1_Sig" SG_ 2671833920 InternalTesterDiagSig_F3_40 1;
BA_ "GenSigSendType" SG_ 2671833905 InternalTesterDiagSig_F3_31_ISig 7;
BA_ "Platform_VMCU1_Sig" SG_ 2671833905 InternalTesterDiagSig_F3_31_ISig 1;
BA_ "SystemSignalLongSymbol" SG_ 2671833905 InternalTesterDiagSig_F3_31_ISig "InternalTesterDiagSig_F3_31_ISig_4";
BA_ "GenSigSendType" SG_ 2671833904 InternalTesterDiagSig_F3_30_ISig 7;
BA_ "Platform_VMCU1_Sig" SG_ 2671833904 InternalTesterDiagSig_F3_30_ISig 1;
BA_ "SystemSignalLongSymbol" SG_ 2671833904 InternalTesterDiagSig_F3_30_ISig "InternalTesterDiagSig_F3_30_ISig_4";
BA_ "GenSigSendType" SG_ 2671833894 InternalTesterDiagSig_F3_26_ISig 7;
BA_ "Platform_VMCU1_Sig" SG_ 2671833894 InternalTesterDiagSig_F3_26_ISig 1;
BA_ "SystemSignalLongSymbol" SG_ 2671833894 InternalTesterDiagSig_F3_26_ISig "InternalTesterDiagSig_F3_26_ISig_4";
BA_ "GenSigSendType" SG_ 2671833893 InternalTesterDiagSig_F3_25_ISig 7;
BA_ "Platform_VMCU1_Sig" SG_ 2671833893 InternalTesterDiagSig_F3_25_ISig 1;
BA_ "SystemSignalLongSymbol" SG_ 2671833893 InternalTesterDiagSig_F3_25_ISig "InternalTesterDiagSig_F3_25_ISig_4";
BA_ "GenSigSendType" SG_ 2671833892 InternalTesterDiagSig_F3_24 7;
BA_ "Platform_VMCU1_Sig" SG_ 2671833892 InternalTesterDiagSig_F3_24 1;
BA_ "GenSigSendType" SG_ 2671833891 InternalTesterDiagSig_F3_23_ISig 7;
BA_ "Platform_VMCU1_Sig" SG_ 2671833891 InternalTesterDiagSig_F3_23_ISig 1;
BA_ "SystemSignalLongSymbol" SG_ 2671833891 InternalTesterDiagSig_F3_23_ISig "InternalTesterDiagSig_F3_23_ISig_4";
BA_ "GenSigSendType" SG_ 2671833890 InternalTesterDiagSig_F3_22_ISig 7;
BA_ "Platform_VMCU1_Sig" SG_ 2671833890 InternalTesterDiagSig_F3_22_ISig 1;
BA_ "SystemSignalLongSymbol" SG_ 2671833890 InternalTesterDiagSig_F3_22_ISig "InternalTesterDiagSig_F3_22_ISig_4";
BA_ "GenSigSendType" SG_ 2671833889 InternalTesterDiagSig_F3_21_ISig 7;
BA_ "Platform_VMCU1_Sig" SG_ 2671833889 InternalTesterDiagSig_F3_21_ISig 1;
BA_ "SystemSignalLongSymbol" SG_ 2671833889 InternalTesterDiagSig_F3_21_ISig "InternalTesterDiagSig_F3_21_ISig_4";
BA_ "GenSigSendType" SG_ 2671833888 InternalTesterDiagSig_F3_20_ISig 7;
BA_ "Platform_VMCU1_Sig" SG_ 2671833888 InternalTesterDiagSig_F3_20_ISig 1;
BA_ "SystemSignalLongSymbol" SG_ 2671833888 InternalTesterDiagSig_F3_20_ISig "InternalTesterDiagSig_F3_20_ISig_4";
BA_ "GenSigSendType" SG_ 2671833882 InternalTesterDiagSig_F3_1A_ISig 7;
BA_ "SystemSignalLongSymbol" SG_ 2671833882 InternalTesterDiagSig_F3_1A_ISig "InternalTesterDiagSig_F3_1A_ISig_4";
BA_ "GenSigSendType" SG_ 2671833880 InternalTesterDiagSig_F3_18 7;
BA_ "Platform_VMCU1_Sig" SG_ 2671833880 InternalTesterDiagSig_F3_18 1;
BA_ "GenSigSendType" SG_ 2671833872 InternalTesterDiagSig_F3_10 7;
BA_ "Platform_VMCU1_Sig" SG_ 2671833872 InternalTesterDiagSig_F3_10 1;
BA_ "GenSigSendType" SG_ 2671833076 InternalTesterDiagSig_EF_F4_ISig 7;
BA_ "SystemSignalLongSymbol" SG_ 2671833076 InternalTesterDiagSig_EF_F4_ISig "InternalTesterDiagSig_EF_F4_ISig_4";
BA_ "GenSigSendType" SG_ 2671821556 InternalTesterDiagSig_C2_F4_ISig 7;
BA_ "GenSigCycleTimeActive" SG_ 2671821556 InternalTesterDiagSig_C2_F4_ISig 100;
BA_ "SystemSignalLongSymbol" SG_ 2671821556 InternalTesterDiagSig_C2_F4_ISig "InternalTesterDiagSig_C2_F4_ISig_4";
BA_ "GenSigSendType" SG_ 2671814132 InternalTesterDiagSig_A5_F4_ISig 7;
BA_ "SystemSignalLongSymbol" SG_ 2671814132 InternalTesterDiagSig_A5_F4_ISig "InternalTesterDiagSig_A5_F4_ISig_4";
BA_ "GenSigSendType" SG_ 2671801332 InternalTesterDiagSig_73_F4_ISig 7;
BA_ "SystemSignalLongSymbol" SG_ 2671801332 InternalTesterDiagSig_73_F4_ISig "InternalTesterDiagSig_73_F4_ISig_4";
BA_ "GenSigSendType" SG_ 2671797748 InternalTesterDiagSig_65_F4_ISig 7;
BA_ "SystemSignalLongSymbol" SG_ 2671797748 InternalTesterDiagSig_65_F4_ISig "InternalTesterDiagSig_65_F4_ISig_4";
BA_ "GenSigSendType" SG_ 2671786228 InternalTesterDiagSig_38_F4_ISig 7;
BA_ "SystemSignalLongSymbol" SG_ 2671786228 InternalTesterDiagSig_38_F4_ISig "InternalTesterDiagSig_38_F4_ISig_4";
BA_ "GenSigSendType" SG_ 2671830772 InternalTesterDiagSig_E6_F4_ISig 7;
BA_ "Platform_VMCU1_Sig" SG_ 2671830772 InternalTesterDiagSig_E6_F4_ISig 1;
BA_ "SystemSignalLongSymbol" SG_ 2671830772 InternalTesterDiagSig_E6_F4_ISig "InternalTesterDiagSig_E6_F4_ISig_4";
BA_ "GenSigSendType" SG_ 2671830516 InternalTesterDiagSig_E5_F4_ISig 7;
BA_ "SystemSignalLongSymbol" SG_ 2671830516 InternalTesterDiagSig_E5_F4_ISig "InternalTesterDiagSig_E5_F4_ISig_4";
BA_ "GenSigSendType" SG_ 2671821044 InternalTesterDiagSig_C0_F4_ISig 7;
BA_ "Platform_VMCU1_Sig" SG_ 2671821044 InternalTesterDiagSig_C0_F4_ISig 1;
BA_ "SystemSignalLongSymbol" SG_ 2671821044 InternalTesterDiagSig_C0_F4_ISig "InternalTesterDiagSig_C0_F4_ISig_4";
BA_REL_ "GenSigFirstTimeoutTime" BU_SG_REL_ EMS SG_ 1414 GPSData_Altitude_ISig_4_586 12000;
BA_REL_ "GenSigTimeoutTime" BU_SG_REL_ EMS SG_ 1414 GPSData_Altitude_ISig_4_586 3000;
BA_REL_ "GenSigFirstTimeoutTime" BU_SG_REL_ EMS SG_ 1414 GPSData_Longitude_ISig_4_586 12000;
BA_REL_ "GenSigTimeoutTime" BU_SG_REL_ EMS SG_ 1414 GPSData_Longitude_ISig_4_586 3000;
BA_REL_ "GenSigFirstTimeoutTime" BU_SG_REL_ EMS SG_ 1414 GPSData_HDOP_ISig_4_586 12000;
BA_REL_ "GenSigTimeoutTime" BU_SG_REL_ EMS SG_ 1414 GPSData_HDOP_ISig_4_586 3000;
BA_REL_ "GenSigFirstTimeoutTime" BU_SG_REL_ EMS SG_ 1414 GPSData_Direction_ISig_4_586 12000;
BA_REL_ "GenSigTimeoutTime" BU_SG_REL_ EMS SG_ 1414 GPSData_Direction_ISig_4_586 3000;
BA_REL_ "GenSigFirstTimeoutTime" BU_SG_REL_ EMS SG_ 1414 GPSData_Time_ISig_4_586 12000;
BA_REL_ "GenSigTimeoutTime" BU_SG_REL_ EMS SG_ 1414 GPSData_Time_ISig_4_586 3000;
BA_REL_ "GenSigFirstTimeoutTime" BU_SG_REL_ EMS SG_ 1414 GPSData_VehSpeed_ISig_4_586 12000;
BA_REL_ "GenSigTimeoutTime" BU_SG_REL_ EMS SG_ 1414 GPSData_VehSpeed_ISig_4_586 3000;
BA_REL_ "GenSigFirstTimeoutTime" BU_SG_REL_ EMS SG_ 1414 GPSData_AntennaStat_ISig_4_586 12000;
BA_REL_ "GenSigTimeoutTime" BU_SG_REL_ EMS SG_ 1414 GPSData_AntennaStat_ISig_4_586 3000;
BA_REL_ "GenSigFirstTimeoutTime" BU_SG_REL_ EMS SG_ 1414 GPSData_Latitude_ISig_4_586 12000;
BA_REL_ "GenSigTimeoutTime" BU_SG_REL_ EMS SG_ 1414 GPSData_Latitude_ISig_4_586 3000;
BA_REL_ "GenSigFirstTimeoutTime" BU_SG_REL_ DACU SG_ 1381 GPSData_HDOP_ISig_4_565 12000;
BA_REL_ "GenSigTimeoutTime" BU_SG_REL_ DACU SG_ 1381 GPSData_HDOP_ISig_4_565 3000;
BA_REL_ "GenSigFirstTimeoutTime" BU_SG_REL_ DACU SG_ 1381 GPSData_VehSpeed_ISig_4_565 12000;
BA_REL_ "GenSigTimeoutTime" BU_SG_REL_ DACU SG_ 1381 GPSData_VehSpeed_ISig_4_565 3000;
BA_REL_ "GenSigFirstTimeoutTime" BU_SG_REL_ DACU SG_ 1381 GPSData_AntennaStat_ISig_4_565 12000;
BA_REL_ "GenSigTimeoutTime" BU_SG_REL_ DACU SG_ 1381 GPSData_AntennaStat_ISig_4_565 3000;
BA_REL_ "GenSigFirstTimeoutTime" BU_SG_REL_ DACU SG_ 1381 GPSData_Latitude_ISig_4_565 12000;
BA_REL_ "GenSigTimeoutTime" BU_SG_REL_ DACU SG_ 1381 GPSData_Latitude_ISig_4_565 3000;
BA_REL_ "GenSigFirstTimeoutTime" BU_SG_REL_ DACU SG_ 1381 GPSData_Time_ISig_4_565 12000;
BA_REL_ "GenSigTimeoutTime" BU_SG_REL_ DACU SG_ 1381 GPSData_Time_ISig_4_565 3000;
BA_REL_ "GenSigFirstTimeoutTime" BU_SG_REL_ DACU SG_ 1381 GPSData_Direction_ISig_4_565 12000;
BA_REL_ "GenSigTimeoutTime" BU_SG_REL_ DACU SG_ 1381 GPSData_Direction_ISig_4_565 3000;
BA_REL_ "GenSigFirstTimeoutTime" BU_SG_REL_ DACU SG_ 1381 GPSData_Longitude_ISig_4_565 12000;
BA_REL_ "GenSigTimeoutTime" BU_SG_REL_ DACU SG_ 1381 GPSData_Longitude_ISig_4_565 3000;
BA_REL_ "GenSigFirstTimeoutTime" BU_SG_REL_ DACU SG_ 1381 GPSData_Altitude_ISig_4_565 12000;
BA_REL_ "GenSigTimeoutTime" BU_SG_REL_ DACU SG_ 1381 GPSData_Altitude_ISig_4_565 3000;
BA_REL_ "GenSigFirstTimeoutTime" BU_SG_REL_ CIOM SG_ 1386 GPSData_HDOP_ISig_4_56a 12000;
BA_REL_ "GenSigTimeoutTime" BU_SG_REL_ CIOM SG_ 1386 GPSData_HDOP_ISig_4_56a 3000;
BA_REL_ "GenSigFirstTimeoutTime" BU_SG_REL_ CIOM SG_ 1386 GPSData_Latitude_ISig_4_56a 12000;
BA_REL_ "GenSigTimeoutTime" BU_SG_REL_ CIOM SG_ 1386 GPSData_Latitude_ISig_4_56a 3000;
BA_REL_ "GenSigFirstTimeoutTime" BU_SG_REL_ CIOM SG_ 1386 GPSData_Time_ISig_4_56a 12000;
BA_REL_ "GenSigTimeoutTime" BU_SG_REL_ CIOM SG_ 1386 GPSData_Time_ISig_4_56a 3000;
BA_REL_ "GenSigFirstTimeoutTime" BU_SG_REL_ CIOM SG_ 1386 GPSData_Direction_ISig_4_56a 12000;
BA_REL_ "GenSigTimeoutTime" BU_SG_REL_ CIOM SG_ 1386 GPSData_Direction_ISig_4_56a 3000;
BA_REL_ "GenSigFirstTimeoutTime" BU_SG_REL_ CIOM SG_ 1386 GPSData_AntennaStat_ISig_4_56a 12000;
BA_REL_ "GenSigTimeoutTime" BU_SG_REL_ CIOM SG_ 1386 GPSData_AntennaStat_ISig_4_56a 3000;
BA_REL_ "GenSigFirstTimeoutTime" BU_SG_REL_ CIOM SG_ 1386 GPSData_Longitude_ISig_4_56a 12000;
BA_REL_ "GenSigTimeoutTime" BU_SG_REL_ CIOM SG_ 1386 GPSData_Longitude_ISig_4_56a 3000;
BA_REL_ "GenSigFirstTimeoutTime" BU_SG_REL_ CIOM SG_ 1386 GPSData_VehSpeed_ISig_4_56a 12000;
BA_REL_ "GenSigTimeoutTime" BU_SG_REL_ CIOM SG_ 1386 GPSData_VehSpeed_ISig_4_56a 3000;
BA_REL_ "GenSigFirstTimeoutTime" BU_SG_REL_ CIOM SG_ 1386 GPSData_Altitude_ISig_4_56a 12000;
BA_REL_ "GenSigTimeoutTime" BU_SG_REL_ CIOM SG_ 1386 GPSData_Altitude_ISig_4_56a 3000;
BA_REL_ "GenSigFirstTimeoutTime" BU_SG_REL_ BBM SG_ 1384 GPSData_Time_ISig_4_568 12000;
BA_REL_ "GenSigTimeoutTime" BU_SG_REL_ BBM SG_ 1384 GPSData_Time_ISig_4_568 3000;
BA_REL_ "GenSigFirstTimeoutTime" BU_SG_REL_ BBM SG_ 1384 GPSData_HDOP_ISig_4_568 12000;
BA_REL_ "GenSigTimeoutTime" BU_SG_REL_ BBM SG_ 1384 GPSData_HDOP_ISig_4_568 3000;
BA_REL_ "GenSigFirstTimeoutTime" BU_SG_REL_ BBM SG_ 1384 GPSData_Direction_ISig_4_568 12000;
BA_REL_ "GenSigTimeoutTime" BU_SG_REL_ BBM SG_ 1384 GPSData_Direction_ISig_4_568 3000;
BA_REL_ "GenSigFirstTimeoutTime" BU_SG_REL_ BBM SG_ 1384 GPSData_Longitude_ISig_4_568 12000;
BA_REL_ "GenSigTimeoutTime" BU_SG_REL_ BBM SG_ 1384 GPSData_Longitude_ISig_4_568 3000;
BA_REL_ "GenSigFirstTimeoutTime" BU_SG_REL_ BBM SG_ 1384 GPSData_VehSpeed_ISig_4_568 12000;
BA_REL_ "GenSigTimeoutTime" BU_SG_REL_ BBM SG_ 1384 GPSData_VehSpeed_ISig_4_568 3000;
BA_REL_ "GenSigFirstTimeoutTime" BU_SG_REL_ BBM SG_ 1384 GPSData_Altitude_ISig_4_568 12000;
BA_REL_ "GenSigTimeoutTime" BU_SG_REL_ BBM SG_ 1384 GPSData_Altitude_ISig_4_568 3000;
BA_REL_ "GenSigFirstTimeoutTime" BU_SG_REL_ BBM SG_ 1384 GPSData_Latitude_ISig_4_568 12000;
BA_REL_ "GenSigTimeoutTime" BU_SG_REL_ BBM SG_ 1384 GPSData_Latitude_ISig_4_568 3000;
BA_REL_ "GenSigFirstTimeoutTime" BU_SG_REL_ BBM SG_ 1384 GPSData_AntennaStat_ISig_4_568 12000;
BA_REL_ "GenSigTimeoutTime" BU_SG_REL_ BBM SG_ 1384 GPSData_AntennaStat_ISig_4_568 3000;
BA_REL_ "GenSigFirstTimeoutTime" BU_SG_REL_ CIOM SG_ 979 PinCodeEntered_value 3000;
BA_REL_ "GenSigTimeoutTime" BU_SG_REL_ CIOM SG_ 979 PinCodeEntered_value 450;
BA_REL_ "GenSigFirstTimeoutTime" BU_SG_REL_ CIOM SG_ 979 DynamicCode_rqst 3000;
BA_REL_ "GenSigTimeoutTime" BU_SG_REL_ CIOM SG_ 979 DynamicCode_rqst 450;
BA_REL_ "GenSigFirstTimeoutTime" BU_SG_REL_ VMCU SG_ 979 LogDisplayedMessage_req 3000;
BA_REL_ "GenSigTimeoutTime" BU_SG_REL_ VMCU SG_ 979 LogDisplayedMessage_req 500;
BA_REL_ "GenSigFirstTimeoutTime" BU_SG_REL_ VMCU SG_ 970 FirstAxleLowerPrioRequested_ISig 3000;
BA_REL_ "GenSigTimeoutTime" BU_SG_REL_ VMCU SG_ 970 FirstAxleLowerPrioRequested_ISig 500;
BA_REL_ "GenSigFirstTimeoutTime" BU_SG_REL_ CIOM SG_ 970 Synch_Unsynch_Mode_stat 3000;
BA_REL_ "GenSigTimeoutTime" BU_SG_REL_ CIOM SG_ 970 Synch_Unsynch_Mode_stat 450;
BA_REL_ "GenSigFirstTimeoutTime" BU_SG_REL_ CIOM SG_ 970 PreTripIndication3_ISig_4 3000;
BA_REL_ "GenSigTimeoutTime" BU_SG_REL_ CIOM SG_ 970 PreTripIndication3_ISig_4 450;
BA_REL_ "GenSigFirstTimeoutTime" BU_SG_REL_ VMCU SG_ 970 SelectedSpeedUnit_stat_ISig_4 3000;
BA_REL_ "GenSigTimeoutTime" BU_SG_REL_ VMCU SG_ 970 SelectedSpeedUnit_stat_ISig_4 450;
BA_REL_ "GenSigFirstTimeoutTime" BU_SG_REL_ BBM SG_ 970 SelectedLanguage_stat_ISig_4 3000;
BA_REL_ "GenSigTimeoutTime" BU_SG_REL_ BBM SG_ 970 SelectedLanguage_stat_ISig_4 450;
BA_REL_ "GenSigFirstTimeoutTime" BU_SG_REL_ CIOM SG_ 970 SelectedLanguage_stat_ISig_4 3000;
BA_REL_ "GenSigTimeoutTime" BU_SG_REL_ CIOM SG_ 970 SelectedLanguage_stat_ISig_4 450;
BA_REL_ "GenSigFirstTimeoutTime" BU_SG_REL_ VMCU SG_ 970 LampCheck_rqst_ISig_4 3000;
BA_REL_ "GenSigTimeoutTime" BU_SG_REL_ VMCU SG_ 970 LampCheck_rqst_ISig_4 450;
BA_REL_ "GenSigFirstTimeoutTime" BU_SG_REL_ CIOM SG_ 970 SelectedWeightUnit_stat_ISig_4 3000;
BA_REL_ "GenSigTimeoutTime" BU_SG_REL_ CIOM SG_ 970 SelectedWeightUnit_stat_ISig_4 450;
BA_REL_ "GenSigFirstTimeoutTime" BU_SG_REL_ CIOM SG_ 970 SpeedLockingInhibition_stat 3000;
BA_REL_ "GenSigTimeoutTime" BU_SG_REL_ CIOM SG_ 970 SpeedLockingInhibition_stat 450;
BA_REL_ "GenSigFirstTimeoutTime" BU_SG_REL_ CIOM SG_ 970 DriverMemory_rqst_ISig_4 3000;
BA_REL_ "GenSigTimeoutTime" BU_SG_REL_ CIOM SG_ 970 DriverMemory_rqst_ISig_4 450;
BA_REL_ "GenSigFirstTimeoutTime" BU_SG_REL_ VMCU SG_ 970 DriverMemory_rqst_ISig_4 3000;
BA_REL_ "GenSigTimeoutTime" BU_SG_REL_ VMCU SG_ 970 DriverMemory_rqst_ISig_4 450;
BA_REL_ "GenSigFirstTimeoutTime" BU_SG_REL_ CIOM SG_ 970 SelectedTimeFormat_stat_ISig_4 3000;
BA_REL_ "GenSigTimeoutTime" BU_SG_REL_ CIOM SG_ 970 SelectedTimeFormat_stat_ISig_4 450;
BA_REL_ "GenSigFirstTimeoutTime" BU_SG_REL_ VMCU SG_ 970 MaintInfo_rqst 3000;
BA_REL_ "GenSigTimeoutTime" BU_SG_REL_ VMCU SG_ 970 MaintInfo_rqst 450;
BA_REL_ "GenSigFirstTimeoutTime" BU_SG_REL_ DACU SG_ 970 LCSSoundSettingRequest 3000;
BA_REL_ "GenSigTimeoutTime" BU_SG_REL_ DACU SG_ 970 LCSSoundSettingRequest 450;
BA_REL_ "GenSigFirstTimeoutTime" BU_SG_REL_ CIOM SG_ 851 BunkBacklightCmd_ISig_4 3000;
BA_REL_ "GenSigTimeoutTime" BU_SG_REL_ CIOM SG_ 851 BunkBacklightCmd_ISig_4 360;
BA_REL_ "GenSigFirstTimeoutTime" BU_SG_REL_ DACU SG_ 1270 SpeedAdaptEnableRqst_SpeedLimit 4800;
BA_REL_ "GenSigTimeoutTime" BU_SG_REL_ DACU SG_ 1270 SpeedAdaptEnableRqst_SpeedLimit 1200;
BA_REL_ "GenSigFirstTimeoutTime" BU_SG_REL_ TECU SG_ 1270 SpeedAdaptEnableRqst_SpeedLimit 4800;
BA_REL_ "GenSigTimeoutTime" BU_SG_REL_ TECU SG_ 1270 SpeedAdaptEnableRqst_SpeedLimit 1200;
BA_REL_ "GenSigFirstTimeoutTime" BU_SG_REL_ TECU SG_ 1270 SpeedAdaptEnableRqst_Curve 4800;
BA_REL_ "GenSigTimeoutTime" BU_SG_REL_ TECU SG_ 1270 SpeedAdaptEnableRqst_Curve 1200;
BA_REL_ "GenSigFirstTimeoutTime" BU_SG_REL_ DACU SG_ 1270 SpeedAdaptEnableRqst_Curve 4800;
BA_REL_ "GenSigTimeoutTime" BU_SG_REL_ DACU SG_ 1270 SpeedAdaptEnableRqst_Curve 1200;
BA_REL_ "GenSigFirstTimeoutTime" BU_SG_REL_ BBM SG_ 1270 CabLightIntensity_stat_ISig_4 4800;
BA_REL_ "GenSigTimeoutTime" BU_SG_REL_ BBM SG_ 1270 CabLightIntensity_stat_ISig_4 1200;
BA_REL_ "GenSigFirstTimeoutTime" BU_SG_REL_ DACU SG_ 1270 CabLightIntensity_stat_ISig_4 4800;
BA_REL_ "GenSigTimeoutTime" BU_SG_REL_ DACU SG_ 1270 CabLightIntensity_stat_ISig_4 1200;
BA_REL_ "GenSigFirstTimeoutTime" BU_SG_REL_ DACU SG_ 1270 SpeedAdaptEnableRqst_SlowTraffic 4800;
BA_REL_ "GenSigTimeoutTime" BU_SG_REL_ DACU SG_ 1270 SpeedAdaptEnableRqst_SlowTraffic 1200;
BA_REL_ "GenSigFirstTimeoutTime" BU_SG_REL_ TECU SG_ 1270 SpeedAdaptEnableRqst_SlowTraffic 4800;
BA_REL_ "GenSigTimeoutTime" BU_SG_REL_ TECU SG_ 1270 SpeedAdaptEnableRqst_SlowTraffic 1200;
BA_REL_ "GenSigFirstTimeoutTime" BU_SG_REL_ VMCU SG_ 1270 ExtTimeData_ExtTime_ISig_4 4800;
BA_REL_ "GenSigTimeoutTime" BU_SG_REL_ VMCU SG_ 1270 ExtTimeData_ExtTime_ISig_4 1200;
BA_REL_ "GenSigFirstTimeoutTime" BU_SG_REL_ VMCU SG_ 1270 ExtTimeData_Quality_ISig_4 4800;
BA_REL_ "GenSigTimeoutTime" BU_SG_REL_ VMCU SG_ 1270 ExtTimeData_Quality_ISig_4 1200;
BA_REL_ "GenSigFirstTimeoutTime" BU_SG_REL_ DACU SG_ 1270 SpeedAdaptationLevelRqst 4800;
BA_REL_ "GenSigTimeoutTime" BU_SG_REL_ DACU SG_ 1270 SpeedAdaptationLevelRqst 1200;
BA_REL_ "GenSigFirstTimeoutTime" BU_SG_REL_ TECU SG_ 1270 SpeedAdaptationLevelRqst 4800;
BA_REL_ "GenSigTimeoutTime" BU_SG_REL_ TECU SG_ 1270 SpeedAdaptationLevelRqst 1200;
BA_REL_ "GenSigFirstTimeoutTime" BU_SG_REL_ VMCU SG_ 739 CCBOverspeedRequest 3000;
BA_REL_ "GenSigTimeoutTime" BU_SG_REL_ VMCU SG_ 739 CCBOverspeedRequest 210;
BA_REL_ "GenSigFirstTimeoutTime" BU_SG_REL_ VMCU SG_ 739 XRSLDriverRequest 3000;
BA_REL_ "GenSigTimeoutTime" BU_SG_REL_ VMCU SG_ 739 XRSLDriverRequest 210;
BA_REL_ "GenSigFirstTimeoutTime" BU_SG_REL_ VMCU SG_ 739 DHCActiveRequest 3000;
BA_REL_ "GenSigTimeoutTime" BU_SG_REL_ VMCU SG_ 739 DHCActiveRequest 210;
BA_REL_ "GenSigFirstTimeoutTime" BU_SG_REL_ CIOM SG_ 739 CCEnableRequest_ISig_4 3000;
BA_REL_ "GenSigTimeoutTime" BU_SG_REL_ CIOM SG_ 739 CCEnableRequest_ISig_4 210;
BA_REL_ "GenSigFirstTimeoutTime" BU_SG_REL_ VMCU SG_ 739 CCEnableRequest_ISig_4 3000;
BA_REL_ "GenSigTimeoutTime" BU_SG_REL_ VMCU SG_ 739 CCEnableRequest_ISig_4 210;
BA_REL_ "GenSigFirstTimeoutTime" BU_SG_REL_ BBM SG_ 739 CCEnableRequest_ISig_4 3000;
BA_REL_ "GenSigTimeoutTime" BU_SG_REL_ BBM SG_ 739 CCEnableRequest_ISig_4 210;
BA_REL_ "GenSigFirstTimeoutTime" BU_SG_REL_ VMCU SG_ 739 CCRequestedPresetSpeed 3000;
BA_REL_ "GenSigTimeoutTime" BU_SG_REL_ VMCU SG_ 739 CCRequestedPresetSpeed 210;
BA_REL_ "GenSigFirstTimeoutTime" BU_SG_REL_ VMCU SG_ 739 CCDriverRequest 3000;
BA_REL_ "GenSigTimeoutTime" BU_SG_REL_ VMCU SG_ 739 CCDriverRequest 210;
BA_REL_ "GenSigFirstTimeoutTime" BU_SG_REL_ BBM SG_ 739 CCDriverRequest 3000;
BA_REL_ "GenSigTimeoutTime" BU_SG_REL_ BBM SG_ 739 CCDriverRequest 210;
BA_REL_ "GenSigFirstTimeoutTime" BU_SG_REL_ VMCU SG_ 739 RSLMgrsetTRSLOpCtrl 3000;
BA_REL_ "GenSigTimeoutTime" BU_SG_REL_ VMCU SG_ 739 RSLMgrsetTRSLOpCtrl 210;
BA_REL_ "GenSigFirstTimeoutTime" BU_SG_REL_ TECU SG_ 390 EcoRollEnableRequest_ISig_4 3000;
BA_REL_ "GenSigTimeoutTime" BU_SG_REL_ TECU SG_ 390 EcoRollEnableRequest_ISig_4 90;
BA_REL_ "GenSigFirstTimeoutTime" BU_SG_REL_ EMS SG_ 390 SelectedEcoCruiseLevel_ISig_4 12000;
BA_REL_ "GenSigTimeoutTime" BU_SG_REL_ EMS SG_ 390 SelectedEcoCruiseLevel_ISig_4 3000;
BA_REL_ "GenSigFirstTimeoutTime" BU_SG_REL_ DACU SG_ 390 SelectedEcoCruiseLevel_ISig_4 3000;
BA_REL_ "GenSigTimeoutTime" BU_SG_REL_ DACU SG_ 390 SelectedEcoCruiseLevel_ISig_4 90;
BA_REL_ "GenSigFirstTimeoutTime" BU_SG_REL_ TECU SG_ 390 SelectedEcoCruiseLevel_ISig_4 3000;
BA_REL_ "GenSigTimeoutTime" BU_SG_REL_ TECU SG_ 390 SelectedEcoCruiseLevel_ISig_4 90;
BA_REL_ "GenSigFirstTimeoutTime" BU_SG_REL_ VMCU SG_ 390 SelectedEcoCruiseLevel_ISig_4 3000;
BA_REL_ "GenSigTimeoutTime" BU_SG_REL_ VMCU SG_ 390 SelectedEcoCruiseLevel_ISig_4 90;
BA_REL_ "GenSigFirstTimeoutTime" BU_SG_REL_ VMCU SG_ 514 PS_GearSelectionMode_ISig_4 3000;
BA_REL_ "GenSigTimeoutTime" BU_SG_REL_ VMCU SG_ 514 PS_GearSelectionMode_ISig_4 150;
BA_REL_ "GenSigFirstTimeoutTime" BU_SG_REL_ EMS SG_ 514 WaterInFuelDrainRequest 3000;
BA_REL_ "GenSigTimeoutTime" BU_SG_REL_ EMS SG_ 514 WaterInFuelDrainRequest 150;
BA_REL_ "GenSigFirstTimeoutTime" BU_SG_REL_ BBM SG_ 514 SW_Mute_ButtonStatus_6_ISig_4 3000;
BA_REL_ "GenSigTimeoutTime" BU_SG_REL_ BBM SG_ 514 SW_Mute_ButtonStatus_6_ISig_4 150;
BA_REL_ "GenSigFirstTimeoutTime" BU_SG_REL_ DACU SG_ 514 FuncIndIlluminationLevel_ISig_4 3000;
BA_REL_ "GenSigTimeoutTime" BU_SG_REL_ DACU SG_ 514 FuncIndIlluminationLevel_ISig_4 150;
BA_REL_ "GenSigFirstTimeoutTime" BU_SG_REL_ VMCU SG_ 514 FuncIndIlluminationLevel_ISig_4 3000;
BA_REL_ "GenSigTimeoutTime" BU_SG_REL_ VMCU SG_ 514 FuncIndIlluminationLevel_ISig_4 150;
BA_REL_ "GenSigFirstTimeoutTime" BU_SG_REL_ CIOM SG_ 514 FuncIndIlluminationLevel_ISig_4 3000;
BA_REL_ "GenSigTimeoutTime" BU_SG_REL_ CIOM SG_ 514 FuncIndIlluminationLevel_ISig_4 150;
BA_REL_ "GenSigFirstTimeoutTime" BU_SG_REL_ BBM SG_ 514 SW_VolDown_ButtonStatus_6_ISig_4 3000;
BA_REL_ "GenSigTimeoutTime" BU_SG_REL_ BBM SG_ 514 SW_VolDown_ButtonStatus_6_ISig_4 150;
BA_REL_ "GenSigFirstTimeoutTime" BU_SG_REL_ DACU SG_ 514 ResumeRequestForACC 3000;
BA_REL_ "GenSigTimeoutTime" BU_SG_REL_ DACU SG_ 514 ResumeRequestForACC 150;
BA_REL_ "GenSigFirstTimeoutTime" BU_SG_REL_ DACU SG_ 514 CACCTimeGapRqst 3000;
BA_REL_ "GenSigTimeoutTime" BU_SG_REL_ DACU SG_ 514 CACCTimeGapRqst 150;
BA_REL_ "GenSigFirstTimeoutTime" BU_SG_REL_ VMCU SG_ 514 SWSpeedControlAdjustMode 3000;
BA_REL_ "GenSigTimeoutTime" BU_SG_REL_ VMCU SG_ 514 SWSpeedControlAdjustMode 150;
BA_REL_ "GenSigFirstTimeoutTime" BU_SG_REL_ CIOM SG_ 514 SWSpeedControlAdjustMode 3000;
BA_REL_ "GenSigTimeoutTime" BU_SG_REL_ CIOM SG_ 514 SWSpeedControlAdjustMode 150;
BA_REL_ "GenSigFirstTimeoutTime" BU_SG_REL_ DACU SG_ 514 ACCTimeGapRqst 3000;
BA_REL_ "GenSigTimeoutTime" BU_SG_REL_ DACU SG_ 514 ACCTimeGapRqst 150;
BA_REL_ "GenSigFirstTimeoutTime" BU_SG_REL_ CIOM SG_ 514 SWSpdCtrlButtonsStatus6 3000;
BA_REL_ "GenSigTimeoutTime" BU_SG_REL_ CIOM SG_ 514 SWSpdCtrlButtonsStatus6 150;
BA_REL_ "GenSigFirstTimeoutTime" BU_SG_REL_ BBM SG_ 514 SWSpdCtrlButtonsStatus6 3000;
BA_REL_ "GenSigTimeoutTime" BU_SG_REL_ BBM SG_ 514 SWSpdCtrlButtonsStatus6 150;
BA_REL_ "GenSigFirstTimeoutTime" BU_SG_REL_ VMCU SG_ 514 ACCEnableRqst 3000;
BA_REL_ "GenSigTimeoutTime" BU_SG_REL_ VMCU SG_ 514 ACCEnableRqst 150;
BA_REL_ "GenSigFirstTimeoutTime" BU_SG_REL_ DACU SG_ 514 ACCEnableRqst 3000;
BA_REL_ "GenSigTimeoutTime" BU_SG_REL_ DACU SG_ 514 ACCEnableRqst 150;
BA_REL_ "GenSigFirstTimeoutTime" BU_SG_REL_ CIOM SG_ 514 ACCEnableRqst 3000;
BA_REL_ "GenSigTimeoutTime" BU_SG_REL_ CIOM SG_ 514 ACCEnableRqst 150;
BA_REL_ "GenSigFirstTimeoutTime" BU_SG_REL_ VMCU SG_ 514 StopAlert_cmd 3000;
BA_REL_ "GenSigTimeoutTime" BU_SG_REL_ VMCU SG_ 514 StopAlert_cmd 150;
BA_REL_ "GenSigFirstTimeoutTime" BU_SG_REL_ BBM SG_ 514 SW_VolUp_ButtonStatus_6_ISig_4 3000;
BA_REL_ "GenSigTimeoutTime" BU_SG_REL_ BBM SG_ 514 SW_VolUp_ButtonStatus_6_ISig_4 150;
BA_REL_ "GenSigFirstTimeoutTime" BU_SG_REL_ CIOM SG_ 514 BacklightCmd_ISig_4 3000;
BA_REL_ "GenSigTimeoutTime" BU_SG_REL_ CIOM SG_ 514 BacklightCmd_ISig_4 150;
BA_REL_ "GenSigFirstTimeoutTime" BU_SG_REL_ DACU SG_ 514 BacklightCmd_ISig_4 3000;
BA_REL_ "GenSigTimeoutTime" BU_SG_REL_ DACU SG_ 514 BacklightCmd_ISig_4 150;
BA_REL_ "GenSigFirstTimeoutTime" BU_SG_REL_ VMCU SG_ 514 BacklightCmd_ISig_4 3000;
BA_REL_ "GenSigTimeoutTime" BU_SG_REL_ VMCU SG_ 514 BacklightCmd_ISig_4 150;
BA_REL_ "GenSigFirstTimeoutTime" BU_SG_REL_ DACU SG_ 514 CMTelltale_stat 3000;
BA_REL_ "GenSigTimeoutTime" BU_SG_REL_ DACU SG_ 514 CMTelltale_stat 150;
BA_REL_ "GenSigFirstTimeoutTime" BU_SG_REL_ VMCU SG_ 1288 OBDDrivingCycle 24000;
BA_REL_ "GenSigTimeoutTime" BU_SG_REL_ VMCU SG_ 1288 OBDDrivingCycle 6000;
BA_REL_ "GenSigFirstTimeoutTime" BU_SG_REL_ VMCU SG_ 1288 EcoCruisePwtMaxOvSpeedLev3 24000;
BA_REL_ "GenSigTimeoutTime" BU_SG_REL_ VMCU SG_ 1288 EcoCruisePwtMaxOvSpeedLev3 6000;
BA_REL_ "GenSigFirstTimeoutTime" BU_SG_REL_ VMCU SG_ 1288 EcoCruisePwtMaxOvSpeedLev0 24000;
BA_REL_ "GenSigTimeoutTime" BU_SG_REL_ VMCU SG_ 1288 EcoCruisePwtMaxOvSpeedLev0 6000;
BA_REL_ "GenSigFirstTimeoutTime" BU_SG_REL_ VMCU SG_ 1288 EcoCruisePwtMaxUnSpeedLev0 24000;
BA_REL_ "GenSigTimeoutTime" BU_SG_REL_ VMCU SG_ 1288 EcoCruisePwtMaxUnSpeedLev0 6000;
BA_REL_ "GenSigFirstTimeoutTime" BU_SG_REL_ VMCU SG_ 1288 EcoCruisePwtMaxOvSpeedLev2 24000;
BA_REL_ "GenSigTimeoutTime" BU_SG_REL_ VMCU SG_ 1288 EcoCruisePwtMaxOvSpeedLev2 6000;
BA_REL_ "GenSigFirstTimeoutTime" BU_SG_REL_ VMCU SG_ 1288 EcoCruisePwtMaxOvSpeedLev1 24000;
BA_REL_ "GenSigTimeoutTime" BU_SG_REL_ VMCU SG_ 1288 EcoCruisePwtMaxOvSpeedLev1 6000;
BA_REL_ "GenSigFirstTimeoutTime" BU_SG_REL_ VMCU SG_ 1288 EcoCruisePwtMaxUnSpeedLev3 24000;
BA_REL_ "GenSigTimeoutTime" BU_SG_REL_ VMCU SG_ 1288 EcoCruisePwtMaxUnSpeedLev3 6000;
BA_REL_ "GenSigFirstTimeoutTime" BU_SG_REL_ VMCU SG_ 1288 EcoCruisePwtMaxUnSpeedLev1 24000;
BA_REL_ "GenSigTimeoutTime" BU_SG_REL_ VMCU SG_ 1288 EcoCruisePwtMaxUnSpeedLev1 6000;
BA_REL_ "GenSigFirstTimeoutTime" BU_SG_REL_ VMCU SG_ 1288 EcoCruisePwtMaxUnSpeedLev2 24000;
BA_REL_ "GenSigTimeoutTime" BU_SG_REL_ VMCU SG_ 1288 EcoCruisePwtMaxUnSpeedLev2 6000;
BA_REL_ "GenSigFirstTimeoutTime" BU_SG_REL_ VMCU SG_ 1285 TotPTOLNGHighAccuracy 24000;
BA_REL_ "GenSigTimeoutTime" BU_SG_REL_ VMCU SG_ 1285 TotPTOLNGHighAccuracy 6000;
BA_REL_ "GenSigFirstTimeoutTime" BU_SG_REL_ VMCU SG_ 1282 ExhManif_EMAIAirTankPres_ISig_4 12000;
BA_REL_ "GenSigTimeoutTime" BU_SG_REL_ VMCU SG_ 1282 ExhManif_EMAIAirTankPres_ISig_4 3000;
BA_REL_ "GenSigFirstTimeoutTime" BU_SG_REL_ VMCU SG_ 1282 EngineFuelMode 12000;
BA_REL_ "GenSigTimeoutTime" BU_SG_REL_ VMCU SG_ 1282 EngineFuelMode 3000;
BA_REL_ "GenSigFirstTimeoutTime" BU_SG_REL_ IC3 SG_ 1282 LNGOperatorInducementReason_ISig 12000;
BA_REL_ "GenSigTimeoutTime" BU_SG_REL_ IC3 SG_ 1282 LNGOperatorInducementReason_ISig 3000;
BA_REL_ "GenSigFirstTimeoutTime" BU_SG_REL_ CIOM SG_ 1282 EngineTotalLngConsumed_ISig_4 12000;
BA_REL_ "GenSigTimeoutTime" BU_SG_REL_ CIOM SG_ 1282 EngineTotalLngConsumed_ISig_4 3000;
BA_REL_ "GenSigFirstTimeoutTime" BU_SG_REL_ IC3 SG_ 1282 EngineTotalLngConsumed_ISig_4 12000;
BA_REL_ "GenSigTimeoutTime" BU_SG_REL_ IC3 SG_ 1282 EngineTotalLngConsumed_ISig_4 3000;
BA_REL_ "GenSigFirstTimeoutTime" BU_SG_REL_ VMCU SG_ 1282 EngineTotalLngConsumed_ISig_4 12000;
BA_REL_ "GenSigTimeoutTime" BU_SG_REL_ VMCU SG_ 1282 EngineTotalLngConsumed_ISig_4 3000;
BA_REL_ "GenSigFirstTimeoutTime" BU_SG_REL_ IC3 SG_ 1252 DistLeftToSevereInducement_OBD 24000;
BA_REL_ "GenSigTimeoutTime" BU_SG_REL_ IC3 SG_ 1252 DistLeftToSevereInducement_OBD 6000;
BA_REL_ "GenSigFirstTimeoutTime" BU_SG_REL_ IC3 SG_ 1252 TopGearUseDistance_ISig_4 24000;
BA_REL_ "GenSigTimeoutTime" BU_SG_REL_ IC3 SG_ 1252 TopGearUseDistance_ISig_4 6000;
BA_REL_ "GenSigFirstTimeoutTime" BU_SG_REL_ IC3 SG_ 1252 EMS_Available_Log_ISig_4 24000;
BA_REL_ "GenSigTimeoutTime" BU_SG_REL_ IC3 SG_ 1252 EMS_Available_Log_ISig_4 6000;
BA_REL_ "GenSigFirstTimeoutTime" BU_SG_REL_ IC3 SG_ 1374 TimeLeftToTorqueReduction_OBD 24000;
BA_REL_ "GenSigTimeoutTime" BU_SG_REL_ IC3 SG_ 1374 TimeLeftToTorqueReduction_OBD 6000;
BA_REL_ "GenSigFirstTimeoutTime" BU_SG_REL_ VMCU SG_ 1374 AdblueTotalConsumed_ISig_4 24000;
BA_REL_ "GenSigTimeoutTime" BU_SG_REL_ VMCU SG_ 1374 AdblueTotalConsumed_ISig_4 6000;
BA_REL_ "GenSigFirstTimeoutTime" BU_SG_REL_ IC3 SG_ 1374 AdblueTotalConsumed_ISig_4 24000;
BA_REL_ "GenSigTimeoutTime" BU_SG_REL_ IC3 SG_ 1374 AdblueTotalConsumed_ISig_4 6000;
BA_REL_ "GenSigFirstTimeoutTime" BU_SG_REL_ VMCU SG_ 1374 MIStatus_ISig_4 24000;
BA_REL_ "GenSigTimeoutTime" BU_SG_REL_ VMCU SG_ 1374 MIStatus_ISig_4 6000;
BA_REL_ "GenSigFirstTimeoutTime" BU_SG_REL_ IC3 SG_ 1374 MIStatus_ISig_4 24000;
BA_REL_ "GenSigTimeoutTime" BU_SG_REL_ IC3 SG_ 1374 MIStatus_ISig_4 6000;
BA_REL_ "GenSigFirstTimeoutTime" BU_SG_REL_ IC3 SG_ 1374 TorqueReductionStatus_OBD 24000;
BA_REL_ "GenSigTimeoutTime" BU_SG_REL_ IC3 SG_ 1374 TorqueReductionStatus_OBD 6000;
BA_REL_ "GenSigFirstTimeoutTime" BU_SG_REL_ IC3 SG_ 1374 SCROperatorInducementSeverity 24000;
BA_REL_ "GenSigTimeoutTime" BU_SG_REL_ IC3 SG_ 1374 SCROperatorInducementSeverity 6000;
BA_REL_ "GenSigFirstTimeoutTime" BU_SG_REL_ IC3 SG_ 1374 SCROperatorInducementReason 24000;
BA_REL_ "GenSigTimeoutTime" BU_SG_REL_ IC3 SG_ 1374 SCROperatorInducementReason 6000;
BA_REL_ "GenSigFirstTimeoutTime" BU_SG_REL_ VMCU SG_ 1374 MIDistinctWarning 24000;
BA_REL_ "GenSigTimeoutTime" BU_SG_REL_ VMCU SG_ 1374 MIDistinctWarning 6000;
BA_REL_ "GenSigFirstTimeoutTime" BU_SG_REL_ IC3 SG_ 1374 MIDistinctWarning 24000;
BA_REL_ "GenSigTimeoutTime" BU_SG_REL_ IC3 SG_ 1374 MIDistinctWarning 6000;
BA_REL_ "GenSigFirstTimeoutTime" BU_SG_REL_ IC3 SG_ 1374 MIStatusExtEMS 24000;
BA_REL_ "GenSigTimeoutTime" BU_SG_REL_ IC3 SG_ 1374 MIStatusExtEMS 6000;
BA_REL_ "GenSigFirstTimeoutTime" BU_SG_REL_ VMCU SG_ 1374 MIDistinctWarningExtEMS_ISig_4 24000;
BA_REL_ "GenSigTimeoutTime" BU_SG_REL_ VMCU SG_ 1374 MIDistinctWarningExtEMS_ISig_4 6000;
BA_REL_ "GenSigFirstTimeoutTime" BU_SG_REL_ IC3 SG_ 1374 MIDistinctWarningExtEMS_ISig_4 24000;
BA_REL_ "GenSigTimeoutTime" BU_SG_REL_ IC3 SG_ 1374 MIDistinctWarningExtEMS_ISig_4 6000;
BA_REL_ "GenSigFirstTimeoutTime" BU_SG_REL_ BBM SG_ 1392 EngineRunningTime_ISig_4 28800;
BA_REL_ "GenSigTimeoutTime" BU_SG_REL_ BBM SG_ 1392 EngineRunningTime_ISig_4 7200;
BA_REL_ "GenSigFirstTimeoutTime" BU_SG_REL_ IC3 SG_ 1392 EngineRunningTime_ISig_4 28800;
BA_REL_ "GenSigTimeoutTime" BU_SG_REL_ IC3 SG_ 1392 EngineRunningTime_ISig_4 7200;
BA_REL_ "GenSigFirstTimeoutTime" BU_SG_REL_ VMCU SG_ 1392 EngineRunningTime_ISig_4 28800;
BA_REL_ "GenSigTimeoutTime" BU_SG_REL_ VMCU SG_ 1392 EngineRunningTime_ISig_4 7200;
BA_REL_ "GenSigFirstTimeoutTime" BU_SG_REL_ CIOM SG_ 1392 EngineRunningTime_ISig_4 28800;
BA_REL_ "GenSigTimeoutTime" BU_SG_REL_ CIOM SG_ 1392 EngineRunningTime_ISig_4 7200;
BA_REL_ "GenSigFirstTimeoutTime" BU_SG_REL_ VMCU SG_ 1392 TotPTOFuelHighAccuracy 28800;
BA_REL_ "GenSigTimeoutTime" BU_SG_REL_ VMCU SG_ 1392 TotPTOFuelHighAccuracy 7200;
BA_REL_ "GenSigFirstTimeoutTime" BU_SG_REL_ CIOM SG_ 1391 OilPrediction_Quality 36000;
BA_REL_ "GenSigTimeoutTime" BU_SG_REL_ CIOM SG_ 1391 OilPrediction_Quality 9000;
BA_REL_ "GenSigFirstTimeoutTime" BU_SG_REL_ VMCU SG_ 1391 OilPrediction_Quality 36000;
BA_REL_ "GenSigTimeoutTime" BU_SG_REL_ VMCU SG_ 1391 OilPrediction_Quality 9000;
BA_REL_ "GenSigFirstTimeoutTime" BU_SG_REL_ IC3 SG_ 1391 TimeLeftToVehSpdReduction_OBD 36000;
BA_REL_ "GenSigTimeoutTime" BU_SG_REL_ IC3 SG_ 1391 TimeLeftToVehSpdReduction_OBD 9000;
BA_REL_ "GenSigFirstTimeoutTime" BU_SG_REL_ CIOM SG_ 1391 OilPrediction_RemainDist 36000;
BA_REL_ "GenSigTimeoutTime" BU_SG_REL_ CIOM SG_ 1391 OilPrediction_RemainDist 9000;
BA_REL_ "GenSigFirstTimeoutTime" BU_SG_REL_ VMCU SG_ 1391 OilPrediction_RemainDist 36000;
BA_REL_ "GenSigTimeoutTime" BU_SG_REL_ VMCU SG_ 1391 OilPrediction_RemainDist 9000;
BA_REL_ "GenSigFirstTimeoutTime" BU_SG_REL_ IC3 SG_ 1391 TimeToCorrectOilLevel_ISig_4 36000;
BA_REL_ "GenSigTimeoutTime" BU_SG_REL_ IC3 SG_ 1391 TimeToCorrectOilLevel_ISig_4 9000;
BA_REL_ "GenSigFirstTimeoutTime" BU_SG_REL_ VMCU SG_ 1391 OilPrediction_RemainTime 36000;
BA_REL_ "GenSigTimeoutTime" BU_SG_REL_ VMCU SG_ 1391 OilPrediction_RemainTime 9000;
BA_REL_ "GenSigFirstTimeoutTime" BU_SG_REL_ CIOM SG_ 1391 OilPrediction_RemainTime 36000;
BA_REL_ "GenSigTimeoutTime" BU_SG_REL_ CIOM SG_ 1391 OilPrediction_RemainTime 9000;
BA_REL_ "GenSigFirstTimeoutTime" BU_SG_REL_ CIOM SG_ 1391 OilPrediction_Status 36000;
BA_REL_ "GenSigTimeoutTime" BU_SG_REL_ CIOM SG_ 1391 OilPrediction_Status 9000;
BA_REL_ "GenSigFirstTimeoutTime" BU_SG_REL_ VMCU SG_ 1391 OilPrediction_Status 36000;
BA_REL_ "GenSigTimeoutTime" BU_SG_REL_ VMCU SG_ 1391 OilPrediction_Status 9000;
BA_REL_ "GenSigFirstTimeoutTime" BU_SG_REL_ CIOM SG_ 1276 EngineCoolingFanSpeed_ISig_4 6000;
BA_REL_ "GenSigTimeoutTime" BU_SG_REL_ CIOM SG_ 1276 EngineCoolingFanSpeed_ISig_4 1500;
BA_REL_ "GenSigFirstTimeoutTime" BU_SG_REL_ VMCU SG_ 1276 DMSDriverFollow 6000;
BA_REL_ "GenSigTimeoutTime" BU_SG_REL_ VMCU SG_ 1276 DMSDriverFollow 1500;
BA_REL_ "GenSigFirstTimeoutTime" BU_SG_REL_ IC3 SG_ 1276 DPF_ParkedRegenStatus 6000;
BA_REL_ "GenSigTimeoutTime" BU_SG_REL_ IC3 SG_ 1276 DPF_ParkedRegenStatus 1500;
BA_REL_ "GenSigFirstTimeoutTime" BU_SG_REL_ CIOM SG_ 1276 CoolantPumpEngagementStatus_ISig 6000;
BA_REL_ "GenSigTimeoutTime" BU_SG_REL_ CIOM SG_ 1276 CoolantPumpEngagementStatus_ISig 1500;
BA_REL_ "GenSigFirstTimeoutTime" BU_SG_REL_ IC3 SG_ 1276 AverageFuelEconomy_ISig_4 6000;
BA_REL_ "GenSigTimeoutTime" BU_SG_REL_ IC3 SG_ 1276 AverageFuelEconomy_ISig_4 1500;
BA_REL_ "GenSigFirstTimeoutTime" BU_SG_REL_ VMCU SG_ 1276 EngineGasRate 6000;
BA_REL_ "GenSigTimeoutTime" BU_SG_REL_ VMCU SG_ 1276 EngineGasRate 1500;
BA_REL_ "GenSigFirstTimeoutTime" BU_SG_REL_ CIOM SG_ 1276 EngineGasRate 6000;
BA_REL_ "GenSigTimeoutTime" BU_SG_REL_ CIOM SG_ 1276 EngineGasRate 1500;
BA_REL_ "GenSigFirstTimeoutTime" BU_SG_REL_ VMCU SG_ 1276 FuelEcoEngStatus 6000;
BA_REL_ "GenSigTimeoutTime" BU_SG_REL_ VMCU SG_ 1276 FuelEcoEngStatus 1500;
BA_REL_ "GenSigFirstTimeoutTime" BU_SG_REL_ IC3 SG_ 1291 DrainPrimingStatus_ISig_4 6000;
BA_REL_ "GenSigTimeoutTime" BU_SG_REL_ IC3 SG_ 1291 DrainPrimingStatus_ISig_4 1500;
BA_REL_ "GenSigFirstTimeoutTime" BU_SG_REL_ IC3 SG_ 1291 CoolantTempHigh_ISig_4 6000;
BA_REL_ "GenSigTimeoutTime" BU_SG_REL_ IC3 SG_ 1291 CoolantTempHigh_ISig_4 1500;
BA_REL_ "GenSigFirstTimeoutTime" BU_SG_REL_ VMCU SG_ 1291 CoolantTempHigh_ISig_4 6000;
BA_REL_ "GenSigTimeoutTime" BU_SG_REL_ VMCU SG_ 1291 CoolantTempHigh_ISig_4 1500;
BA_REL_ "GenSigFirstTimeoutTime" BU_SG_REL_ BBM SG_ 1291 CoolantTempHigh_ISig_4 6000;
BA_REL_ "GenSigTimeoutTime" BU_SG_REL_ BBM SG_ 1291 CoolantTempHigh_ISig_4 1500;
BA_REL_ "GenSigFirstTimeoutTime" BU_SG_REL_ VMCU SG_ 1291 CoolantLevelLow_ISig_4 6000;
BA_REL_ "GenSigTimeoutTime" BU_SG_REL_ VMCU SG_ 1291 CoolantLevelLow_ISig_4 1500;
BA_REL_ "GenSigFirstTimeoutTime" BU_SG_REL_ BBM SG_ 1291 CoolantLevelLow_ISig_4 6000;
BA_REL_ "GenSigTimeoutTime" BU_SG_REL_ BBM SG_ 1291 CoolantLevelLow_ISig_4 1500;
BA_REL_ "GenSigFirstTimeoutTime" BU_SG_REL_ IC3 SG_ 1291 CoolantLevelLow_ISig_4 6000;
BA_REL_ "GenSigTimeoutTime" BU_SG_REL_ IC3 SG_ 1291 CoolantLevelLow_ISig_4 1500;
BA_REL_ "GenSigFirstTimeoutTime" BU_SG_REL_ IC3 SG_ 1291 AutoWheelBrakesStatus 6000;
BA_REL_ "GenSigTimeoutTime" BU_SG_REL_ IC3 SG_ 1291 AutoWheelBrakesStatus 1500;
BA_REL_ "GenSigFirstTimeoutTime" BU_SG_REL_ TECU SG_ 1291 AutoWheelBrakesStatus 6000;
BA_REL_ "GenSigTimeoutTime" BU_SG_REL_ TECU SG_ 1291 AutoWheelBrakesStatus 1500;
BA_REL_ "GenSigFirstTimeoutTime" BU_SG_REL_ VMCU SG_ 1291 OilPressureLow_ISig_4 6000;
BA_REL_ "GenSigTimeoutTime" BU_SG_REL_ VMCU SG_ 1291 OilPressureLow_ISig_4 1500;
BA_REL_ "GenSigFirstTimeoutTime" BU_SG_REL_ IC3 SG_ 1291 OilPressureLow_ISig_4 6000;
BA_REL_ "GenSigTimeoutTime" BU_SG_REL_ IC3 SG_ 1291 OilPressureLow_ISig_4 1500;
BA_REL_ "GenSigFirstTimeoutTime" BU_SG_REL_ BBM SG_ 1291 OilPressureLow_ISig_4 6000;
BA_REL_ "GenSigTimeoutTime" BU_SG_REL_ BBM SG_ 1291 OilPressureLow_ISig_4 1500;
BA_REL_ "GenSigFirstTimeoutTime" BU_SG_REL_ IC3 SG_ 1291 EngineTotalFuelConsumed_ISig_4 6000;
BA_REL_ "GenSigTimeoutTime" BU_SG_REL_ IC3 SG_ 1291 EngineTotalFuelConsumed_ISig_4 1500;
BA_REL_ "GenSigFirstTimeoutTime" BU_SG_REL_ BBM SG_ 1291 EngineTotalFuelConsumed_ISig_4 6000;
BA_REL_ "GenSigTimeoutTime" BU_SG_REL_ BBM SG_ 1291 EngineTotalFuelConsumed_ISig_4 1500;
BA_REL_ "GenSigFirstTimeoutTime" BU_SG_REL_ CIOM SG_ 1291 EngineTotalFuelConsumed_ISig_4 6000;
BA_REL_ "GenSigTimeoutTime" BU_SG_REL_ CIOM SG_ 1291 EngineTotalFuelConsumed_ISig_4 1500;
BA_REL_ "GenSigFirstTimeoutTime" BU_SG_REL_ VMCU SG_ 1291 EngineTotalFuelConsumed_ISig_4 6000;
BA_REL_ "GenSigTimeoutTime" BU_SG_REL_ VMCU SG_ 1291 EngineTotalFuelConsumed_ISig_4 1500;
BA_REL_ "GenSigFirstTimeoutTime" BU_SG_REL_ TECU SG_ 1291 EngineTotalFuelConsumed_ISig_4 3000;
BA_REL_ "GenSigTimeoutTime" BU_SG_REL_ TECU SG_ 1291 EngineTotalFuelConsumed_ISig_4 1500;
BA_REL_ "GenSigFirstTimeoutTime" BU_SG_REL_ IC3 SG_ 1291 TopGearMode_ISig_4 6000;
BA_REL_ "GenSigTimeoutTime" BU_SG_REL_ IC3 SG_ 1291 TopGearMode_ISig_4 1500;
BA_REL_ "GenSigFirstTimeoutTime" BU_SG_REL_ IC3 SG_ 1291 OilLevelLow_ISig_4 6000;
BA_REL_ "GenSigTimeoutTime" BU_SG_REL_ IC3 SG_ 1291 OilLevelLow_ISig_4 1500;
BA_REL_ "GenSigFirstTimeoutTime" BU_SG_REL_ BBM SG_ 1291 OilLevelLow_ISig_4 6000;
BA_REL_ "GenSigTimeoutTime" BU_SG_REL_ BBM SG_ 1291 OilLevelLow_ISig_4 1500;
BA_REL_ "GenSigFirstTimeoutTime" BU_SG_REL_ TECU SG_ 1291 BarometricPressure_ISig_4 6000;
BA_REL_ "GenSigTimeoutTime" BU_SG_REL_ TECU SG_ 1291 BarometricPressure_ISig_4 1500;
BA_REL_ "GenSigFirstTimeoutTime" BU_SG_REL_ BBM SG_ 1291 BarometricPressure_ISig_4 6000;
BA_REL_ "GenSigTimeoutTime" BU_SG_REL_ BBM SG_ 1291 BarometricPressure_ISig_4 1500;
BA_REL_ "GenSigFirstTimeoutTime" BU_SG_REL_ VMCU SG_ 1291 BarometricPressure_ISig_4 6000;
BA_REL_ "GenSigTimeoutTime" BU_SG_REL_ VMCU SG_ 1291 BarometricPressure_ISig_4 1500;
BA_REL_ "GenSigFirstTimeoutTime" BU_SG_REL_ CIOM SG_ 1291 BarometricPressure_ISig_4 6000;
BA_REL_ "GenSigTimeoutTime" BU_SG_REL_ CIOM SG_ 1291 BarometricPressure_ISig_4 1500;
BA_REL_ "GenSigFirstTimeoutTime" BU_SG_REL_ IC3 SG_ 1291 InletAirHeaterStatus1 6000;
BA_REL_ "GenSigTimeoutTime" BU_SG_REL_ IC3 SG_ 1291 InletAirHeaterStatus1 1500;
BA_REL_ "GenSigFirstTimeoutTime" BU_SG_REL_ IC3 SG_ 1279 FuelFilterClogged 6000;
BA_REL_ "GenSigTimeoutTime" BU_SG_REL_ IC3 SG_ 1279 FuelFilterClogged 1500;
BA_REL_ "GenSigFirstTimeoutTime" BU_SG_REL_ VMCU SG_ 1279 EngineAirInletTemperature 6000;
BA_REL_ "GenSigTimeoutTime" BU_SG_REL_ VMCU SG_ 1279 EngineAirInletTemperature 1500;
BA_REL_ "GenSigFirstTimeoutTime" BU_SG_REL_ IC3 SG_ 1279 StarterMotorRecoveryTime 6000;
BA_REL_ "GenSigTimeoutTime" BU_SG_REL_ IC3 SG_ 1279 StarterMotorRecoveryTime 1500;
BA_REL_ "GenSigFirstTimeoutTime" BU_SG_REL_ IC3 SG_ 1279 EngineFanOverspeed 6000;
BA_REL_ "GenSigTimeoutTime" BU_SG_REL_ IC3 SG_ 1279 EngineFanOverspeed 1500;
BA_REL_ "GenSigFirstTimeoutTime" BU_SG_REL_ VMCU SG_ 1279 AppliedVehicleSpeedLimit 6000;
BA_REL_ "GenSigTimeoutTime" BU_SG_REL_ VMCU SG_ 1279 AppliedVehicleSpeedLimit 1500;
BA_REL_ "GenSigFirstTimeoutTime" BU_SG_REL_ TECU SG_ 1279 AppliedVehicleSpeedLimit 6000;
BA_REL_ "GenSigTimeoutTime" BU_SG_REL_ TECU SG_ 1279 AppliedVehicleSpeedLimit 1500;
BA_REL_ "GenSigFirstTimeoutTime" BU_SG_REL_ VMCU SG_ 1279 EngineProtDerateStat 6000;
BA_REL_ "GenSigTimeoutTime" BU_SG_REL_ VMCU SG_ 1279 EngineProtDerateStat 1500;
BA_REL_ "GenSigFirstTimeoutTime" BU_SG_REL_ IC3 SG_ 1279 CoolantTempGaugeAdjustment 6000;
BA_REL_ "GenSigTimeoutTime" BU_SG_REL_ IC3 SG_ 1279 CoolantTempGaugeAdjustment 1500;
BA_REL_ "GenSigFirstTimeoutTime" BU_SG_REL_ VMCU SG_ 1279 AirFilterPressureDrop 6000;
BA_REL_ "GenSigTimeoutTime" BU_SG_REL_ VMCU SG_ 1279 AirFilterPressureDrop 1500;
BA_REL_ "GenSigFirstTimeoutTime" BU_SG_REL_ VMCU SG_ 733 AirFilter_AirMassFlowValidated 3000;
BA_REL_ "GenSigTimeoutTime" BU_SG_REL_ VMCU SG_ 733 AirFilter_AirMassFlowValidated 270;
BA_REL_ "GenSigFirstTimeoutTime" BU_SG_REL_ IC3 SG_ 733 DPF_LimitedSpeedDuetoInhibit 3000;
BA_REL_ "GenSigTimeoutTime" BU_SG_REL_ IC3 SG_ 733 DPF_LimitedSpeedDuetoInhibit 270;
BA_REL_ "GenSigFirstTimeoutTime" BU_SG_REL_ DACU SG_ 733 XARSystemState 3000;
BA_REL_ "GenSigTimeoutTime" BU_SG_REL_ DACU SG_ 733 XARSystemState 270;
BA_REL_ "GenSigFirstTimeoutTime" BU_SG_REL_ DACU SG_ 733 XARActiveControlMode 3000;
BA_REL_ "GenSigTimeoutTime" BU_SG_REL_ DACU SG_ 733 XARActiveControlMode 270;
BA_REL_ "GenSigFirstTimeoutTime" BU_SG_REL_ VMCU SG_ 733 AirFilter_Pressure 3000;
BA_REL_ "GenSigTimeoutTime" BU_SG_REL_ VMCU SG_ 733 AirFilter_Pressure 270;
BA_REL_ "GenSigFirstTimeoutTime" BU_SG_REL_ VMCU SG_ 733 CCBSetSpeedApplied 3000;
BA_REL_ "GenSigTimeoutTime" BU_SG_REL_ VMCU SG_ 733 CCBSetSpeedApplied 270;
BA_REL_ "GenSigFirstTimeoutTime" BU_SG_REL_ DACU SG_ 733 CCBSetSpeedApplied 3000;
BA_REL_ "GenSigTimeoutTime" BU_SG_REL_ DACU SG_ 733 CCBSetSpeedApplied 270;
BA_REL_ "GenSigFirstTimeoutTime" BU_SG_REL_ VMCU SG_ 719 CCControllerMode_ISig_4 3000;
BA_REL_ "GenSigTimeoutTime" BU_SG_REL_ VMCU SG_ 719 CCControllerMode_ISig_4 270;
BA_REL_ "GenSigFirstTimeoutTime" BU_SG_REL_ IC3 SG_ 719 CCControllerMode_ISig_4 3000;
BA_REL_ "GenSigTimeoutTime" BU_SG_REL_ IC3 SG_ 719 CCControllerMode_ISig_4 270;
BA_REL_ "GenSigFirstTimeoutTime" BU_SG_REL_ BBM SG_ 719 CrankcasePressureHigh_ISig_4 3000;
BA_REL_ "GenSigTimeoutTime" BU_SG_REL_ BBM SG_ 719 CrankcasePressureHigh_ISig_4 270;
BA_REL_ "GenSigFirstTimeoutTime" BU_SG_REL_ VMCU SG_ 719 EngineSystemPowerDownAck 3000;
BA_REL_ "GenSigTimeoutTime" BU_SG_REL_ VMCU SG_ 719 EngineSystemPowerDownAck 270;
BA_REL_ "GenSigFirstTimeoutTime" BU_SG_REL_ TECU SG_ 719 EngineActiveStatus_ISig_4 3000;
BA_REL_ "GenSigTimeoutTime" BU_SG_REL_ TECU SG_ 719 EngineActiveStatus_ISig_4 300;
BA_REL_ "GenSigFirstTimeoutTime" BU_SG_REL_ VMCU SG_ 719 EngineActiveStatus_ISig_4 3000;
BA_REL_ "GenSigTimeoutTime" BU_SG_REL_ VMCU SG_ 719 EngineActiveStatus_ISig_4 270;
BA_REL_ "GenSigFirstTimeoutTime" BU_SG_REL_ DACU SG_ 719 EngineActiveStatus_ISig_4 3000;
BA_REL_ "GenSigTimeoutTime" BU_SG_REL_ DACU SG_ 719 EngineActiveStatus_ISig_4 270;
BA_REL_ "GenSigFirstTimeoutTime" BU_SG_REL_ VMCU SG_ 719 XRSLControllerMode 3000;
BA_REL_ "GenSigTimeoutTime" BU_SG_REL_ VMCU SG_ 719 XRSLControllerMode 270;
BA_REL_ "GenSigFirstTimeoutTime" BU_SG_REL_ IC3 SG_ 719 XRSLControllerMode 3000;
BA_REL_ "GenSigTimeoutTime" BU_SG_REL_ IC3 SG_ 719 XRSLControllerMode 270;
BA_REL_ "GenSigFirstTimeoutTime" BU_SG_REL_ IC3 SG_ 719 RegenInhibDueHeight 3000;
BA_REL_ "GenSigTimeoutTime" BU_SG_REL_ IC3 SG_ 719 RegenInhibDueHeight 270;
BA_REL_ "GenSigFirstTimeoutTime" BU_SG_REL_ VMCU SG_ 719 ExhManif_AirInjActive_ISig_4 3000;
BA_REL_ "GenSigTimeoutTime" BU_SG_REL_ VMCU SG_ 719 ExhManif_AirInjActive_ISig_4 270;
BA_REL_ "GenSigFirstTimeoutTime" BU_SG_REL_ VMCU SG_ 719 CCBControllerMode 3000;
BA_REL_ "GenSigTimeoutTime" BU_SG_REL_ VMCU SG_ 719 CCBControllerMode 270;
BA_REL_ "GenSigFirstTimeoutTime" BU_SG_REL_ VMCU SG_ 719 InhibitIdleShutdownStatus 3000;
BA_REL_ "GenSigTimeoutTime" BU_SG_REL_ VMCU SG_ 719 InhibitIdleShutdownStatus 270;
BA_REL_ "GenSigFirstTimeoutTime" BU_SG_REL_ VMCU SG_ 719 EngCompartmentStopSwitchStat 3000;
BA_REL_ "GenSigTimeoutTime" BU_SG_REL_ VMCU SG_ 719 EngCompartmentStopSwitchStat 270;
BA_REL_ "GenSigFirstTimeoutTime" BU_SG_REL_ VMCU SG_ 719 EngineAirInletPressure 3000;
BA_REL_ "GenSigTimeoutTime" BU_SG_REL_ VMCU SG_ 719 EngineAirInletPressure 270;
BA_REL_ "GenSigFirstTimeoutTime" BU_SG_REL_ CIOM SG_ 719 EngineStartAuth_rqst 3000;
BA_REL_ "GenSigTimeoutTime" BU_SG_REL_ CIOM SG_ 719 EngineStartAuth_rqst 270;
BA_REL_ "GenSigFirstTimeoutTime" BU_SG_REL_ VMCU SG_ 719 IntakeAirTemperatureAlert 3000;
BA_REL_ "GenSigTimeoutTime" BU_SG_REL_ VMCU SG_ 719 IntakeAirTemperatureAlert 270;
BA_REL_ "GenSigFirstTimeoutTime" BU_SG_REL_ BBM SG_ 719 EngineOilTempHigh_ISig_4 3000;
BA_REL_ "GenSigTimeoutTime" BU_SG_REL_ BBM SG_ 719 EngineOilTempHigh_ISig_4 270;
BA_REL_ "GenSigFirstTimeoutTime" BU_SG_REL_ IC3 SG_ 719 EngineOilTempHigh_ISig_4 3000;
BA_REL_ "GenSigTimeoutTime" BU_SG_REL_ IC3 SG_ 719 EngineOilTempHigh_ISig_4 270;
BA_REL_ "GenSigFirstTimeoutTime" BU_SG_REL_ VMCU SG_ 719 WarmUpCycle 3000;
BA_REL_ "GenSigTimeoutTime" BU_SG_REL_ VMCU SG_ 719 WarmUpCycle 270;
BA_REL_ "GenSigFirstTimeoutTime" BU_SG_REL_ VMCU SG_ 719 DeterminedGear 3000;
BA_REL_ "GenSigTimeoutTime" BU_SG_REL_ VMCU SG_ 719 DeterminedGear 270;
BA_REL_ "GenSigFirstTimeoutTime" BU_SG_REL_ IC3 SG_ 719 CCSetSpeedApplied_ISig_4 3000;
BA_REL_ "GenSigTimeoutTime" BU_SG_REL_ IC3 SG_ 719 CCSetSpeedApplied_ISig_4 270;
BA_REL_ "GenSigFirstTimeoutTime" BU_SG_REL_ DACU SG_ 719 CCSetSpeedApplied_ISig_4 3000;
BA_REL_ "GenSigTimeoutTime" BU_SG_REL_ DACU SG_ 719 CCSetSpeedApplied_ISig_4 270;
BA_REL_ "GenSigFirstTimeoutTime" BU_SG_REL_ VMCU SG_ 719 CCSetSpeedApplied_ISig_4 3000;
BA_REL_ "GenSigTimeoutTime" BU_SG_REL_ VMCU SG_ 719 CCSetSpeedApplied_ISig_4 270;
VAL_ 1414 GPSData_AntennaStat_ISig_4_586 7 "GPS_Antenna_status_NA" 6 "GPS_Antenna_status_ErrorIndicator" 5 "GPS_Antenna_status_SpareValue_01" 4 "GPS_Antenna_status_SpareValue" 3 "GPS_Antenna_status_AntennaStatusUnknown" 2 "GPS_Antenna_status_AntennaInit" 1 "GPS_Antenna_status_AntennaDisconnected" 0 "GPS_Antenna_status_AntennaStatusOK" ;
VAL_ 1381 GPSData_AntennaStat_ISig_4_565 7 "GPS_Antenna_status_NA" 6 "GPS_Antenna_status_ErrorIndicator" 5 "GPS_Antenna_status_SpareValue_01" 4 "GPS_Antenna_status_SpareValue" 3 "GPS_Antenna_status_AntennaStatusUnknown" 2 "GPS_Antenna_status_AntennaInit" 1 "GPS_Antenna_status_AntennaDisconnected" 0 "GPS_Antenna_status_AntennaStatusOK" ;
VAL_ 1386 GPSData_AntennaStat_ISig_4_56a 7 "GPS_Antenna_status_NA" 6 "GPS_Antenna_status_ErrorIndicator" 5 "GPS_Antenna_status_SpareValue_01" 4 "GPS_Antenna_status_SpareValue" 3 "GPS_Antenna_status_AntennaStatusUnknown" 2 "GPS_Antenna_status_AntennaInit" 1 "GPS_Antenna_status_AntennaDisconnected" 0 "GPS_Antenna_status_AntennaStatusOK" ;
VAL_ 1384 GPSData_AntennaStat_ISig_4_568 7 "GPS_Antenna_status_NA" 6 "GPS_Antenna_status_ErrorIndicator" 5 "GPS_Antenna_status_SpareValue_01" 4 "GPS_Antenna_status_SpareValue" 3 "GPS_Antenna_status_AntennaStatusUnknown" 2 "GPS_Antenna_status_AntennaInit" 1 "GPS_Antenna_status_AntennaDisconnected" 0 "GPS_Antenna_status_AntennaStatusOK" ;
VAL_ 979 DynamicCode_rqst 7 "DynamicCode_rqst_NotAvailable" 6 "DynamicCode_rqst_Error" 1 "DynamicCode_rqst_DynamicCodeRequest" 0 "DynamicCode_rqst_Idle" ;
VAL_ 970 FirstAxleLowerPrioRequested_ISig 7 "FirstAxleLowerPrio_NotAvailable" 6 "FirstAxleLowerPrio_Error" 5 "FirstAxleLowerPrio_Reserved_03" 4 "FirstAxleLowerPrio_Reserved_02" 3 "FirstAxleLowerPrio_Reserved_01" 2 "FirstAxleLowerPrio_Reserved" 1 "FirstAxleLowerPrio_LowerPusher" 0 "FirstAxleLowerPrio_LowerTag" ;
VAL_ 970 Synch_Unsynch_Mode_stat 7 "Synch_Unsynch_Mode_stat_NotAvailable" 6 "Synch_Unsynch_Mode_stat_Error" 5 "Synch_Unsynch_Mode_stat_Spare_02" 4 "Synch_Unsynch_Mode_stat_Spare_01" 3 "Synch_Unsynch_Mode_stat_Spare" 2 "Synch_Unsynch_Mode_stat_UnsynchronizedMode" 1 "Synch_Unsynch_Mode_stat_SynchronizedMode" 0 "Synch_Unsynch_Mode_stat_Idle" ;
VAL_ 970 PreTripIndication3_ISig_4 3 "DeviceIndication_SpareValue" 2 "DeviceIndication_Blink" 1 "DeviceIndication_On" 0 "DeviceIndication_Off" ;
VAL_ 970 SelectedSpeedUnit_stat_ISig_4 3 "SpeedUnit_NotAvailable" 2 "SpeedUnit_Error" 1 "SpeedUnit_MilesPerHour" 0 "SpeedUnit_KilometersPerHour" ;
VAL_ 970 SelectedLanguage_stat_ISig_4 63 "Language_NotAvailable" 62 "Language_Error" 61 "Language_Spare_26" 60 "Language_Spare_25" 59 "Language_Spare_24" 58 "Language_Spare_23" 57 "Language_Spare_22" 56 "Language_Spare_21" 55 "Language_Spare_20" 54 "Language_Spare_19" 53 "Language_Spare_18" 52 "Language_Spare_17" 51 "Language_Spare_16" 50 "Language_Spare_15" 49 "Language_Spare_14" 48 "Language_Spare_13" 47 "Language_Spare_12" 46 "Language_Spare_11" 45 "Language_Spare_10" 44 "Language_Spare_09" 43 "Language_Spare_08" 42 "Language_Spare_07" 41 "Language_Spare_06" 40 "Language_Spare_05" 39 "Language_Spare_04" 38 "Language_Malay_Indonesian" 37 "Language_Ukrainian" 36 "Language_Bosnian" 35 "Language_Croatian" 34 "Language_Numeric" 33 "Language_Japanese" 32 "Language_Korean" 31 "Language_Chinese" 30 "Language_Thai" 29 "Language_Arabic" 28 "Language_Farsi" 27 "Language_Hebrew" 26 "Language_Turkish" 25 "Language_Hungarian" 24 "Language_Slovak" 23 "Language_Czech" 22 "Language_Slovenian" 21 "Language_Serbian" 20 "Language_Greek" 19 "Language_Bulgarian" 18 "Language_Italian" 17 "Language_Dutch" 16 "Language_Rumanian" 15 "Language_BrazilianPortugese" 14 "Language_Portugese" 13 "Language_Spanish" 12 "Language_French" 11 "Language_German" 10 "Language_Polish" 9 "Language_Lituanian" 8 "Language_Latvian" 7 "Language_Estonian" 6 "Language_Russian" 5 "Language_Finish" 4 "Language_Icelandic" 3 "Language_Norwegian" 2 "Language_Danish" 1 "Language_Swedish" 0 "Language_English" ;
VAL_ 970 LampCheck_rqst_ISig_4 3 "LampCheck_NotAvailable" 2 "LampCheck_Error" 1 "LampCheck_PerformLampCheck" 0 "LampCheck_NoAction" ;
VAL_ 970 SelectedWeightUnit_stat_ISig_4 3 "WeightUnit_NotAvailable" 2 "WeightUnit_Error" 1 "WeightUnit_Pound" 0 "WeightUnit_Kg" ;
VAL_ 970 SpeedLockingInhibition_stat 7 "SpeedLockingInhibition_stat_NotAvailable" 6 "SpeedLockingInhibition_stat_Error" 2 "SpeedLockingInhibition_stat_SpeedLockingDeactivate" 1 "SpeedLockingInhibition_stat_SpeedLockingActivate" 0 "SpeedLockingInhibition_stat_Idle" ;
VAL_ 970 DriverMemory_rqst_ISig_4 31 "DriverMemory_rqst_Error" 30 "DriverMemory_rqst_NotAvailable" 29 "DriverMemory_rqst_Spare_07" 28 "DriverMemory_rqst_Spare_06" 27 "DriverMemory_rqst_Spare_05" 26 "DriverMemory_rqst_Spare_04" 25 "DriverMemory_rqst_Spare_03" 24 "DriverMemory_rqst_Spare_02" 23 "DriverMemory_rqst_Spare_01" 22 "DriverMemory_rqst_Spare" 21 "DriverMemory_rqst_ResetAllMemThenUseDefDriverMem" 20 "DriverMemory_rqst_ResetAndThenUseDriverMemory10" 19 "DriverMemory_rqst_ResetAndThenUseDriverMemory9" 18 "DriverMemory_rqst_ResetAndThenUseDriverMemory8" 17 "DriverMemory_rqst_ResetAndThenUseDriverMemory7" 16 "DriverMemory_rqst_ResetAndThenUseDriverMemory6" 15 "DriverMemory_rqst_ResetAndThenUseDriverMemory5" 14 "DriverMemory_rqst_ResetAndThenUseDriverMemory4" 13 "DriverMemory_rqst_ResetAndThenUseDriverMemory3" 12 "DriverMemory_rqst_ResetAndThenUseDriverMemory2" 11 "DriverMemory_rqst_ResetAndThenUseDriverMemory1" 10 "DriverMemory_rqst_UseDriverMemory10" 9 "DriverMemory_rqst_UseDriverMemory9" 8 "DriverMemory_rqst_UseDriverMemory8" 7 "DriverMemory_rqst_UseDriverMemory7" 6 "DriverMemory_rqst_UseDriverMemory6" 5 "DriverMemory_rqst_UseDriverMemory5" 4 "DriverMemory_rqst_UseDriverMemory4" 3 "DriverMemory_rqst_UseDriverMemory3" 2 "DriverMemory_rqst_UseDriverMemory2" 1 "DriverMemory_rqst_UseDriverMemory1" 0 "DriverMemory_rqst_UseDefaultDriverMemory" ;
VAL_ 970 SelectedTimeFormat_stat_ISig_4 3 "TimeFormatStat_NotAvailable" 2 "TimeFormatStat_Error" 1 "TimeFormatStat_24h" 0 "TimeFormatStat_AM_PM" ;
VAL_ 970 MaintInfo_rqst 3 "Request_NotAvailable" 2 "Request_Error" 1 "Request_RequestActive" 0 "Request_NotRequested" ;
VAL_ 970 LCSSoundSettingRequest 3 "LCSSoundSettingRequest_NotAvailable" 2 "LCSSoundSettingRequest_Error" 1 "LCSSoundSettingRequest_EnableLCSSound" 0 "LCSSoundSettingRequest_DisableLCSSound" ;
VAL_ 851 BunkBacklightCmd_ISig_4 31 "BacklightCmd_NotAvailable" 30 "BacklightCmd_Error" 16 "BacklightCmd_BacklightLevel16" 15 "BacklightCmd_BacklightLevel15" 14 "BacklightCmd_BacklightLevel14" 13 "BacklightCmd_BacklightLevel13" 12 "BacklightCmd_BacklightLevel12" 11 "BacklightCmd_BacklightLevel11" 10 "BacklightCmd_BacklightLevel10" 9 "BacklightCmd_BacklightLevel9" 8 "BacklightCmd_BacklightLevel8" 7 "BacklightCmd_BacklightLevel7" 6 "BacklightCmd_BacklightLevel6" 5 "BacklightCmd_BacklightLevel5" 4 "BacklightCmd_BacklightLevel4" 3 "BacklightCmd_BacklightLevel3" 2 "BacklightCmd_BacklightLevel2" 1 "BacklightCmd_BacklightLevel1" 0 "BacklightCmd_BacklightOff" ;
VAL_ 1270 SpeedAdaptEnableRqst_SpeedLimit 3 "Selected_NotAvailable" 2 "Selected_Error" 1 "Selected_Selected" 0 "Selected_NotSelected" ;
VAL_ 1270 SpeedAdaptEnableRqst_Curve 3 "Selected_NotAvailable" 2 "Selected_Error" 1 "Selected_Selected" 0 "Selected_NotSelected" ;
VAL_ 1270 SpeedAdaptEnableRqst_SlowTraffic 3 "Selected_NotAvailable" 2 "Selected_Error" 1 "Selected_Selected" 0 "Selected_NotSelected" ;
VAL_ 1270 SpeedAdaptationLevelRqst 7 "LowMidHigh_NotAvailable" 6 "LowMidHigh_Error" 5 "LowMidHigh_Spare3" 4 "LowMidHigh_Spare2" 3 "LowMidHigh_Spare1" 2 "LowMidHigh_High" 1 "LowMidHigh_Mid" 0 "LowMidHigh_Low" ;
VAL_ 739 XRSLDriverRequest 15 "XRSLDriverRequest_NotAvailable" 14 "XRSLDriverRequest_Error" 13 "XRSLDriverRequest_Spare_06" 12 "XRSLDriverRequest_Spare_05" 11 "XRSLDriverRequest_Spare_04" 10 "XRSLDriverRequest_Spare_03" 9 "XRSLDriverRequest_Spare_02" 8 "XRSLDriverRequest_Spare_01" 7 "XRSLDriverRequest_Spare" 6 "XRSLDriverRequest_SetPresetSpeed" 5 "XRSLDriverRequest_Pause" 4 "XRSLDriverRequest_Decrease" 3 "XRSLDriverRequest_Increase" 2 "XRSLDriverRequest_ResumePreviousSpeed" 1 "XRSLDriverRequest_SetCurrentSpeed" 0 "XRSLDriverRequest_NoRequest" ;
VAL_ 739 DHCActiveRequest 3 "OffOn_NotAvailable" 2 "OffOn_Error" 1 "OffOn_On" 0 "OffOn_Off" ;
VAL_ 739 CCEnableRequest_ISig_4 3 "DisableEnable_NotAvailable" 2 "DisableEnable_Error" 1 "DisableEnable_Enable" 0 "DisableEnable_Disable" ;
VAL_ 739 CCDriverRequest 15 "CCDriverRequest_NotAvailable" 14 "CCDriverRequest_Error" 13 "CCDriverRequest_Spare_06" 12 "CCDriverRequest_Spare_05" 11 "CCDriverRequest_Spare_04" 10 "CCDriverRequest_Spare_03" 9 "CCDriverRequest_Spare_02" 8 "CCDriverRequest_Spare_01" 7 "CCDriverRequest_Spare" 6 "CCDriverRequest_SetPresetSpeed" 5 "CCDriverRequest_Pause" 4 "CCDriverRequest_Decrease" 3 "CCDriverRequest_Increase" 2 "CCDriverRequest_ResumePreviousSpeed" 1 "CCDriverRequest_SetCurrentSpeed" 0 "CCDriverRequest_NoRequest" ;
VAL_ 739 RSLMgrsetTRSLOpCtrl 3 "OffOn_NotAvailable" 2 "OffOn_Error" 1 "OffOn_On" 0 "OffOn_Off" ;
VAL_ 390 EcoRollEnableRequest_ISig_4 3 "InactiveActive_NotAvailable" 2 "InactiveActive_Error" 1 "InactiveActive_Active" 0 "InactiveActive_Inactive" ;
VAL_ 390 SelectedEcoCruiseLevel_ISig_4 7 "SelectedEcoCruiseLevel_NotAvailable" 6 "SelectedEcoCruiseLevel_Error" 5 "SelectedEcoCruiseLevel_Spare01" 4 "SelectedEcoCruiseLevel_Spare" 3 "SelectedEcoCruiseLevel_Level3" 2 "SelectedEcoCruiseLevel_Level2" 1 "SelectedEcoCruiseLevel_Level1" 0 "SelectedEcoCruiseLevel_Off" ;
VAL_ 514 PS_GearSelectionMode_ISig_4 7 "GearSelectionMode_NotAvailable" 6 "GearSelectionMode_Spare2" 5 "GearSelectionMode_Spare1" 4 "GearSelectionMode_Manual" 3 "GearSelectionMode_Automatic" 2 "GearSelectionMode_Neutral" 1 "GearSelectionMode_Reverse" 0 "GearSelectionMode_FoldAway" ;
VAL_ 514 WaterInFuelDrainRequest 3 "Request_NotAvailable" 2 "Request_Error" 1 "Request_RequestActive" 0 "Request_NotRequested" ;
VAL_ 514 SW_Mute_ButtonStatus_6_ISig_4 3 "PushButtonStatus_NotAvailable" 2 "PushButtonStatus_Error" 1 "PushButtonStatus_Pushed" 0 "PushButtonStatus_Neutral" ;
VAL_ 514 FuncIndIlluminationLevel_ISig_4 7 "FuncIndIlluminationLevel_NotAvailable" 6 "FuncIndIlluminationLevel_Error" 5 "FuncIndIlluminationLevel_Spare" 4 "FuncIndIlluminationLevel_IlluminationLevel4" 3 "FuncIndIlluminationLevel_IlluminationLevel3" 2 "FuncIndIlluminationLevel_IlluminationLevel2" 1 "FuncIndIlluminationLevel_IlluminationLevel1" 0 "FuncIndIlluminationLevel_IlluminationOff" ;
VAL_ 514 SW_VolDown_ButtonStatus_6_ISig_4 3 "PushButtonStatus_NotAvailable" 2 "PushButtonStatus_Error" 1 "PushButtonStatus_Pushed" 0 "PushButtonStatus_Neutral" ;
VAL_ 514 ResumeRequestForACC 3 "OffOn_NotAvailable" 2 "OffOn_Error" 1 "OffOn_On" 0 "OffOn_Off" ;
VAL_ 514 CACCTimeGapRqst 3 "Selected_NotAvailable" 2 "Selected_Error" 1 "Selected_Selected" 0 "Selected_NotSelected" ;
VAL_ 514 SWSpeedControlAdjustMode 15 "SWSpeedControlAdjustMode_NotAvailable" 14 "SWSpeedControlAdjustMode_Error" 13 "SWSpeedControlAdjustMode_Spare_10" 12 "SWSpeedControlAdjustMode_Spare_09" 11 "SWSpeedControlAdjustMode_Spare_08" 10 "SWSpeedControlAdjustMode_Spare_07" 9 "SWSpeedControlAdjustMode_Spare_06" 8 "SWSpeedControlAdjustMode_Spare_05" 7 "SWSpeedControlAdjustMode_Spare_04" 6 "SWSpeedControlAdjustMode_Spare_03" 5 "SWSpeedControlAdjustMode_Spare_02" 4 "SWSpeedControlAdjustMode_Spare_01" 3 "SWSpeedControlAdjustMode_Spare" 2 "SWSpeedControlAdjustMode_AdjustTimeGap" 1 "SWSpeedControlAdjustMode_AdjustOverspeed" 0 "SWSpeedControlAdjustMode_AdjustSpeed" ;
VAL_ 514 ACCTimeGapRqst 7 "ACCTimeGapRqst_Unavailable" 6 "ACCTimeGapRqst_Error" 5 "ACCTimeGapRqst_Spare" 4 "ACCTimeGapRqst_Set5" 3 "ACCTimeGapRqst_Set4" 2 "ACCTimeGapRqst_Set3" 1 "ACCTimeGapRqst_Set2" 0 "ACCTimeGapRqst_Set1" ;
VAL_ 514 SWSpdCtrlButtonsStatus6 15 "SWSpdCtrlButtonsStatus6_NotAvailable" 14 "SWSpdCtrlButtonsStatus6_Error" 13 "SWSpdCtrlButtonsStatus6_Spare04" 12 "SWSpdCtrlButtonsStatus6_Spare03" 11 "SWSpdCtrlButtonsStatus6_Spare02" 10 "SWSpdCtrlButtonsStatus6_Spare01" 9 "SWSpdCtrlButtonsStatus6_TimeGap" 8 "SWSpdCtrlButtonsStatus6_DHC" 7 "SWSpdCtrlButtonsStatus6_EcoSettings" 6 "SWSpdCtrlButtonsStatus6_CC_ACC" 5 "SWSpdCtrlButtonsStatus6_Enter" 4 "SWSpdCtrlButtonsStatus6_Decrease" 3 "SWSpdCtrlButtonsStatus6_Increase" 2 "SWSpdCtrlButtonsStatus6_Resume" 1 "SWSpdCtrlButtonsStatus6_PauseOff" 0 "SWSpdCtrlButtonsStatus6_None" ;
VAL_ 514 ACCEnableRqst 3 "DisableEnable_NotAvailable" 2 "DisableEnable_Error" 1 "DisableEnable_Enable" 0 "DisableEnable_Disable" ;
VAL_ 514 StopAlert_cmd 7 "Telltale_cmd_NotAvailable" 6 "Telltale_cmd_ErrorIndication" 5 "Telltale_cmd_Spare_02" 4 "Telltale_cmd_Spare_01" 3 "Telltale_cmd_Spare" 2 "Telltale_cmd_Flashing" 1 "Telltale_cmd_OnSteady" 0 "Telltale_cmd_Off" ;
VAL_ 514 SW_VolUp_ButtonStatus_6_ISig_4 3 "PushButtonStatus_NotAvailable" 2 "PushButtonStatus_Error" 1 "PushButtonStatus_Pushed" 0 "PushButtonStatus_Neutral" ;
VAL_ 514 BacklightCmd_ISig_4 31 "BacklightCmd_NotAvailable" 30 "BacklightCmd_Error" 16 "BacklightCmd_BacklightLevel16" 15 "BacklightCmd_BacklightLevel15" 14 "BacklightCmd_BacklightLevel14" 13 "BacklightCmd_BacklightLevel13" 12 "BacklightCmd_BacklightLevel12" 11 "BacklightCmd_BacklightLevel11" 10 "BacklightCmd_BacklightLevel10" 9 "BacklightCmd_BacklightLevel9" 8 "BacklightCmd_BacklightLevel8" 7 "BacklightCmd_BacklightLevel7" 6 "BacklightCmd_BacklightLevel6" 5 "BacklightCmd_BacklightLevel5" 4 "BacklightCmd_BacklightLevel4" 3 "BacklightCmd_BacklightLevel3" 2 "BacklightCmd_BacklightLevel2" 1 "BacklightCmd_BacklightLevel1" 0 "BacklightCmd_BacklightOff" ;
VAL_ 514 CMTelltale_stat 7 "Telltale_cmd_NotAvailable" 6 "Telltale_cmd_ErrorIndication" 5 "Telltale_cmd_Spare_02" 4 "Telltale_cmd_Spare_01" 3 "Telltale_cmd_Spare" 2 "Telltale_cmd_Flashing" 1 "Telltale_cmd_OnSteady" 0 "Telltale_cmd_Off" ;
VAL_ 1282 EngineFuelMode 3 "FuelMode_NotAvailable" 2 "FuelMode_Error" 1 "FuelMode_RunOnDiesel" 0 "FuelMode_RunOnGas" ;
VAL_ 1282 LNGOperatorInducementReason_ISig 7 "LNGOperatorInducementReason_NotAvailable" 6 "LNGOperatorInducementReason_Error" 5 "LNGOperatorInducementReason_Spare2" 4 "LNGOperatorInducementReason_Spare1" 3 "LNGOperatorInducementReason_IncorrectConsumption" 2 "LNGOperatorInducementReason_GasSupplyMalfunction" 1 "LNGOperatorInducementReason_LNGLevelLow" 0 "LNGOperatorInducementReason_OK" ;
VAL_ 1374 MIStatus_ISig_4 3 "OffOn_NotAvailable" 2 "OffOn_Error" 1 "OffOn_On" 0 "OffOn_Off" ;
VAL_ 1374 TorqueReductionStatus_OBD 7 "TorqueReductionStatus_OBD_NotAvailable" 6 "TorqueReductionStatus_OBD_Error" 5 "TorqueReductionStatus_OBD_Spare_01" 4 "TorqueReductionStatus_OBD_Spare" 3 "TorqueReductionStatus_OBD_TorqueReductionActive" 2 "TorqueReductionStatus_OBD_TorqueReductionActiveNextStandstill" 1 "TorqueReductionStatus_OBD_Pending" 0 "TorqueReductionStatus_OBD_NotActive" ;
VAL_ 1374 SCROperatorInducementSeverity 7 "SCROperatorInducementSeverity_NotAvailable" 6 "SCROperatorInducementSeverity_Reserved" 5 "SCROperatorInducementSeverity_SevereInducementActive" 4 "SCROperatorInducementSeverity_SevereIndEnabledWaitActCondition" 3 "SCROperatorInducementSeverity_IndLevel3LowLevelInducementActive" 2 "SCROperatorInducementSeverity_IndLevel2IntensiveWarning" 1 "SCROperatorInducementSeverity_IndLevel1InitialWarning" 0 "SCROperatorInducementSeverity_NoInducementActive" ;
VAL_ 1374 SCROperatorInducementReason 7 "SCROperatorInducementReason_NotAvailable" 6 "SCROperatorInducementReason_Error" 5 "SCROperatorInducementReason_Spare" 4 "SCROperatorInducementReason_Tampering" 3 "SCROperatorInducementReason_IncorrectConsumption" 2 "SCROperatorInducementReason_IncorrectQuality" 1 "SCROperatorInducementReason_ReagentLevelLow" 0 "SCROperatorInducementReason_OK" ;
VAL_ 1374 MIDistinctWarning 3 "OffOn_NotAvailable" 2 "OffOn_Error" 1 "OffOn_On" 0 "OffOn_Off" ;
VAL_ 1374 MIStatusExtEMS 3 "MIStatusExt_NotAvailable" 2 "MIStatusExt_Error" 1 "MIStatusExt_Ready" 0 "MIStatusExt_NotReady5Flash" ;
VAL_ 1374 MIDistinctWarningExtEMS_ISig_4 15 "MIDistinctWarningExt_NotAvailable" 14 "MIDistinctWarningExt_Error" 3 "MIDistinctWarningExt_ContinuousMISteady" 2 "MIDistinctWarningExt_ShortMI3Flash" 1 "MIDistinctWarningExt_OnDemandMI2Flash" 0 "MIDistinctWarningExt_Off1Flash" ;
VAL_ 1391 OilPrediction_Quality 7 "OilQuality_NotAvailable" 6 "OilQuality_Error" 5 "OilQuality_NoSelectionMade" 4 "OilQuality_VDS4" 3 "OilQuality_VDS3" 2 "OilQuality_VDS5" 1 "OilQuality_VDSVDS3WithFixedInterval" 0 "OilQuality_NonVDS_VDS4WithFixedInterval" ;
VAL_ 1391 OilPrediction_Status 7 "OilStatus_NotAvailable" 6 "OilStatus_Error" 5 "OilStatus_Spare" 4 "OilStatus_Ok" 3 "OilStatus_ServiceNearDue" 2 "OilStatus_ServiceDue" 1 "OilStatus_ServiceOverDue" 0 "OilStatus_NotActive" ;
VAL_ 1276 DMSDriverFollow 3 "DMSDriverFollow_NotAvailable" 2 "DMSDriverFollow_Error" 1 "DMSDriverFollow_AdviseFollowed" 0 "DMSDriverFollow_AdviseNotFollowed" ;
VAL_ 1276 DPF_ParkedRegenStatus 7 "ParkedRegenStatus_NotAvailable" 6 "ParkedRegenStatus_Error" 5 "ParkedRegenStatus_Spare2" 4 "ParkedRegenStatus_HCRegenOngoing" 3 "ParkedRegenStatus_ParkedRegenOngoing" 2 "ParkedRegenStatus_Aborted" 1 "ParkedRegenStatus_Completed" 0 "ParkedRegenStatus_NoInformation" ;
VAL_ 1276 FuelEcoEngStatus 3 "InactiveActive_NotAvailable" 2 "InactiveActive_Error" 1 "InactiveActive_Active" 0 "InactiveActive_Inactive" ;
VAL_ 1291 DrainPrimingStatus_ISig_4 7 "DrainPrimingStatus_NotAvailable" 6 "DrainPrimingStatus_Error" 5 "DrainPrimingStatus_SpareValue_01" 4 "DrainPrimingStatus_SpareValue" 3 "DrainPrimingStatus_DrainingActive" 2 "DrainPrimingStatus_PrimingActive" 1 "DrainPrimingStatus_DrainingPrimingNotAllowed" 0 "DrainPrimingStatus_DrainingPrimingInactive" ;
VAL_ 1291 CoolantTempHigh_ISig_4 7 "TempHigh3bit_NotAvailable" 6 "TempHigh3bit_Error" 5 "TempHigh3bit_HighLevel5" 4 "TempHigh3bit_HighLevel4" 3 "TempHigh3bit_HighLevel3" 2 "TempHigh3bit_HighLevel2" 1 "TempHigh3bit_HighLevel1" 0 "TempHigh3bit_OK" ;
VAL_ 1291 CoolantLevelLow_ISig_4 7 "LevelLow3bit_NotAvailable" 6 "LevelLow3bit_Error" 5 "LevelLow3bit_LowLevel5" 4 "LevelLow3bit_LowLevel4" 3 "LevelLow3bit_LowLevel3" 2 "LevelLow3bit_LowLevel2" 1 "LevelLow3bit_LowLevel1" 0 "LevelLow3bit_OK" ;
VAL_ 1291 AutoWheelBrakesStatus 7 "AutoWheelBrakesStatus_NotAvailable" 6 "AutoWheelBrakesStatus_Error" 5 "AutoWheelBrakesStatus_Spare3" 4 "AutoWheelBrakesStatus_Spare2" 3 "AutoWheelBrakesStatus_AWBActive" 2 "AutoWheelBrakesStatus_ReducedAutoBraking_WithoutSerBrkDemand" 1 "AutoWheelBrakesStatus_FullAutoBraking_withSerBrksDemand" 0 "AutoWheelBrakesStatus_NoAutoBrakingActive" ;
VAL_ 1291 OilPressureLow_ISig_4 7 "LevelLow3bit_NotAvailable" 6 "LevelLow3bit_Error" 5 "LevelLow3bit_LowLevel5" 4 "LevelLow3bit_LowLevel4" 3 "LevelLow3bit_LowLevel3" 2 "LevelLow3bit_LowLevel2" 1 "LevelLow3bit_LowLevel1" 0 "LevelLow3bit_OK" ;
VAL_ 1291 TopGearMode_ISig_4 3 "TopGearMode_NotAvailable" 2 "TopGearMode_Error" 1 "TopGearMode_Active" 0 "TopGearMode_NotActive" ;
VAL_ 1291 OilLevelLow_ISig_4 7 "LevelLow3bit_NotAvailable" 6 "LevelLow3bit_Error" 5 "LevelLow3bit_LowLevel5" 4 "LevelLow3bit_LowLevel4" 3 "LevelLow3bit_LowLevel3" 2 "LevelLow3bit_LowLevel2" 1 "LevelLow3bit_LowLevel1" 0 "LevelLow3bit_OK" ;
VAL_ 1291 InletAirHeaterStatus1 3 "OffOn_NotAvailable" 2 "OffOn_Error" 1 "OffOn_On" 0 "OffOn_Off" ;
VAL_ 1279 FuelFilterClogged 7 "LevelLow3bit_NotAvailable" 6 "LevelLow3bit_Error" 5 "LevelLow3bit_LowLevel5" 4 "LevelLow3bit_LowLevel4" 3 "LevelLow3bit_LowLevel3" 2 "LevelLow3bit_LowLevel2" 1 "LevelLow3bit_LowLevel1" 0 "LevelLow3bit_OK" ;
VAL_ 1279 EngineFanOverspeed 3 "NoYes_NotAvailable" 2 "NoYes_Error" 1 "NoYes_Yes" 0 "NoYes_No" ;
VAL_ 1279 EngineProtDerateStat 3 "InactiveActive_NotAvailable" 2 "InactiveActive_Error" 1 "InactiveActive_Active" 0 "InactiveActive_Inactive" ;
VAL_ 1279 AirFilterPressureDrop 7 "AirFilterPressureDrop_NotAvailable" 6 "AirFilterPressureDrop_Error" 5 "AirFilterPressureDrop_AirFilterPressureDropLevel5" 4 "AirFilterPressureDrop_AirFilterPressureDropLevel4" 3 "AirFilterPressureDrop_AirFilterPressureDropLevel3" 2 "AirFilterPressureDrop_AirFilterPressureDropLevel2" 1 "AirFilterPressureDrop_AirFilterPressureDropLevel1" 0 "AirFilterPressureDrop_OK" ;
VAL_ 733 DPF_LimitedSpeedDuetoInhibit 7 "LimitedSpeedInhibit_NotAvailable" 6 "LimitedSpeedInhibit_Error" 5 "LimitedSpeedInhibit_Spare2" 4 "LimitedSpeedInhibit_Spare1" 3 "LimitedSpeedInhibit_SpeedNotLimited_InhibitActive" 2 "LimitedSpeedInhibit_SpeedNotLimited_InhibitDenied" 1 "LimitedSpeedInhibit_SpeedLimited_InhibitionActive" 0 "LimitedSpeedInhibit_SpeedNotLimited_NoInhibitRequest" ;
VAL_ 733 XARSystemState 3 "XARSystemState_NotAvailable" 2 "XARSystemState_Error" 1 "XARSystemState_NoExternalAccelerationDemandWillBeAccepted" 0 "XARSystemState_AnyExternalAccelerationDemandWillBeAccepted" ;
VAL_ 733 XARActiveControlMode 7 "XARActiveControlMode_NotAvailable" 6 "XARActiveControlMode_Error" 5 "XARActiveControlMode_Spare_2" 4 "XARActiveControlMode_Spare_1" 3 "XARActiveControlMode_CoastingActive" 2 "XARActiveControlMode_DriversAccelerationDemandExecuted" 1 "XARActiveControlMode_AccelerationControlMaximumMode" 0 "XARActiveControlMode_OverrideDisabled" ;
VAL_ 719 CCControllerMode_ISig_4 7 "ControllerMode_Not_availbale" 6 "ControllerMode_Error" 5 "ControllerMode_Spare_01" 4 "ControllerMode_Spare" 3 "ControllerMode_Inhibited" 2 "ControllerMode_Active_no_torque" 1 "ControllerMode_Active_torque" 0 "ControllerMode_Inactive" ;
VAL_ 719 CrankcasePressureHigh_ISig_4 3 "Warning_NotAvailable" 2 "Warning_Error" 1 "Warning_Warning" 0 "Warning_NoWarning" ;
VAL_ 719 EngineSystemPowerDownAck 3 "EngineSystemPowerDownAck_NotAvailable" 2 "EngineSystemPowerDownAck_Error" 1 "EngineSystemPowerDownAck_NotOkToPowerDownEMS" 0 "EngineSystemPowerDownAck_OkToPowerDownEMS" ;
VAL_ 719 EngineActiveStatus_ISig_4 15 "EngineActiveStatus_NotAvailable" 14 "EngineActiveStatus_Error" 13 "EngineActiveStatus_Spare_10" 12 "EngineActiveStatus_Spare_09" 11 "EngineActiveStatus_Spare_08" 10 "EngineActiveStatus_Spare_07" 9 "EngineActiveStatus_Spare_06" 8 "EngineActiveStatus_Spare_05" 7 "EngineActiveStatus_Spare_04" 6 "EngineActiveStatus_Spare_03" 5 "EngineActiveStatus_Spare_02" 4 "EngineActiveStatus_Spare_01" 3 "EngineActiveStatus_DrivelineStandby" 2 "EngineActiveStatus_ElectricPropulsionSystemRunning" 1 "EngineActiveStatus_InternalCombustionEngineRunning" 0 "EngineActiveStatus_DrivelineNotActive" ;
VAL_ 719 XRSLControllerMode 3 "InactiveActive_NotAvailable" 2 "InactiveActive_Error" 1 "InactiveActive_Active" 0 "InactiveActive_Inactive" ;
VAL_ 719 RegenInhibDueHeight 3 "Inhibit_NotAvailable" 2 "Inhibit_Error" 1 "Inhibit_InhibitActive" 0 "Inhibit_NoInhibit" ;
VAL_ 719 ExhManif_AirInjActive_ISig_4 3 "InhibitedStatus_NotAvailable" 2 "InhibitedStatus_Error" 1 "InhibitedStatus_Inhibited" 0 "InhibitedStatus_NotInhibited" ;
VAL_ 719 CCBControllerMode 7 "ControllerMode_Not_availbale" 6 "ControllerMode_Error" 5 "ControllerMode_Spare_01" 4 "ControllerMode_Spare" 3 "ControllerMode_Inhibited" 2 "ControllerMode_Active_no_torque" 1 "ControllerMode_Active_torque" 0 "ControllerMode_Inactive" ;
VAL_ 719 InhibitIdleShutdownStatus 7 "InhibitIdleShutdownStatus_NotAvailableNoInhibit" 6 "InhibitIdleShutdownStatus_ErrorIndicator" 5 "InhibitIdleShutdownStatus_InhibitReasonUndefined" 4 "InhibitIdleShutdownStatus_InhibitReasonReserved_02" 3 "InhibitIdleShutdownStatus_InhibitReasonReserved_01" 2 "InhibitIdleShutdownStatus_InhibitReasonReserved" 1 "InhibitIdleShutdownStatus_InhibitDPFRegeneration" 0 "InhibitIdleShutdownStatus_NoInhibit" ;
VAL_ 719 EngCompartmentStopSwitchStat 3 "EngCompartmentStopSwitchStat_NotAvailable" 2 "EngCompartmentStopSwitchStat_Error" 1 "EngCompartmentStopSwitchStat_ShutdownRequested" 0 "EngCompartmentStopSwitchStat_NoAction" ;
VAL_ 719 EngineStartAuth_rqst 7 "EngineStartAuth_rqst_NotAvailable" 6 "EngineStartAuth_rqst_Error" 5 "EngineStartAuth_rqst_Spare_03" 4 "EngineStartAuth_rqst_Spare_02" 3 "EngineStartAuth_rqst_Spare_01" 2 "EngineStartAuth_rqst_Spare" 1 "EngineStartAuth_rqst_StartingOfTheTruckRequested" 0 "EngineStartAuth_rqst_StartingOfTheTruckNotRequested" ;
VAL_ 719 IntakeAirTemperatureAlert 3 "InactiveActive_NotAvailable" 2 "InactiveActive_Error" 1 "InactiveActive_Active" 0 "InactiveActive_Inactive" ;
VAL_ 719 EngineOilTempHigh_ISig_4 7 "TempHigh3bit_NotAvailable" 6 "TempHigh3bit_Error" 5 "TempHigh3bit_HighLevel5" 4 "TempHigh3bit_HighLevel4" 3 "TempHigh3bit_HighLevel3" 2 "TempHigh3bit_HighLevel2" 1 "TempHigh3bit_HighLevel1" 0 "TempHigh3bit_OK" ;
VAL_ 719 WarmUpCycle 3 "WarmUpCycle_NotAvailable" 2 "WarmUpCycle_Error" 1 "WarmUpCycle_TransitionTo1MeansWarmUpCycleOccur" 0 "WarmUpCycle_TransitionTo0MeansWarmUpCycleOccur" ;
SIG_GROUP_ 1414 GPSData_sg_ISig_4_586 1 : GPSData_Altitude_ISig_4_586 GPSData_Longitude_ISig_4_586 GPSData_HDOP_ISig_4_586 GPSData_Direction_ISig_4_586 GPSData_Time_ISig_4_586 GPSData_VehSpeed_ISig_4_586 GPSData_AntennaStat_ISig_4_586 GPSData_Latitude_ISig_4_586;
SIG_GROUP_ 1381 GPSData_sg_ISig_4_565 1 : GPSData_HDOP_ISig_4_565 GPSData_VehSpeed_ISig_4_565 GPSData_AntennaStat_ISig_4_565 GPSData_Latitude_ISig_4_565 GPSData_Time_ISig_4_565 GPSData_Direction_ISig_4_565 GPSData_Longitude_ISig_4_565 GPSData_Altitude_ISig_4_565;
SIG_GROUP_ 1386 GPSData_sg_ISig_4_56a 1 : GPSData_HDOP_ISig_4_56a GPSData_Latitude_ISig_4_56a GPSData_Time_ISig_4_56a GPSData_Direction_ISig_4_56a GPSData_AntennaStat_ISig_4_56a GPSData_Longitude_ISig_4_56a GPSData_VehSpeed_ISig_4_56a GPSData_Altitude_ISig_4_56a;
SIG_GROUP_ 1384 GPSData_sg_ISig_4_568 1 : GPSData_Time_ISig_4_568 GPSData_HDOP_ISig_4_568 GPSData_Direction_ISig_4_568 GPSData_Longitude_ISig_4_568 GPSData_VehSpeed_ISig_4_568 GPSData_Altitude_ISig_4_568 GPSData_Latitude_ISig_4_568 GPSData_AntennaStat_ISig_4_568;
SIG_GROUP_ 1270 SpeedAdaptEnableRqst_sg 1 : SpeedAdaptEnableRqst_SpeedLimit SpeedAdaptEnableRqst_Curve SpeedAdaptEnableRqst_SlowTraffic;
SIG_GROUP_ 1270 ExtTimeData_sg_ISig_4 1 : ExtTimeData_ExtTime_ISig_4 ExtTimeData_Quality_ISig_4;
SIG_GROUP_ 1391 OilPrediction_sg 1 : OilPrediction_Quality OilPrediction_RemainDist OilPrediction_RemainTime OilPrediction_Status;
SIG_GROUP_ 733 AirFilter_sg 1 : AirFilter_AirMassFlowValidated AirFilter_Pressure;
